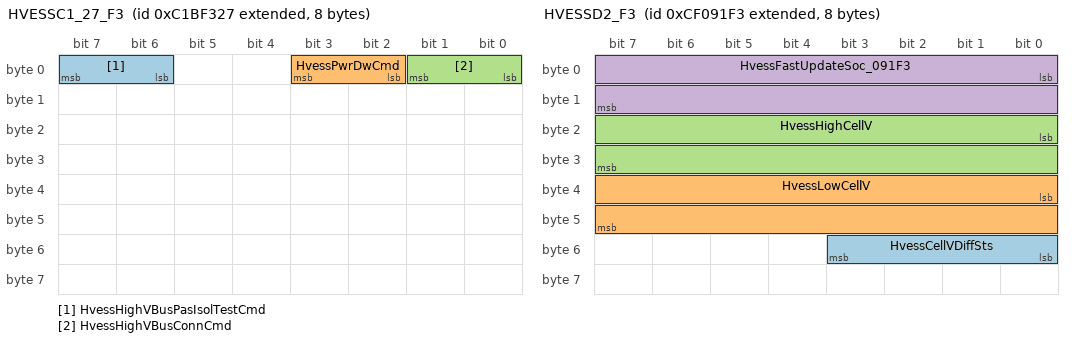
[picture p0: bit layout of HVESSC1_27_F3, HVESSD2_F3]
BO_ 2350641959 HVESSC1_27_F3: 8 VCM
 SG_ HvessHighVBusPasIsolTestCmd : 6|2@1+ (1,0) [0|3] ""  PCM,NODE_F3
 SG_ HvessPwrDwCmd : 2|2@1+ (1,0) [0|3] ""  PCM,NODE_F3
 SG_ HvessHighVBusConnCmd : 0|2@1+ (1,0) [0|3] ""  PCM,NODE_F3

BO_ 2350589939 HVESSC1_F3_27: 8 NODE_F3
 SG_ HvessCellBalCmd : 8|2@1+ (1,0) [0|3] ""  PCM,VCM

BO_ 2364576039 HVESSD2_27: 8 VCM
 SG_ HvessFastUpdateSoc : 0|16@1+ (0.0015625,0) [0|100.3984375] "%"  PCM

BO_ 2364576243 HVESSD2_F3: 8 NODE_F3
 SG_ HvessCellVDiffSts : 48|4@1+ (1,0) [0|15] ""  PCM
 SG_ HvessLowCellV : 32|16@1+ (0.001,0) [0|64.255] "V"  PCM
 SG_ HvessHighCellV : 16|16@1+ (0.001,0) [0|64.255] "V"  PCM
 SG_ HvessFastUpdateSoc_091F3 : 0|16@1+ (0.0015625,0) [0|100.3984375] "%"  PCM

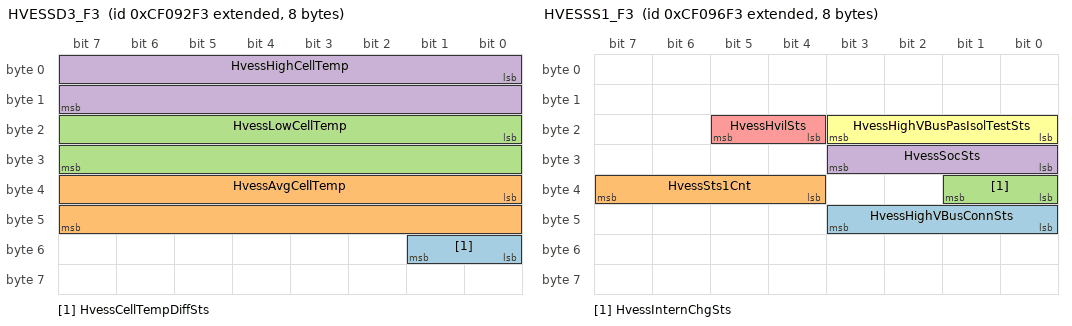
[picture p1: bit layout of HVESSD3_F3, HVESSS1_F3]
BO_ 2364576499 HVESSD3_F3: 8 NODE_F3
 SG_ HvessCellTempDiffSts : 48|2@1+ (1,0) [0|3] ""  PCM
 SG_ HvessAvgCellTemp : 32|16@1+ (0.03125,-273) [-273|1734.96875] "�C"  PCM
 SG_ HvessLowCellTemp : 16|16@1+ (0.03125,-273) [-273|1734.96875] "�C"  PCM
 SG_ HvessHighCellTemp : 0|16@1+ (0.03125,-273) [-273|1734.96875] "�C"  PCM

BO_ 2364577063 HVESSD6_27: 8 VCM
 SG_ HvessTemp : 56|8@1+ (1,-40) [-40|210] "�C"  PCM

BO_ 2364577523 HVESSS1_F3: 8 NODE_F3
 SG_ HvessHighVBusConnSts : 40|4@1+ (1,0) [0|15] ""  PCM
 SG_ HvessSts1Cnt : 36|4@1+ (1,0) [0|15] ""  PCM
 SG_ HvessInternChgSts : 32|2@1+ (1,0) [0|3] ""  PCM
 SG_ HvessSocSts : 24|4@1+ (1,0) [0|15] ""  PCM
 SG_ HvessHvilSts : 20|2@1+ (1,0) [0|3] ""  PCM
 SG_ HvessHighVBusPasIsolTestSts : 16|4@1+ (1,0) [0|15] ""  PCM

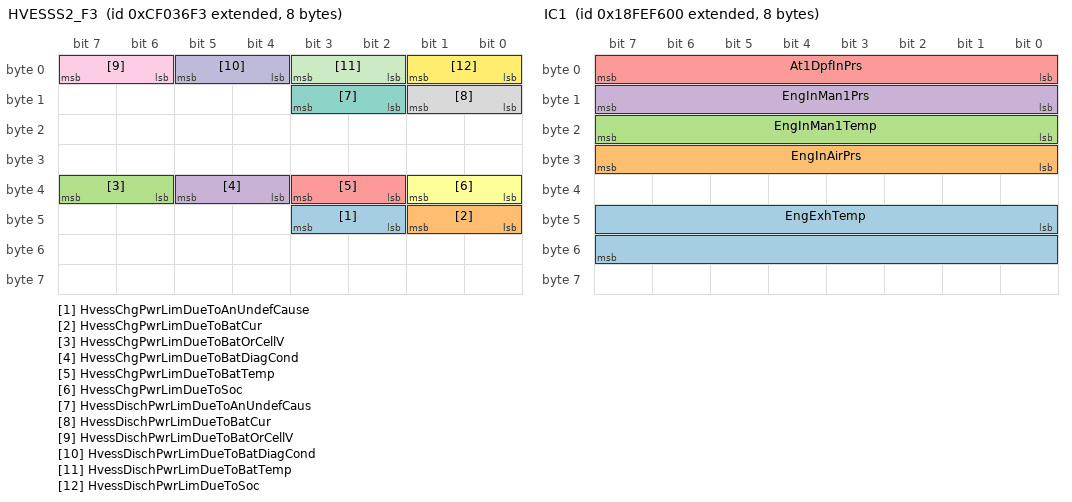
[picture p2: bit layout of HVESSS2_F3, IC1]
BO_ 2364552947 HVESSS2_F3: 8 NODE_F3
 SG_ HvessChgPwrLimDueToAnUndefCause : 42|2@1+ (1,0) [0|3] ""  PCM
 SG_ HvessChgPwrLimDueToBatCur : 40|2@1+ (1,0) [0|3] ""  PCM
 SG_ HvessChgPwrLimDueToBatOrCellV : 38|2@1+ (1,0) [0|3] ""  PCM
 SG_ HvessChgPwrLimDueToBatDiagCond : 36|2@1+ (1,0) [0|3] ""  PCM
 SG_ HvessChgPwrLimDueToBatTemp : 34|2@1+ (1,0) [0|3] ""  PCM
 SG_ HvessChgPwrLimDueToSoc : 32|2@1+ (1,0) [0|3] ""  PCM
 SG_ HvessDischPwrLimDueToAnUndefCaus : 10|2@1+ (1,0) [0|3] ""  PCM
 SG_ HvessDischPwrLimDueToBatCur : 8|2@1+ (1,0) [0|3] ""  PCM
 SG_ HvessDischPwrLimDueToBatOrCellV : 6|2@1+ (1,0) [0|3] ""  PCM
 SG_ HvessDischPwrLimDueToBatDiagCond : 4|2@1+ (1,0) [0|3] ""  PCM
 SG_ HvessDischPwrLimDueToBatTemp : 2|2@1+ (1,0) [0|3] ""  PCM
 SG_ HvessDischPwrLimDueToSoc : 0|2@1+ (1,0) [0|3] ""  PCM

BO_ 2566845952 IC1: 8 ECM
 SG_ EngExhTemp : 40|16@1+ (0.03125,-273) [-273|1734.96875] "�C"  PCM
 SG_ EngInAirPrs : 24|8@1+ (2,0) [0|500] "kPa"  PCM
 SG_ EngInMan1Temp : 16|8@1+ (1,-40) [-40|210] "�C"  PCM
 SG_ EngInMan1Prs : 8|8@1+ (2,0) [0|500] "kPa"  PCM
 SG_ At1DpfInPrs : 0|8@1+ (0.5,0) [0|125] "kPa"  PCM

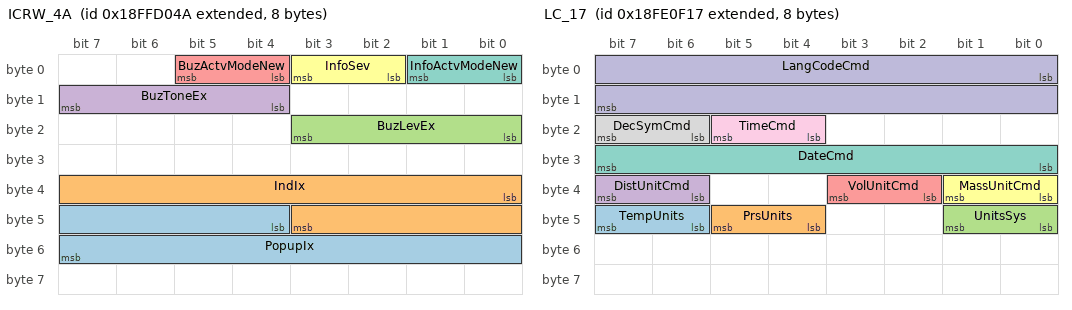
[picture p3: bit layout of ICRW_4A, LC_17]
BO_ 2566901834 ICRW_4A: 8 PCM
 SG_ PopupIx : 44|12@1+ (1,0) [0|4095] "" Vector__XXX
 SG_ IndIx : 32|12@1+ (1,0) [0|4095] "" Vector__XXX
 SG_ BuzLevEx : 16|4@1+ (1,0) [0|15] "Volume Units" Vector__XXX
 SG_ BuzToneEx : 12|4@1+ (1,0) [0|15] "" Vector__XXX
 SG_ BuzActvModeNew : 4|2@1+ (1,0) [0|3] "" Vector__XXX
 SG_ InfoSev : 2|2@1+ (1,0) [0|3] "" Vector__XXX
 SG_ InfoActvModeNew : 0|2@1+ (1,0) [0|3] "" Vector__XXX

BO_ 2566769185 ISC_21: 8 BCM
 SG_ EngOpPriInterSpeedSel : 0|4@1+ (1,0) [0|15] ""  PCM

BO_ 2566786839 LC_17: 8 ICC
 SG_ TempUnits : 46|2@1+ (1,0) [0|3] ""  PCM
 SG_ PrsUnits : 44|2@1+ (1,0) [0|3] ""  PCM
 SG_ UnitsSys : 40|2@1+ (1,0) [0|3] ""  PCM
 SG_ DistUnitCmd : 38|2@1+ (1,0) [0|3] ""  PCM
 SG_ VolUnitCmd : 34|2@1+ (1,0) [0|3] ""  PCM
 SG_ MassUnitCmd : 32|2@1+ (1,0) [0|3] ""  PCM
 SG_ DateCmd : 24|8@1+ (1,0) [0|255] "binary"  PCM
 SG_ DecSymCmd : 22|2@1+ (1,0) [0|3] ""  PCM
 SG_ TimeCmd : 20|2@1+ (1,0) [0|3] ""  PCM
 SG_ LangCodeCmd : 0|16@1+ (1,0) [0|255] "ASCII"  PCM

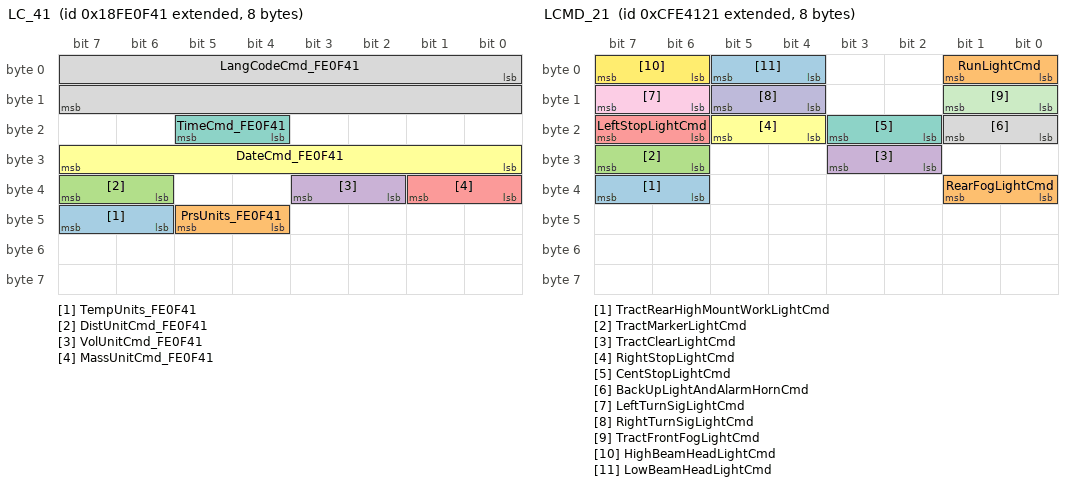
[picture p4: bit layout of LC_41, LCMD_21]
BO_ 2566786881 LC_41: 8 NIS_RDR
 SG_ TempUnits_FE0F41 : 46|2@1+ (1,0) [0|3] ""  PCM
 SG_ PrsUnits_FE0F41 : 44|2@1+ (1,0) [0|3] ""  PCM
 SG_ DistUnitCmd_FE0F41 : 38|2@1+ (1,0) [0|3] ""  PCM
 SG_ VolUnitCmd_FE0F41 : 34|2@1+ (1,0) [0|3] ""  PCM
 SG_ MassUnitCmd_FE0F41 : 32|2@1+ (1,0) [0|3] ""  PCM
 SG_ DateCmd_FE0F41 : 24|8@1+ (1,0) [0|255] "binary"  PCM
 SG_ TimeCmd_FE0F41 : 20|2@1+ (1,0) [0|3] ""  PCM
 SG_ LangCodeCmd_FE0F41 : 0|16@1+ (1,0) [0|255] "ASCII"  PCM

BO_ 2365473057 LCMD_21: 8 BCM
 SG_ TractRearHighMountWorkLightCmd : 38|2@1+ (1,0) [0|3] ""  PCM
 SG_ RearFogLightCmd : 32|2@1+ (1,0) [0|3] ""  PCM
 SG_ TractMarkerLightCmd : 30|2@1+ (1,0) [0|3] ""  PCM
 SG_ TractClearLightCmd : 26|2@1+ (1,0) [0|3] ""  PCM
 SG_ LeftStopLightCmd : 22|2@1+ (1,0) [0|3] ""  PCM
 SG_ RightStopLightCmd : 20|2@1+ (1,0) [0|3] ""  PCM
 SG_ CentStopLightCmd : 18|2@1+ (1,0) [0|3] ""  PCM
 SG_ BackUpLightAndAlarmHornCmd : 16|2@1+ (1,0) [0|3] ""  PCM
 SG_ LeftTurnSigLightCmd : 14|2@1+ (1,0) [0|3] ""  PCM
 SG_ RightTurnSigLightCmd : 12|2@1+ (1,0) [0|3] ""  PCM
 SG_ TractFrontFogLightCmd : 8|2@1+ (1,0) [0|3] ""  PCM
 SG_ HighBeamHeadLightCmd : 6|2@1+ (1,0) [0|3] ""  PCM
 SG_ LowBeamHeadLightCmd : 4|2@1+ (1,0) [0|3] ""  PCM
 SG_ RunLightCmd : 0|2@1+ (1,0) [0|3] ""  PCM

BO_ 2365473066 LCMD_2A: 8 LDW
 SG_ HighBeamHeadLightCmd_E412A : 6|2@1+ (1,0) [0|3] ""  PCM

BO_ 2566842624 LFC1: 8 ECM
 SG_ EngTotFuelUsed : 32|32@1+ (0.5,0) [0|2105540607.5] "L"  PCM

BO_ 2566844928 LFE1: 8 ECM
 SG_ EngInstFuelEcon_FEF200 : 16|16@1+ (0.001953125,0) [0|125.498046875] "km/L"  PCM
 SG_ EngFuelRate_FEF200 : 0|16@1+ (0.05,0) [0|3212.75] "L/h"  PCM

BO_ 2566615335 MG1IMT_27: 8 VCM
 SG_ Mot_Gen1Temp1 : 0|8@1+ (1,-40) [-40|210] "�C"  PCM

BO_ 2365289967 MG1IR1_EF: 8 NODE_EF
 SG_ Mot_Gen1InvRefSpeed : 32|16@1+ (4,0) [0|257020] "rpm"  PCM
 SG_ Mot_Gen1InvRefTrq : 16|16@1+ (0.5,0) [0|32127.5] "Nm"  PCM

BO_ 2365289970 MG1IR1_F2: 8 NODE_F2
 SG_ Mot_Gen1InvRefSpeed_B75F2 : 32|16@1+ (4,0) [0|257020] "rpm"  PCM
 SG_ Mot_Gen1InvRefTrq_B75F2 : 16|16@1+ (0.5,0) [0|32127.5] "Nm"  PCM

BO_ 2365289455 MG1IR2_EF: 8 NODE_EF
 SG_ Mot_Gen1InvRefV : 48|16@1+ (0.125,0) [0|8031.875] "V"  PCM
 SG_ Mot_Gen1InvRefCur : 32|16@1+ (0.125,0) [0|8031.875] "A"  PCM

BO_ 2365289458 MG1IR2_F2: 8 NODE_F2
 SG_ Mot_Gen1InvRefV_B73F2 : 48|16@1+ (0.125,0) [0|8031.875] "V"  PCM
 SG_ Mot_Gen1InvRefCur_B73F2 : 32|16@1+ (0.125,0) [0|8031.875] "A"  PCM

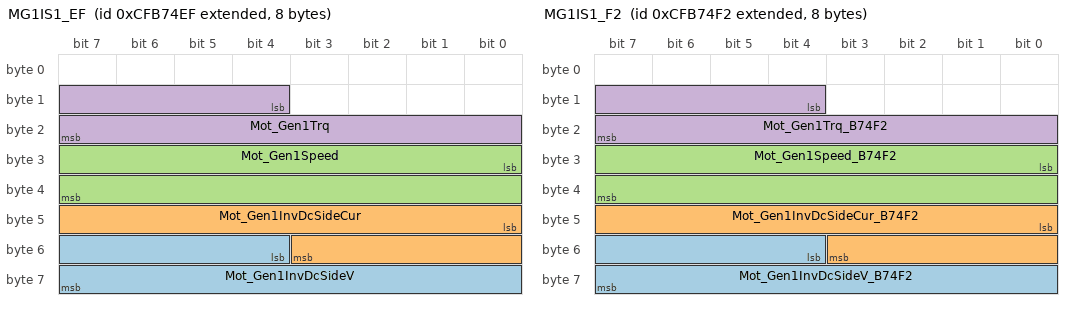
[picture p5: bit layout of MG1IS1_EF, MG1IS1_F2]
BO_ 2365289711 MG1IS1_EF: 8 NODE_EF
 SG_ Mot_Gen1InvDcSideV : 52|12@1+ (0.0625,-125) [-125|125.9375] "%"  PCM
 SG_ Mot_Gen1InvDcSideCur : 40|12@1+ (0.0625,-125) [-125|125.9375] "%"  PCM
 SG_ Mot_Gen1Speed : 24|16@1+ (0.00390625,-125) [-125|125.99609375] "%"  PCM
 SG_ Mot_Gen1Trq : 12|12@1+ (0.0625,-125) [-125|125.9375] "%"  PCM

BO_ 2365289714 MG1IS1_F2: 8 NODE_F2
 SG_ Mot_Gen1InvDcSideV_B74F2 : 52|12@1+ (0.0625,-125) [-125|125.9375] "%"  PCM
 SG_ Mot_Gen1InvDcSideCur_B74F2 : 40|12@1+ (0.0625,-125) [-125|125.9375] "%"  PCM
 SG_ Mot_Gen1Speed_B74F2 : 24|16@1+ (0.00390625,-125) [-125|125.99609375] "%"  PCM
 SG_ Mot_Gen1Trq_B74F2 : 12|12@1+ (0.0625,-125) [-125|125.9375] "%"  PCM

BO_ 2565966831 MG1IS2_EF: 8 NODE_EF
 SG_ Mot_Gen1AvMinTrq : 24|12@1+ (0.0625,-125) [-125|125.9375] "%"  PCM
 SG_ Mot_Gen1AvMaxTrq : 12|12@1+ (0.0625,-125) [-125|125.9375] "%"  PCM

BO_ 2565966834 MG1IS2_F2: 8 NODE_F2
 SG_ Mot_Gen1AvMinTrq_F18BF2 : 24|12@1+ (0.0625,-125) [-125|125.9375] "%"  PCM
 SG_ Mot_Gen1AvMaxTrq_F18BF2 : 12|12@1+ (0.0625,-125) [-125|125.9375] "%"  PCM

BO_ 2566615591 MG1IT_27: 8 VCM
 SG_ Mot_Gen1InvTemp1 : 0|8@1+ (1,-40) [-40|210] "�C"  PCM

BO_ 2566802465 ML_21: 8 BCM
 SG_ OpsBlackOutIntensSel : 56|8@1+ (0.4,0) [0|100] "%"  PCM

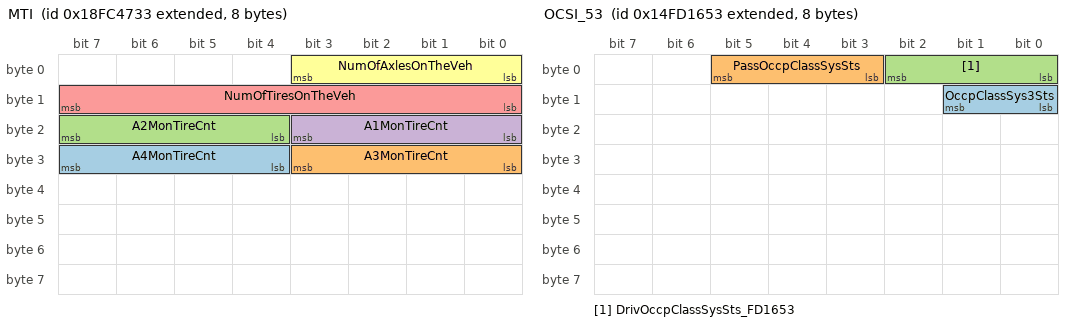
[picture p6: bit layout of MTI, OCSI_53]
BO_ 2566670131 MTI: 8 OptiTire
 SG_ A4MonTireCnt : 28|4@1+ (1,0) [0|13] "count"  PCM
 SG_ A3MonTireCnt : 24|4@1+ (1,0) [0|13] "count"  PCM
 SG_ A2MonTireCnt : 20|4@1+ (1,0) [0|13] "count"  PCM
 SG_ A1MonTireCnt : 16|4@1+ (1,0) [0|13] "count"  PCM
 SG_ NumOfTiresOnTheVeh : 8|8@1+ (1,0) [0|250] "count"  PCM
 SG_ NumOfAxlesOnTheVeh : 0|4@1+ (1,0) [0|13] "count"  PCM

BO_ 2566898977 MuxInfo2: 8 BCM
 SG_ MsgCks_FFC521 : 60|4@1+ (1,0) [0|15] "count"  PCM
 SG_ MsgCnt_FFC521 : 56|4@1+ (1,0) [0|15] "count"  PCM
 SG_ EmerShutdnSwSts : 54|2@1+ (1,0) [0|3] ""  PCM
 SG_ WiperCtrlSts : 51|3@1+ (1,0) [0|7] ""  PCM
 SG_ EassVisCode : 48|3@1+ (1,0) [0|7] ""  PCM
 SG_ EassActvSts : 46|2@1+ (1,0) [0|3] ""  PCM
 SG_ EmerHandKeyLckdSts : 44|2@1+ (1,0) [0|3] ""  PCM
 SG_ BatLampSts : 42|2@1+ (1,0) [0|3] ""  PCM
 SG_ PwrModeSts : 40|2@1+ (1,0) [0|3] ""  PCM
 SG_ FpsSts : 39|1@1+ (1,0) [0|1] ""  PCM
 SG_ ImmoCodeWarnLightSts : 32|4@1+ (1,0) [0|15] ""  PCM
 SG_ BrkPadWearSts : 30|2@1+ (1,0) [0|3] ""  PCM
 SG_ BrkFluidLevLow : 28|2@1+ (1,0) [0|3] ""  PCM
 SG_ CeilLightSts : 26|2@1+ (1,0) [0|3] ""  PCM
 SG_ SysEolSts : 25|1@1+ (1,0) [0|1] ""  PCM
 SG_ BrkPedSts : 24|1@1+ (1,0) [0|1] ""  PCM
 SG_ CrashOutSts : 16|8@1+ (1,0) [0|255] ""  PCM
 SG_ WiperCtrl : 14|2@1+ (1,0) [0|3] ""  PCM
 SG_ VehAtStStill : 12|2@1+ (1,0) [0|3] ""  PCM
 SG_ PlugDoorBtn : 10|2@1+ (1,0) [0|3] ""  PCM
 SG_ EngWaterLev : 8|2@1+ (1,0) [0|3] ""  PCM
 SG_ SpotStsRear : 6|2@1+ (1,0) [0|3] ""  PCM
 SG_ PtoDrivResp : 4|2@1+ (1,0) [0|3] ""  PCM
 SG_ SeatBeltRemindSts : 2|2@1+ (1,0) [0|3] ""  PCM
 SG_ InternLightSts : 1|1@1+ (1,0) [0|1] ""  PCM
 SG_ RechargeSts : 0|1@1+ (1,0) [0|1] ""  PCM

BO_ 2566776106 MVS_2A: 8 LDW
 SG_ MaxVsl3 : 16|8@1+ (1,0) [0|250] "km/h"  PCM
 SG_ MaxVsl2 : 8|8@1+ (1,0) [0|250] "km/h"  PCM

BO_ 2499614241 OCSI_21: 8 BCM
 SG_ DrivOccpClassSysSts : 0|3@1+ (1,0) [0|7] ""  PCM

BO_ 2499614291 OCSI_53: 8 Airbag
 SG_ OccpClassSys3Sts : 8|2@1+ (1,0) [0|3] ""  PCM
 SG_ PassOccpClassSysSts : 3|3@1+ (1,0) [0|7] ""  PCM
 SG_ DrivOccpClassSysSts_FD1653 : 0|3@1+ (1,0) [0|7] ""  PCM

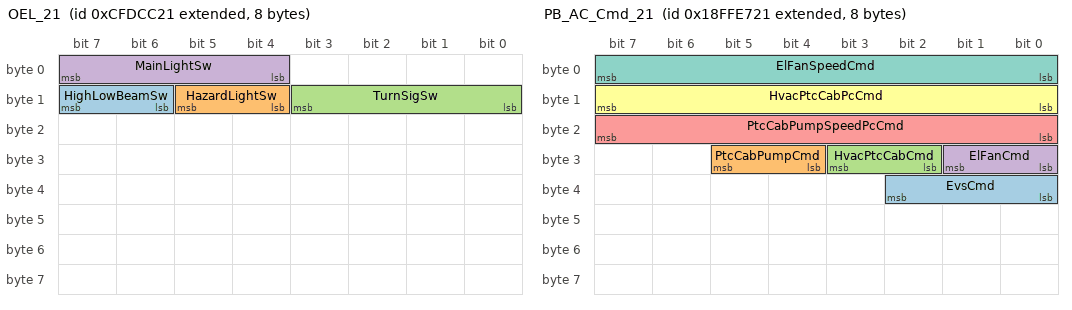
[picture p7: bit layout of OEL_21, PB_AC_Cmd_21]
BO_ 2365443105 OEL_21: 8 BCM
 SG_ HighLowBeamSw : 14|2@1+ (1,0) [0|3] ""  PCM
 SG_ HazardLightSw : 12|2@1+ (1,0) [0|3] ""  PCM
 SG_ TurnSigSw : 8|4@1+ (1,0) [0|15] ""  PCM
 SG_ MainLightSw : 4|4@1+ (1,0) [0|15] ""  PCM

BO_ 2566769953 OWW_21: 8 BCM
 SG_ FrontOpWiperSw : 4|4@1+ (1,0) [0|15] ""  PCM

BO_ 2565865249 PA_E_21: 8 BCM
 SG_ ImmoEmerProc m0 : 48|8@1+ (5,0) [0|1250] "s"  PCM
 SG_ CtrlByte M : 0|8@1+ (1,0) [0|255] "binary"  PCM

BO_ 2566907681 PB_AC_Cmd_21: 8 BCM
 SG_ EvsCmd : 32|3@1+ (1,0) [0|7] ""  PCM
 SG_ PtcCabPumpCmd : 28|2@1+ (1,0) [0|3] ""  PCM
 SG_ HvacPtcCabCmd : 26|2@1+ (1,0) [0|3] ""  PCM
 SG_ ElFanCmd : 24|2@1+ (1,0) [0|3] ""  PCM
 SG_ PtcCabPumpSpeedPcCmd : 16|8@1+ (0.4,0) [0|100] "%"  PCM
 SG_ HvacPtcCabPcCmd : 8|8@1+ (0.4,0) [0|100] "%"  PCM
 SG_ ElFanSpeedCmd : 0|8@1+ (0.4,0) [0|100] "%"  PCM

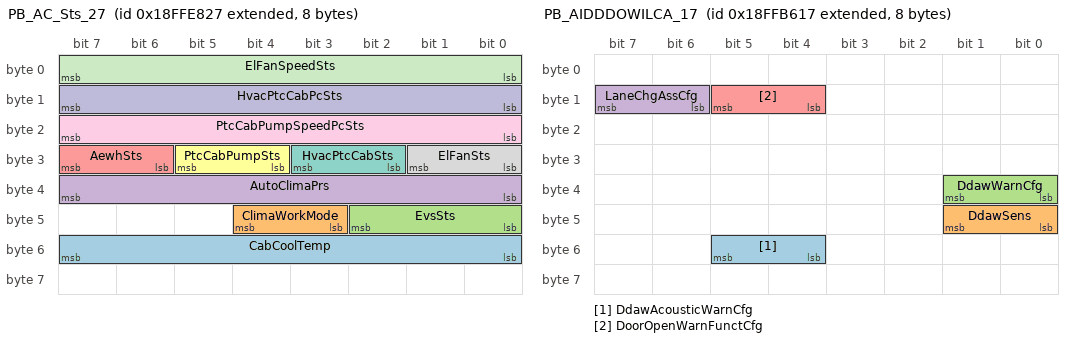
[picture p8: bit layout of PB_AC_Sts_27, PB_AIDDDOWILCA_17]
BO_ 2566907943 PB_AC_Sts_27: 8 VCM
 SG_ CabCoolTemp : 48|8@1+ (1,-40) [-40|210] "�C"  PCM
 SG_ ClimaWorkMode : 43|2@1+ (1,0) [0|3] ""  PCM
 SG_ EvsSts : 40|3@1+ (1,0) [0|7] ""  PCM
 SG_ AutoClimaPrs : 32|8@1+ (12,0) [0|3000] "kPa"  PCM
 SG_ AewhSts : 30|2@1+ (1,0) [0|3] ""  PCM
 SG_ PtcCabPumpSts : 28|2@1+ (1,0) [0|3] ""  PCM
 SG_ HvacPtcCabSts : 26|2@1+ (1,0) [0|3] ""  PCM
 SG_ ElFanSts : 24|2@1+ (1,0) [0|3] ""  PCM
 SG_ PtcCabPumpSpeedPcSts : 16|8@1+ (0.4,0) [0|100] "%"  PCM
 SG_ HvacPtcCabPcSts : 8|8@1+ (0.4,0) [0|100] "%"  PCM
 SG_ ElFanSpeedSts : 0|8@1+ (0.4,0) [0|100] "%"  PCM

BO_ 2566895127 PB_AIDDDOWILCA_17: 8 ICC
 SG_ DdawAcousticWarnCfg : 52|2@1+ (1,0) [0|3] ""  PCM
 SG_ DdawSens : 40|2@1+ (1,0) [0|3] ""  PCM
 SG_ DdawWarnCfg : 32|2@1+ (1,0) [0|3] ""  PCM
 SG_ LaneChgAssCfg : 14|2@1+ (1,0) [0|3] ""  PCM
 SG_ DoorOpenWarnFunctCfg : 12|2@1+ (1,0) [0|3] ""  PCM

BO_ 2566895137 PB_AIDDDOWILCA_21: 8 BCM
 SG_ AlcoholIntLckCrkEnaSts : 42|3@1+ (1,0) [0|7] ""  PCM

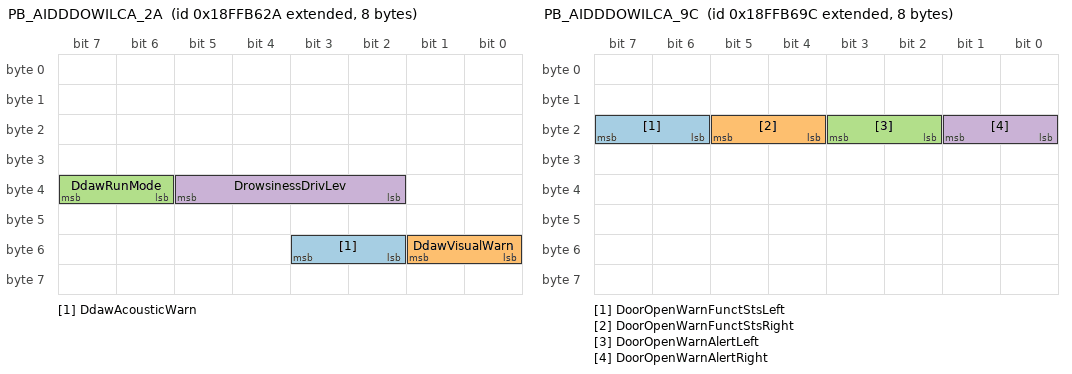
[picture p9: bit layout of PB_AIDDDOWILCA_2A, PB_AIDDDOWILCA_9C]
BO_ 2566895146 PB_AIDDDOWILCA_2A: 8 LDW
 SG_ DdawAcousticWarn : 50|2@1+ (1,0) [0|3] ""  PCM
 SG_ DdawVisualWarn : 48|2@1+ (1,0) [0|3] ""  PCM
 SG_ DdawRunMode : 38|2@1+ (1,0) [0|3] ""  PCM
 SG_ DrowsinessDrivLev : 34|4@1+ (1,0) [0|15] ""  PCM

BO_ 2566895178 PB_AIDDDOWILCA_4A: 8 PCM
 SG_ DoorOpenWarnFunctCfg_FFB64A : 12|2@1+ (1,0) [0|3] "" Vector__XXX

BO_ 2566895260 PB_AIDDDOWILCA_9C: 8 RSRRM
 SG_ DoorOpenWarnFunctStsLeft : 22|2@1+ (1,0) [0|3] ""  PCM
 SG_ DoorOpenWarnFunctStsRight : 20|2@1+ (1,0) [0|3] ""  PCM
 SG_ DoorOpenWarnAlertLeft : 18|2@1+ (1,0) [0|3] ""  PCM
 SG_ DoorOpenWarnAlertRight : 16|2@1+ (1,0) [0|3] ""  PCM

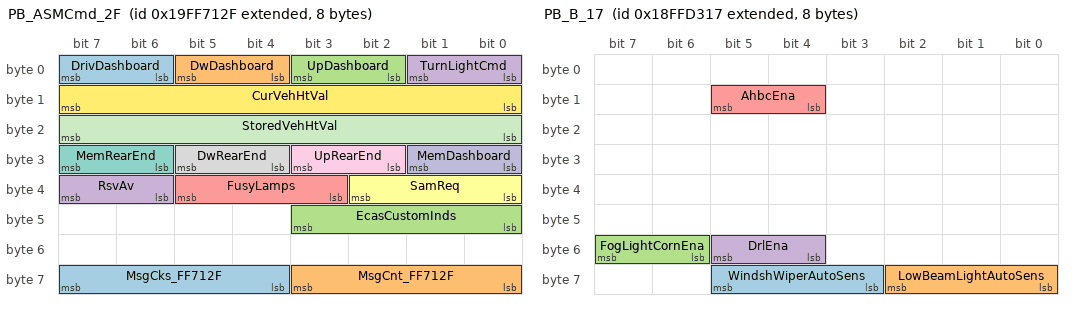
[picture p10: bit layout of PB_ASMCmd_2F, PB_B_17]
BO_ 2583654703 PB_ASMCmd_2F: 8 ECAS
 SG_ MsgCks_FF712F : 60|4@1+ (1,0) [0|15] "count"  PCM
 SG_ MsgCnt_FF712F : 56|4@1+ (1,0) [0|15] "count"  PCM
 SG_ EcasCustomInds : 40|4@1+ (1,0) [0|15] ""  PCM
 SG_ RsvAv : 38|2@1+ (1,0) [0|3] ""  PCM
 SG_ FusyLamps : 35|3@1+ (1,0) [0|7] ""  PCM
 SG_ SamReq : 32|3@1+ (1,0) [0|7] ""  PCM
 SG_ MemRearEnd : 30|2@1+ (1,0) [0|3] ""  PCM
 SG_ DwRearEnd : 28|2@1+ (1,0) [0|3] ""  PCM
 SG_ UpRearEnd : 26|2@1+ (1,0) [0|3] ""  PCM
 SG_ MemDashboard : 24|2@1+ (1,0) [0|3] ""  PCM
 SG_ StoredVehHtVal : 16|8@1+ (1,0) [0|250] "%"  PCM
 SG_ CurVehHtVal : 8|8@1+ (1,0) [0|250] "%"  PCM
 SG_ DrivDashboard : 6|2@1+ (1,0) [0|3] ""  PCM
 SG_ DwDashboard : 4|2@1+ (1,0) [0|3] ""  PCM
 SG_ UpDashboard : 2|2@1+ (1,0) [0|3] ""  PCM
 SG_ TurnLightCmd : 0|2@1+ (1,0) [0|3] ""  PCM

BO_ 2566902551 PB_B_17: 8 ICC
 SG_ WindshWiperAutoSens : 59|3@1+ (1,0) [0|7] ""  PCM
 SG_ LowBeamLightAutoSens : 56|3@1+ (1,0) [0|7] ""  PCM
 SG_ FogLightCornEna : 54|2@1+ (1,0) [0|3] ""  PCM
 SG_ DrlEna : 52|2@1+ (1,0) [0|3] ""  PCM
 SG_ AhbcEna : 12|2@1+ (1,0) [0|3] ""  PCM

BO_ 2566902602 PB_B_4A: 8 PCM
 SG_ AhbcEna_FFD34A : 12|2@1+ (1,0) [0|3] "" Vector__XXX

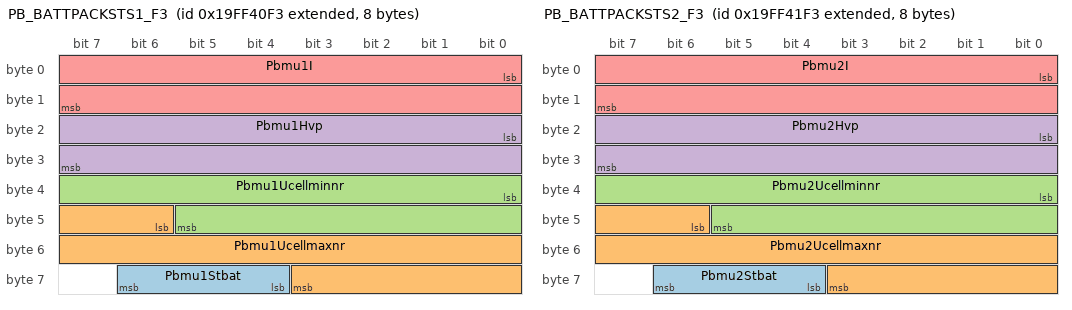
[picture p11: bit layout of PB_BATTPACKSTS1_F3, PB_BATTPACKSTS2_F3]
BO_ 2583642355 PB_BATTPACKSTS1_F3: 8 NODE_F3
 SG_ Pbmu1Stbat : 60|3@1+ (1,0) [0|7] ""  PCM
 SG_ Pbmu1Ucellmaxnr : 46|14@1+ (1,0) [0|600] ""  PCM
 SG_ Pbmu1Ucellminnr : 32|14@1+ (1,0) [0|600] ""  PCM
 SG_ Pbmu1Hvp : 16|16@1+ (1,0) [0|1000] "V"  PCM
 SG_ Pbmu1I : 0|16@1+ (1,-1000) [-1000|1000] "A"  PCM

BO_ 2583642611 PB_BATTPACKSTS2_F3: 8 NODE_F3
 SG_ Pbmu2Stbat : 60|3@1+ (1,0) [0|7] ""  PCM
 SG_ Pbmu2Ucellmaxnr : 46|14@1+ (1,0) [0|600] ""  PCM
 SG_ Pbmu2Ucellminnr : 32|14@1+ (1,0) [0|600] ""  PCM
 SG_ Pbmu2Hvp : 16|16@1+ (1,0) [0|1000] "V"  PCM
 SG_ Pbmu2I : 0|16@1+ (1,-1000) [-1000|1000] "A"  PCM

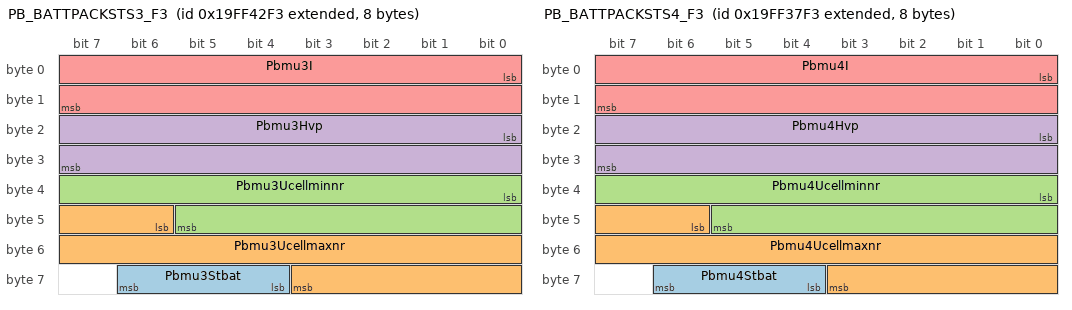
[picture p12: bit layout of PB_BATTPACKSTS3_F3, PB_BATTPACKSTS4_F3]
BO_ 2583642867 PB_BATTPACKSTS3_F3: 8 NODE_F3
 SG_ Pbmu3Stbat : 60|3@1+ (1,0) [0|7] ""  PCM
 SG_ Pbmu3Ucellmaxnr : 46|14@1+ (1,0) [0|600] ""  PCM
 SG_ Pbmu3Ucellminnr : 32|14@1+ (1,0) [0|600] ""  PCM
 SG_ Pbmu3Hvp : 16|16@1+ (1,0) [0|1000] "V"  PCM
 SG_ Pbmu3I : 0|16@1+ (1,-1000) [-1000|1000] "A"  PCM

BO_ 2583640051 PB_BATTPACKSTS4_F3: 8 NODE_F3
 SG_ Pbmu4Stbat : 60|3@1+ (1,0) [0|7] ""  PCM
 SG_ Pbmu4Ucellmaxnr : 46|14@1+ (1,0) [0|600] ""  PCM
 SG_ Pbmu4Ucellminnr : 32|14@1+ (1,0) [0|600] ""  PCM
 SG_ Pbmu4Hvp : 16|16@1+ (1,0) [0|1000] "V"  PCM
 SG_ Pbmu4I : 0|16@1+ (1,-1000) [-1000|1000] "A"  PCM

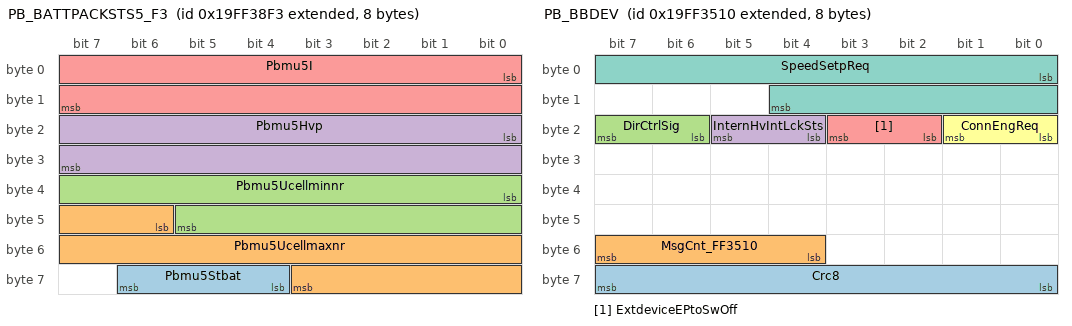
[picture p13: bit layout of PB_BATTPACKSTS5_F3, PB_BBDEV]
BO_ 2583640307 PB_BATTPACKSTS5_F3: 8 NODE_F3
 SG_ Pbmu5Stbat : 60|3@1+ (1,0) [0|7] ""  PCM
 SG_ Pbmu5Ucellmaxnr : 46|14@1+ (1,0) [0|600] ""  PCM
 SG_ Pbmu5Ucellminnr : 32|14@1+ (1,0) [0|600] ""  PCM
 SG_ Pbmu5Hvp : 16|16@1+ (1,0) [0|1000] "V"  PCM
 SG_ Pbmu5I : 0|16@1+ (1,-1000) [-1000|1000] "A"  PCM

BO_ 2583639312 PB_BBDEV: 8 EST54_IRCS
 SG_ Crc8 : 56|8@1+ (1,0) [0|255] ""  PCM
 SG_ MsgCnt_FF3510 : 52|4@1+ (1,0) [0|15] "count"  PCM
 SG_ DirCtrlSig : 22|2@1+ (1,0) [0|3] ""  PCM
 SG_ InternHvIntLckSts : 20|2@1+ (1,0) [0|3] ""  PCM
 SG_ ExtdeviceEPtoSwOff : 18|2@1+ (1,0) [0|3] ""  PCM
 SG_ ConnEngReq : 16|2@1+ (1,0) [0|3] ""  PCM
 SG_ SpeedSetpReq : 0|13@1+ (1,0) [0|8191] "rpm"  PCM

BO_ 2583639370 PB_BBDEV_4A: 8 PCM
 SG_ ExtdeviceEPtoSwOff_FF354A : 18|2@1+ (1,0) [0|3] "" Vector__XXX

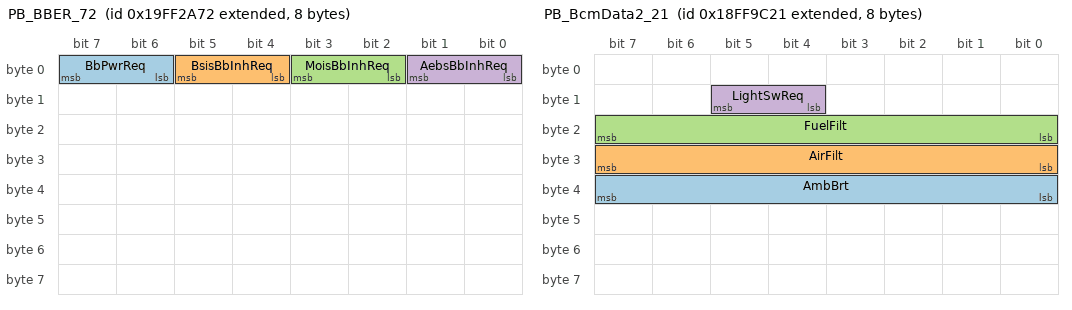
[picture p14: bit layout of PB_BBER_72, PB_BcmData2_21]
BO_ 2583636594 PB_BBER_72: 8 EM_PTO
 SG_ BbPwrReq : 6|2@1+ (1,0) [0|3] ""  PCM
 SG_ BsisBbInhReq : 4|2@1+ (1,0) [0|3] ""  PCM
 SG_ MoisBbInhReq : 2|2@1+ (1,0) [0|3] ""  PCM
 SG_ AebsBbInhReq : 0|2@1+ (1,0) [0|3] ""  PCM

BO_ 2566894625 PB_BCMData_21: 8 BCM
 SG_ RearCeilLight : 62|2@1+ (1,0) [0|3] ""  PCM
 SG_ CentCeilLight : 60|2@1+ (1,0) [0|3] ""  PCM
 SG_ LatRightCeilLight : 58|2@1+ (1,0) [0|3] ""  PCM
 SG_ LatLeftCeilLight : 56|2@1+ (1,0) [0|3] ""  PCM
 SG_ BcmDowFail : 54|2@1+ (1,0) [0|3] ""  PCM
 SG_ BcmRctFail : 52|2@1+ (1,0) [0|3] ""  PCM
 SG_ BcmBsisFail : 50|2@1+ (1,0) [0|3] ""  PCM
 SG_ BcmBsFail : 48|2@1+ (1,0) [0|3] ""  PCM
 SG_ FrontCeilLight : 46|2@1+ (1,0) [0|3] ""  PCM
 SG_ RearDiffLckCtrlFail : 44|2@1+ (1,0) [0|3] ""  PCM
 SG_ VehBatVLowLampSts : 42|2@1+ (1,0) [0|3] ""  PCM
 SG_ BrkSw_FFB421 : 40|2@1+ (1,0) [0|3] ""  PCM
 SG_ RearDiffLckSts : 38|2@1+ (1,0) [0|3] ""  PCM
 SG_ EngWaterLev_FFB421 : 36|2@1+ (1,0) [0|3] ""  PCM
 SG_ HeadbeamAdjPos : 33|3@1+ (1,0) [0|7] ""  PCM
 SG_ DieselFiltBlk : 32|1@1+ (1,0) [0|1] ""  PCM
 SG_ AirFiltBlk : 31|1@1+ (1,0) [0|1] ""  PCM
 SG_ PtcFail : 30|1@1+ (1,0) [0|1] ""  PCM
 SG_ PtcSts : 28|2@1+ (1,0) [0|3] ""  PCM
 SG_ CondNeededForEnaAutoStop : 27|1@1+ (1,0) [0|1] ""  PCM
 SG_ CrkPossInAutoStop : 26|1@1+ (1,0) [0|1] ""  PCM
 SG_ CrkModeAllwInAutoStop : 25|1@1+ (1,0) [0|1] ""  PCM
 SG_ EassMngReq : 24|1@1+ (1,0) [0|1] ""  PCM
 SG_ EassSafeModeIndSts : 22|2@1+ (1,0) [0|3] ""  PCM
 SG_ RearHeatWndSts : 21|1@1+ (1,0) [0|1] ""  PCM
 SG_ DrivStyleSts : 18|3@1+ (1,0) [0|3] ""  PCM
 SG_ ComprAcReqSts : 16|2@1+ (1,0) [0|3] ""  PCM
 SG_ GearModesReq : 14|2@1+ (1,0) [0|3] ""  PCM
 SG_ EcoLckEng : 12|2@1+ (1,0) [0|3] ""  PCM

BO_ 2566888481 PB_BcmData2_21: 8 BCM
 SG_ AmbBrt : 32|8@1+ (100,0) [0|25000] "lx"  PCM
 SG_ AirFilt : 24|8@1+ (0.02,0) [0|5] "V"  PCM
 SG_ FuelFilt : 16|8@1+ (0.02,0) [0|5] "V"  PCM
 SG_ LightSwReq : 12|2@1+ (1,0) [0|3] ""  PCM

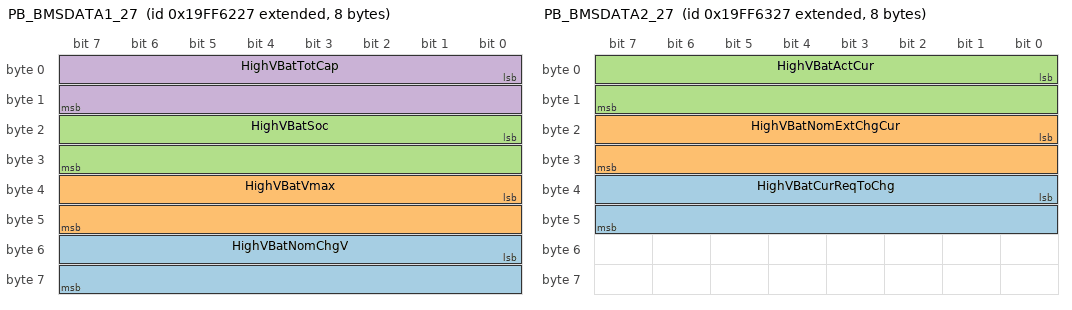
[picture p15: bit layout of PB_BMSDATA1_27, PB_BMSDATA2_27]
BO_ 2583650855 PB_BMSDATA1_27: 8 VCM
 SG_ HighVBatNomChgV : 48|16@1- (0.03125,0) [-32768|32767] "V"  PCM
 SG_ HighVBatVmax : 32|16@1- (0.03125,0) [-32768|32767] "V"  PCM
 SG_ HighVBatSoc : 16|16@1- (0.012207,0) [-32768|32767] "%"  PCM
 SG_ HighVBatTotCap : 0|16@1- (0.0125,0) [-32768|32767] "Ah"  PCM

BO_ 2583651111 PB_BMSDATA2_27: 8 VCM
 SG_ HighVBatCurReqToChg : 32|16@1- (0.03125,0) [-32768|32767] "A"  PCM
 SG_ HighVBatNomExtChgCur : 16|16@1- (0.03125,0) [-32768|32767] "A"  PCM
 SG_ HighVBatActCur : 0|16@1- (0.03125,0) [-32768|32767] "A"  PCM

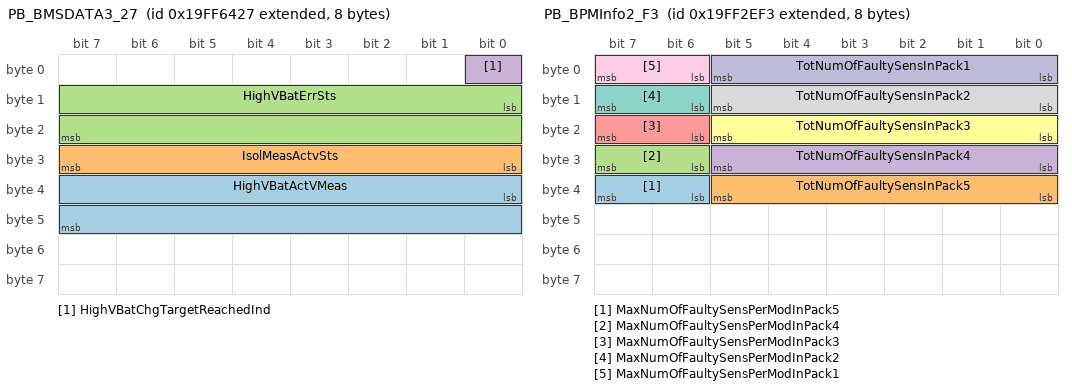
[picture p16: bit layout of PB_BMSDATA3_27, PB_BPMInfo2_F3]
BO_ 2583651367 PB_BMSDATA3_27: 8 VCM
 SG_ HighVBatActVMeas : 32|16@1- (0.03125,0) [-32768|32767] "V"  PCM
 SG_ IsolMeasActvSts : 24|8@1+ (1,0) [0|255] ""  PCM
 SG_ HighVBatErrSts : 8|16@1+ (1,0) [0|65535] ""  PCM
 SG_ HighVBatChgTargetReachedInd : 0|1@1+ (1,0) [0|1] ""  PCM

BO_ 2583637747 PB_BPMInfo2_F3: 8 NODE_F3
 SG_ MaxNumOfFaultySensPerModInPack5 : 38|2@1+ (1,0) [0|3] ""  PCM
 SG_ TotNumOfFaultySensInPack5 : 32|6@1+ (1,0) [0|63] ""  PCM
 SG_ MaxNumOfFaultySensPerModInPack4 : 30|2@1+ (1,0) [0|3] ""  PCM
 SG_ TotNumOfFaultySensInPack4 : 24|6@1+ (1,0) [0|63] ""  PCM
 SG_ MaxNumOfFaultySensPerModInPack3 : 22|2@1+ (1,0) [0|3] ""  PCM
 SG_ TotNumOfFaultySensInPack3 : 16|6@1+ (1,0) [0|63] ""  PCM
 SG_ MaxNumOfFaultySensPerModInPack2 : 14|2@1+ (1,0) [0|3] ""  PCM
 SG_ TotNumOfFaultySensInPack2 : 8|6@1+ (1,0) [0|63] ""  PCM
 SG_ MaxNumOfFaultySensPerModInPack1 : 6|2@1+ (1,0) [0|3] ""  PCM
 SG_ TotNumOfFaultySensInPack1 : 0|6@1+ (1,0) [0|63] ""  PCM

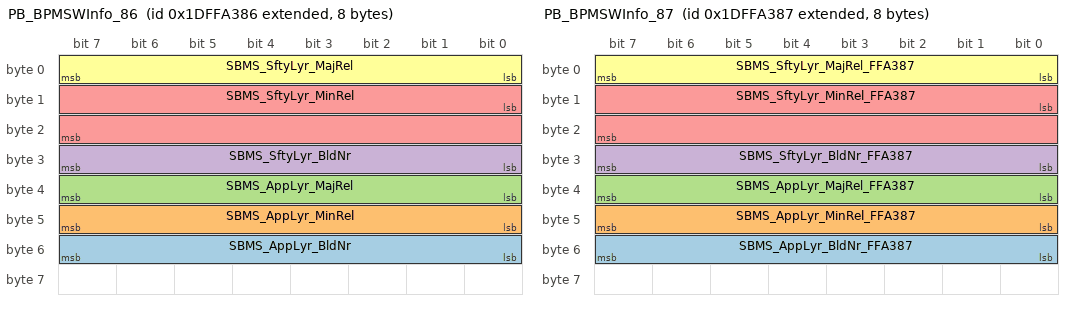
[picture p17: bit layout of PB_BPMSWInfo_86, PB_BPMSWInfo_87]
BO_ 2650776454 PB_BPMSWInfo_86: 8 NODE_86
 SG_ SBMS_AppLyr_BldNr : 48|8@1+ (1,0) [0|255] ""  PCM
 SG_ SBMS_AppLyr_MinRel : 40|8@1+ (1,0) [0|255] ""  PCM
 SG_ SBMS_AppLyr_MajRel : 32|8@1+ (1,0) [0|255] ""  PCM
 SG_ SBMS_SftyLyr_BldNr : 24|8@1+ (1,0) [0|255] ""  PCM
 SG_ SBMS_SftyLyr_MinRel : 8|16@1+ (1,0) [0|65535] ""  PCM
 SG_ SBMS_SftyLyr_MajRel : 0|8@1+ (1,0) [0|255] ""  PCM

BO_ 2650776455 PB_BPMSWInfo_87: 8 NODE_87
 SG_ SBMS_AppLyr_BldNr_FFA387 : 48|8@1+ (1,0) [0|255] ""  PCM
 SG_ SBMS_AppLyr_MinRel_FFA387 : 40|8@1+ (1,0) [0|255] ""  PCM
 SG_ SBMS_AppLyr_MajRel_FFA387 : 32|8@1+ (1,0) [0|255] ""  PCM
 SG_ SBMS_SftyLyr_BldNr_FFA387 : 24|8@1+ (1,0) [0|255] ""  PCM
 SG_ SBMS_SftyLyr_MinRel_FFA387 : 8|16@1+ (1,0) [0|65535] ""  PCM
 SG_ SBMS_SftyLyr_MajRel_FFA387 : 0|8@1+ (1,0) [0|255] ""  PCM

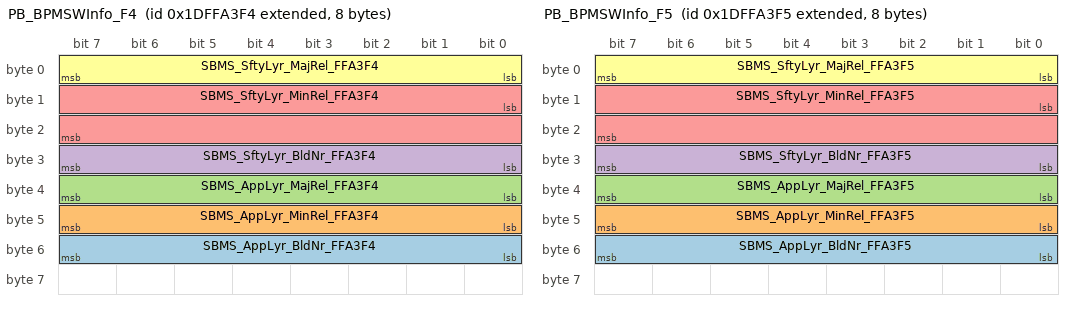
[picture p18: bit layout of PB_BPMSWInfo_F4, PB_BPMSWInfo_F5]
BO_ 2650776564 PB_BPMSWInfo_F4: 8 NODE_F4
 SG_ SBMS_AppLyr_BldNr_FFA3F4 : 48|8@1+ (1,0) [0|255] ""  PCM
 SG_ SBMS_AppLyr_MinRel_FFA3F4 : 40|8@1+ (1,0) [0|255] ""  PCM
 SG_ SBMS_AppLyr_MajRel_FFA3F4 : 32|8@1+ (1,0) [0|255] ""  PCM
 SG_ SBMS_SftyLyr_BldNr_FFA3F4 : 24|8@1+ (1,0) [0|255] ""  PCM
 SG_ SBMS_SftyLyr_MinRel_FFA3F4 : 8|16@1+ (1,0) [0|65535] ""  PCM
 SG_ SBMS_SftyLyr_MajRel_FFA3F4 : 0|8@1+ (1,0) [0|255] ""  PCM

BO_ 2650776565 PB_BPMSWInfo_F5: 8 NODE_F5
 SG_ SBMS_AppLyr_BldNr_FFA3F5 : 48|8@1+ (1,0) [0|255] ""  PCM
 SG_ SBMS_AppLyr_MinRel_FFA3F5 : 40|8@1+ (1,0) [0|255] ""  PCM
 SG_ SBMS_AppLyr_MajRel_FFA3F5 : 32|8@1+ (1,0) [0|255] ""  PCM
 SG_ SBMS_SftyLyr_BldNr_FFA3F5 : 24|8@1+ (1,0) [0|255] ""  PCM
 SG_ SBMS_SftyLyr_MinRel_FFA3F5 : 8|16@1+ (1,0) [0|65535] ""  PCM
 SG_ SBMS_SftyLyr_MajRel_FFA3F5 : 0|8@1+ (1,0) [0|255] ""  PCM

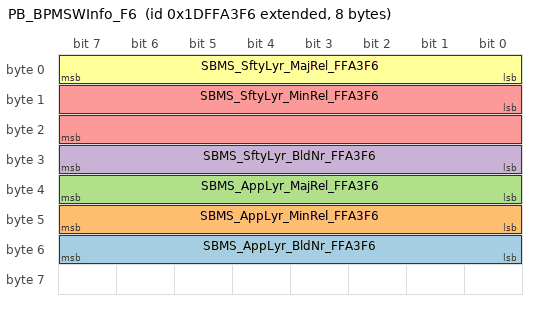
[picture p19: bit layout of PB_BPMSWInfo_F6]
BO_ 2650776566 PB_BPMSWInfo_F6: 8 NODE_F6
 SG_ SBMS_AppLyr_BldNr_FFA3F6 : 48|8@1+ (1,0) [0|255] ""  PCM
 SG_ SBMS_AppLyr_MinRel_FFA3F6 : 40|8@1+ (1,0) [0|255] ""  PCM
 SG_ SBMS_AppLyr_MajRel_FFA3F6 : 32|8@1+ (1,0) [0|255] ""  PCM
 SG_ SBMS_SftyLyr_BldNr_FFA3F6 : 24|8@1+ (1,0) [0|255] ""  PCM
 SG_ SBMS_SftyLyr_MinRel_FFA3F6 : 8|16@1+ (1,0) [0|65535] ""  PCM
 SG_ SBMS_SftyLyr_MajRel_FFA3F6 : 0|8@1+ (1,0) [0|255] ""  PCM

CM_ SG_ 2566845952 EngInMan1Prs "- SAE J1939/73 Freeze Frame parameter";
CM_ BO_ 2566901834 "- Cluster indications off if the message is not received for 3 cycle times";
CM_ SG_ 2566901834 BuzActvModeNew "- 11b should be better not used (00b to set off the information)";
CM_ SG_ 2566901834 InfoSev "- Previously called Warning Stop Lamp Activation";
CM_ SG_ 2566901834 InfoActvModeNew "- Init Raw Value = 0 to avoid inital message triggering
-  11b should be better not used (00b to set off the information)";
CM_ SG_ 2566769185 EngOpPriInterSpeedSel "- 0 Off/Mode 0, 1 Mode 1, 2 Mode 2, 3 Mode 3";
CM_ BO_ 2566786839 "- SAE Trans.Rate=OnRequest";
CM_ SG_ 2566786839 TempUnits "- Only assigned in ISO11783/7, not in SAEJ1939DA";
CM_ SG_ 2566786839 PrsUnits "- Only assigned in ISO11783/7, not in SAEJ1939DA
-  Proprietary value table: 00b bar, 01b psi, 10b kpascal, 11b No Action";
CM_ SG_ 2566786839 UnitsSys "- Only assigned in ISO11783/7, not in SAEJ1939DA";
CM_ BO_ 2566786881 "- SAE Trans.Rate=OnRequest";
CM_ SG_ 2566786881 TempUnits_FE0F41 "- Only assigned in ISO11783/7, not in SAEJ1939DA
-  Signal routed from LC_17";
CM_ SG_ 2566786881 DistUnitCmd_FE0F41 "- Signal routed from LC_17";
CM_ SG_ 2566786881 VolUnitCmd_FE0F41 "- Signal routed from LC_17";
CM_ SG_ 2566786881 MassUnitCmd_FE0F41 "- Signal routed from LC_17";
CM_ BO_ 2365473057 "- On Daily MY24 values are (00 De-Activate; 01 Activate; 10 Error & Deactivate; 11 Error and Activate)
-  SAEJ1939: Flashing is accomplished by sending the lighting message with the state alternately ON or OFF
-  To be sent also at Ignition Off in case of Hazard or Parkink lights activation";
CM_ SG_ 2365473057 TractRearHighMountWorkLightCmd "- On Daily MY24 values are (00 De-Activate; 01 Activate; 10 Error & Deactivate; 11 Error and Activate)
-  Working Lights/Spot Lights";
CM_ SG_ 2365473057 RearFogLightCmd "- On Daily MY24 values are (00 De-Activate; 01 Activate; 10 Error & Deactivate; 11 Error and Activate)";
CM_ SG_ 2365473057 TractMarkerLightCmd "- On Daily MY24 values are (00 De-Activate; 01 Activate; 10 Error & Deactivate; 11 Error and Activate)
-  Side Position Lights, License Plate Lights";
CM_ SG_ 2365473057 TractClearLightCmd "- On Daily MY24 values are (00 De-Activate; 01 Activate; 10 Error & Deactivate; 11 Error and Activate)
-  Position/Parking Lights";
CM_ SG_ 2365473057 LeftStopLightCmd "- On Daily MY24 values are (00 De-Activate; 01 Activate; 10 Error & Deactivate; 11 Error and Activate)";
CM_ SG_ 2365473057 RightStopLightCmd "- On Daily MY24 values are (00 De-Activate; 01 Activate; 10 Error & Deactivate; 11 Error and Activate)";
CM_ SG_ 2365473057 CentStopLightCmd "- On Daily MY24 values are (00 De-Activate; 01 Activate; 10 Error & Deactivate; 11 Error and Activate)";
CM_ SG_ 2365473057 BackUpLightAndAlarmHornCmd "- On Daily MY24 values are (00 De-Activate; 01 Activate; 10 Error & Deactivate; 11 Error and Activate)
-  Reverse Lights and buzzer";
CM_ SG_ 2365473057 LeftTurnSigLightCmd "- Modulated by blinking
-  On Daily MY24 values are (00 De-Activate; 01 Activate; 10 Error & Deactivate; 11 Error and Activate)";
CM_ SG_ 2365473057 RightTurnSigLightCmd "- Modulated by blinking
-  On Daily MY24 values are (00 De-Activate; 01 Activate; 10 Error & Deactivate; 11 Error and Activate)";
CM_ SG_ 2365473057 TractFrontFogLightCmd "- Front Fog Lights
-  On Daily MY24 values are (00 De-Activate; 01 Activate; 10 Error & Deactivate; 11 Error and Activate)";
CM_ SG_ 2365473057 HighBeamHeadLightCmd "- High Beam Lights
-  On Daily MY24 values are (00 De-Activate; 01 Activate; 10 Error & Deactivate; 11 Error and Activate)";
CM_ SG_ 2365473057 LowBeamHeadLightCmd "- Low Beam Lights
-  On Daily MY24 values are (00 De-Activate; 01 Activate; 10 Error & Deactivate; 11 Error and Activate)";
CM_ SG_ 2365473057 RunLightCmd "- DRL
-  On Daily MY24 values are (00 De-Activate; 01 Activate; 10 Error & Deactivate; 11 Error and Activate)";
CM_ SG_ 2365473066 HighBeamHeadLightCmd_E412A "- 00b to deactivate High Beam, 11b otherwise
-  10b is used to manage internal error state";
CM_ BO_ 2566842624 "-  2 Message Variant(s): Transm.Rates 1000, OnRequest
-  Cyclic Transmission Rate as result of PGN requests
-  SAE Trans.Rate=OnRequest";
CM_ BO_ 2566615335 "- Primary EPCU Motor Temperature";
CM_ BO_ 2566615591 "- Primary EPCU Inverter Temperature";
CM_ SG_ 2566802465 OpsBlackOutIntensSel "- 0% in Black Out mode, 100% not in Black Out mode";
CM_ BO_ 2566670131 "- Not implemented in TPMS Sensata Step1 Stralis MY2019";
CM_ SG_ 2566898977 SeatBeltRemindSts "- Only driver belt warning till 2018, all front seat belts from 2019";
CM_ SG_ 2566776106 MaxVsl3 "- i-ACC - used for ACC Speed limit proposal";
CM_ SG_ 2566776106 MaxVsl2 "- ISA Adjustable VSL";
CM_ SG_ 2499614241 DrivOccpClassSysSts "- Used values 000b (Empty), 011 (Adult), 111b (Not available";
CM_ SG_ 2499614291 OccpClassSys3Sts "- Used values 000b (Empty), 011 (Adult), 111b (Not available)";
CM_ SG_ 2499614291 PassOccpClassSysSts "- Used values 000b (Empty), 011 (Adult), 111b (Not available)";
CM_ SG_ 2499614291 DrivOccpClassSysSts_FD1653 "- Used values 000b (Empty), 011 (Adult), 111b (Not available)";
CM_ SG_ 2566769953 FrontOpWiperSw "- MY24 : Value 0111b (Panic Wiper)";
CM_ SG_ 2565865249 CtrlByte "- 00h (Engine)";
CM_ BO_ 2566895260 "- Faster transmission rate when active and once afterwards";
CM_ SG_ 2583654703 SamReq "- Future Development";
CM_ SG_ 2583639312 Crc8 "- CRC Only - No Data ID Applied";
BA_DEF_ BO_  "CI_MsgDefinition" STRING ;
BA_DEF_ BO_  "CI_MsgId" INT 0 2147483647;
BA_DEF_ BO_  "CI_MsgName" STRING ;
BA_DEF_ BO_  "GenMsgCycleTime" INT 0 3600000;
BA_DEF_ BO_  "GenMsgCycleTimeFast" INT 0 3600000;
BA_DEF_ BO_  "GenMsgDelayTime" INT 0 3600000;
BA_DEF_ BO_  "GenMsgILSupport" ENUM  "No","Yes";
BA_DEF_ BO_  "GenMsgNrOfRepetition" INT 0 1000000;
BA_DEF_ BO_  "GenMsgRequestable" INT 0 1;
BA_DEF_ BO_  "GenMsgSendType" ENUM  "cyclic","NotUsed","NotUsed","NotUsed","NotUsed","NotUsed","NotUsed","IfActive","noMsgSendType";
BA_DEF_ BO_  "GenMsgStartDelayTime" INT 0 100000;
BA_DEF_ BO_  "TpJ1939VarDlc" ENUM  "No","Yes";
BA_DEF_ BO_  "VFrameFormat" ENUM  "StandardCAN","ExtendedCAN","reserved","J1939PG";
BA_DEF_ SG_  "CI_ParId" STRING ;
BA_DEF_ SG_  "CI_SigId" INT 0 2147483647;
BA_DEF_ SG_  "CI_SigName" STRING ;
BA_DEF_ SG_  "GenSigEVName" STRING ;
BA_DEF_ SG_  "GenSigILSupport" ENUM  "No","Yes";
BA_DEF_ SG_  "GenSigInactiveValue" INT 0 2147483647;
BA_DEF_ SG_  "GenSigSendType" ENUM  "Cyclic","OnWrite","OnWriteWithRepetition","OnChange","OnChangeWithRepetition","IfActive","IfActiveWithRepetition","NoSigSendType";
BA_DEF_ SG_  "GenSigStartValue" INT 0 2147483647;
BA_DEF_ SG_  "GenSigTimeoutTime_PCM" INT 0 3600000;
BA_DEF_ SG_  "GenSigTimeoutTime_SGW" INT 0 3600000;
BA_DEF_ SG_  "SPN" INT 0 524287;
BA_DEF_ SG_  "SigType" ENUM  "Default","Range","RangeSigned","ASCII","Discrete","Control","ReferencePGN","DTC","StringDelimiter","StringLength","StringLengthControl";
BA_DEF_DEF_  "CI_MsgDefinition" "";
BA_DEF_DEF_  "CI_MsgId" 0;
BA_DEF_DEF_  "CI_MsgName" "";
BA_DEF_DEF_  "GenMsgCycleTime" 0;
BA_DEF_DEF_  "GenMsgCycleTimeFast" 0;
BA_DEF_DEF_  "GenMsgDelayTime" 1;
BA_DEF_DEF_  "GenMsgILSupport" "Yes";
BA_DEF_DEF_  "GenMsgNrOfRepetition" 0;
BA_DEF_DEF_  "GenMsgRequestable" 0;
BA_DEF_DEF_  "GenMsgSendType" "noMsgSendType";
BA_DEF_DEF_  "GenMsgStartDelayTime" 0;
BA_DEF_DEF_  "TpJ1939VarDlc" "No";
BA_DEF_DEF_  "VFrameFormat" "J1939PG";
BA_DEF_DEF_  "CI_ParId" "";
BA_DEF_DEF_  "CI_SigId" 0;
BA_DEF_DEF_  "CI_SigName" "";
BA_DEF_DEF_  "GenSigEVName" "Env@Nodename_@Signame";
BA_DEF_DEF_  "GenSigILSupport" "Yes";
BA_DEF_DEF_  "GenSigInactiveValue" 0;
BA_DEF_DEF_  "GenSigSendType" "NoSigSendType";
BA_DEF_DEF_  "GenSigStartValue" 0;
BA_DEF_DEF_  "GenSigTimeoutTime_PCM" 0;
BA_DEF_DEF_  "GenSigTimeoutTime_SGW" 0;
BA_DEF_DEF_  "SPN" 0;
BA_DEF_DEF_  "SigType" "Default";
BA_ "CI_MsgDefinition" BO_ 2350641959 "J1939DA";
BA_ "CI_MsgId" BO_ 2350641959 3712;
BA_ "CI_MsgName" BO_ 2350641959 "HVESSC1_27_F3 - High Voltage Energy Storage System Control 1";
BA_ "GenMsgCycleTime" BO_ 2350641959 20;
BA_ "GenMsgCycleTimeFast" BO_ 2350641959 20;
BA_ "GenMsgDelayTime" BO_ 2350641959 10;
BA_ "GenMsgSendType" BO_ 2350641959 0;
BA_ "GenMsgStartDelayTime" BO_ 2350641959 13;
BA_ "CI_MsgDefinition" BO_ 2350589939 "J1939DA";
BA_ "CI_MsgId" BO_ 2350589939 33122;
BA_ "CI_MsgName" BO_ 2350589939 "HVESSC1_F3_27 - High Voltage Energy Storage System Control 1";
BA_ "GenMsgCycleTime" BO_ 2350589939 250;
BA_ "GenMsgCycleTimeFast" BO_ 2350589939 250;
BA_ "GenMsgDelayTime" BO_ 2350589939 125;
BA_ "GenMsgSendType" BO_ 2350589939 0;
BA_ "GenMsgStartDelayTime" BO_ 2350589939 103;
BA_ "CI_MsgDefinition" BO_ 2364576039 "J1939DA";
BA_ "CI_MsgId" BO_ 2364576039 35779;
BA_ "CI_MsgName" BO_ 2364576039 "HVESSD2_27 - High Voltage Energy Storage System Data 2";
BA_ "GenMsgCycleTime" BO_ 2364576039 200;
BA_ "GenMsgCycleTimeFast" BO_ 2364576039 200;
BA_ "GenMsgDelayTime" BO_ 2364576039 100;
BA_ "GenMsgSendType" BO_ 2364576039 0;
BA_ "GenMsgStartDelayTime" BO_ 2364576039 98;
BA_ "CI_MsgDefinition" BO_ 2364576243 "J1939DA";
BA_ "CI_MsgId" BO_ 2364576243 3767;
BA_ "CI_MsgName" BO_ 2364576243 "HVESSD2_F3 - High Voltage Energy Storage System Data 2";
BA_ "GenMsgCycleTime" BO_ 2364576243 250;
BA_ "GenMsgCycleTimeFast" BO_ 2364576243 250;
BA_ "GenMsgDelayTime" BO_ 2364576243 125;
BA_ "GenMsgSendType" BO_ 2364576243 0;
BA_ "GenMsgStartDelayTime" BO_ 2364576243 104;
BA_ "CI_MsgDefinition" BO_ 2364576499 "J1939DA";
BA_ "CI_MsgId" BO_ 2364576499 3777;
BA_ "CI_MsgName" BO_ 2364576499 "HVESSD3_F3 - High Voltage Energy Storage System Data 3";
BA_ "GenMsgCycleTime" BO_ 2364576499 1000;
BA_ "GenMsgCycleTimeFast" BO_ 2364576499 1000;
BA_ "GenMsgDelayTime" BO_ 2364576499 500;
BA_ "GenMsgSendType" BO_ 2364576499 0;
BA_ "GenMsgStartDelayTime" BO_ 2364576499 134;
BA_ "CI_MsgDefinition" BO_ 2364577063 "J1939DA";
BA_ "CI_MsgId" BO_ 2364577063 41791;
BA_ "CI_MsgName" BO_ 2364577063 "HVESSD6_27 - High Voltage Energy Storage System Data 6";
BA_ "GenMsgCycleTime" BO_ 2364577063 1500;
BA_ "GenMsgCycleTimeFast" BO_ 2364577063 1500;
BA_ "GenMsgDelayTime" BO_ 2364577063 750;
BA_ "GenMsgSendType" BO_ 2364577063 0;
BA_ "GenMsgStartDelayTime" BO_ 2364577063 326;
BA_ "CI_MsgDefinition" BO_ 2364577523 "J1939DA";
BA_ "CI_MsgId" BO_ 2364577523 3872;
BA_ "CI_MsgName" BO_ 2364577523 "HVESSS1_F3 - High Voltage Energy Storage System Status 1";
BA_ "GenMsgCycleTime" BO_ 2364577523 100;
BA_ "GenMsgCycleTimeFast" BO_ 2364577523 100;
BA_ "GenMsgDelayTime" BO_ 2364577523 20;
BA_ "GenMsgSendType" BO_ 2364577523 0;
BA_ "GenMsgStartDelayTime" BO_ 2364577523 53;
BA_ "CI_MsgDefinition" BO_ 2364552947 "J1939DA";
BA_ "CI_MsgId" BO_ 2364552947 3999;
BA_ "CI_MsgName" BO_ 2364552947 "HVESSS2_F3 - High Voltage Energy Storage System Status 2";
BA_ "GenMsgCycleTime" BO_ 2364552947 1000;
BA_ "GenMsgCycleTimeFast" BO_ 2364552947 1000;
BA_ "GenMsgDelayTime" BO_ 2364552947 500;
BA_ "GenMsgSendType" BO_ 2364552947 0;
BA_ "GenMsgStartDelayTime" BO_ 2364552947 133;
BA_ "CI_MsgDefinition" BO_ 2566845952 "J1939DA";
BA_ "CI_MsgId" BO_ 2566845952 2077;
BA_ "CI_MsgName" BO_ 2566845952 "IC1 - Intake/Exhaust Conditions 1";
BA_ "GenMsgCycleTime" BO_ 2566845952 500;
BA_ "GenMsgCycleTimeFast" BO_ 2566845952 500;
BA_ "GenMsgDelayTime" BO_ 2566845952 250;
BA_ "GenMsgSendType" BO_ 2566845952 0;
BA_ "GenMsgStartDelayTime" BO_ 2566845952 129;
BA_ "CI_MsgDefinition" BO_ 2566901834 "Iveco SPR1 Proprietary";
BA_ "CI_MsgId" BO_ 2566901834 4798;
BA_ "CI_MsgName" BO_ 2566901834 "ICRW_4A - Instrument Cluster Remote Warning";
BA_ "GenMsgCycleTimeFast" BO_ 2566901834 100;
BA_ "GenMsgDelayTime" BO_ 2566901834 50;
BA_ "GenMsgNrOfRepetition" BO_ 2566901834 4;
BA_ "GenMsgStartDelayTime" BO_ 2566901834 6;
BA_ "CI_MsgDefinition" BO_ 2566769185 "J1939DA";
BA_ "CI_MsgId" BO_ 2566769185 3383;
BA_ "CI_MsgName" BO_ 2566769185 "ISC_21 - Intermediate Speed Control";
BA_ "GenMsgCycleTime" BO_ 2566769185 1000;
BA_ "GenMsgCycleTimeFast" BO_ 2566769185 1000;
BA_ "GenMsgDelayTime" BO_ 2566769185 100;
BA_ "GenMsgSendType" BO_ 2566769185 0;
BA_ "GenMsgStartDelayTime" BO_ 2566769185 172;
BA_ "CI_MsgDefinition" BO_ 2566786839 "ISO11783-7";
BA_ "CI_MsgId" BO_ 2566786839 4269;
BA_ "CI_MsgName" BO_ 2566786839 "LC_17 - Language Command";
BA_ "GenMsgCycleTime" BO_ 2566786839 1000;
BA_ "GenMsgCycleTimeFast" BO_ 2566786839 1000;
BA_ "GenMsgDelayTime" BO_ 2566786839 100;
BA_ "GenMsgSendType" BO_ 2566786839 0;
BA_ "GenMsgStartDelayTime" BO_ 2566786839 176;
BA_ "CI_MsgDefinition" BO_ 2566786881 "ISO11783-7";
BA_ "CI_MsgId" BO_ 2566786881 4282;
BA_ "CI_MsgName" BO_ 2566786881 "LC_41 - Language Command";
BA_ "GenMsgCycleTime" BO_ 2566786881 1000;
BA_ "GenMsgCycleTimeFast" BO_ 2566786881 1000;
BA_ "GenMsgDelayTime" BO_ 2566786881 100;
BA_ "GenMsgSendType" BO_ 2566786881 0;
BA_ "GenMsgStartDelayTime" BO_ 2566786881 177;
BA_ "CI_MsgDefinition" BO_ 2365473057 "J1939DA";
BA_ "CI_MsgId" BO_ 2365473057 4298;
BA_ "CI_MsgName" BO_ 2365473057 "LCMD_21 - Lighting Command";
BA_ "GenMsgCycleTime" BO_ 2365473057 1000;
BA_ "GenMsgCycleTimeFast" BO_ 2365473057 1000;
BA_ "GenMsgDelayTime" BO_ 2365473057 100;
BA_ "GenMsgSendType" BO_ 2365473057 0;
BA_ "GenMsgStartDelayTime" BO_ 2365473057 147;
BA_ "CI_MsgDefinition" BO_ 2365473066 "J1939DA";
BA_ "CI_MsgId" BO_ 2365473066 43071;
BA_ "CI_MsgName" BO_ 2365473066 "LCMD_2A - Lighting Command";
BA_ "GenMsgCycleTime" BO_ 2365473066 1000;
BA_ "GenMsgCycleTimeFast" BO_ 2365473066 1000;
BA_ "GenMsgDelayTime" BO_ 2365473066 50;
BA_ "GenMsgSendType" BO_ 2365473066 0;
BA_ "GenMsgStartDelayTime" BO_ 2365473066 148;
BA_ "CI_MsgDefinition" BO_ 2566842624 "J1939DA";
BA_ "CI_MsgId" BO_ 2566842624 2087;
BA_ "CI_MsgName" BO_ 2566842624 "LFC1 - Fuel Consumption (Liquid) 1";
BA_ "GenMsgCycleTime" BO_ 2566842624 1000;
BA_ "GenMsgCycleTimeFast" BO_ 2566842624 1000;
BA_ "GenMsgDelayTime" BO_ 2566842624 500;
BA_ "GenMsgSendType" BO_ 2566842624 0;
BA_ "GenMsgStartDelayTime" BO_ 2566842624 235;
BA_ "CI_MsgDefinition" BO_ 2566844928 "J1939DA";
BA_ "CI_MsgId" BO_ 2566844928 2098;
BA_ "CI_MsgName" BO_ 2566844928 "LFE1 - Fuel Economy (Liquid)";
BA_ "GenMsgCycleTime" BO_ 2566844928 100;
BA_ "GenMsgCycleTimeFast" BO_ 2566844928 100;
BA_ "GenMsgDelayTime" BO_ 2566844928 50;
BA_ "GenMsgSendType" BO_ 2566844928 0;
BA_ "GenMsgStartDelayTime" BO_ 2566844928 81;
BA_ "CI_MsgDefinition" BO_ 2566615335 "J1939DA";
BA_ "CI_MsgId" BO_ 2566615335 41787;
BA_ "CI_MsgName" BO_ 2566615335 "MG1IMT_27 - Motor/Generator 1 Inverter Motor Temperature";
BA_ "GenMsgCycleTime" BO_ 2566615335 1000;
BA_ "GenMsgCycleTimeFast" BO_ 2566615335 1000;
BA_ "GenMsgDelayTime" BO_ 2566615335 500;
BA_ "GenMsgSendType" BO_ 2566615335 0;
BA_ "GenMsgStartDelayTime" BO_ 2566615335 161;
BA_ "CI_MsgDefinition" BO_ 2365289967 "J1939DA";
BA_ "CI_MsgId" BO_ 2365289967 33352;
BA_ "CI_MsgName" BO_ 2365289967 "MG1IR1_EF - Motor/Generator 1 Inverter Reference 1";
BA_ "GenMsgCycleTime" BO_ 2365289967 1000;
BA_ "GenMsgCycleTimeFast" BO_ 2365289967 1000;
BA_ "GenMsgDelayTime" BO_ 2365289967 500;
BA_ "GenMsgSendType" BO_ 2365289967 0;
BA_ "GenMsgStartDelayTime" BO_ 2365289967 137;
BA_ "CI_MsgDefinition" BO_ 2365289970 "J1939DA";
BA_ "CI_MsgId" BO_ 2365289970 38714;
BA_ "CI_MsgName" BO_ 2365289970 "MG1IR1_F2 - Motor/Generator 1 Inverter Reference 1";
BA_ "GenMsgCycleTime" BO_ 2365289970 1000;
BA_ "GenMsgCycleTimeFast" BO_ 2365289970 1000;
BA_ "GenMsgDelayTime" BO_ 2365289970 500;
BA_ "GenMsgSendType" BO_ 2365289970 0;
BA_ "GenMsgStartDelayTime" BO_ 2365289970 138;
BA_ "CI_MsgDefinition" BO_ 2365289455 "J1939DA";
BA_ "CI_MsgId" BO_ 2365289455 33347;
BA_ "CI_MsgName" BO_ 2365289455 "MG1IR2_EF - Motor/Generator 1 Inverter Reference 2";
BA_ "GenMsgCycleTime" BO_ 2365289455 1000;
BA_ "GenMsgCycleTimeFast" BO_ 2365289455 1000;
BA_ "GenMsgDelayTime" BO_ 2365289455 500;
BA_ "GenMsgSendType" BO_ 2365289455 0;
BA_ "GenMsgStartDelayTime" BO_ 2365289455 135;
BA_ "CI_MsgDefinition" BO_ 2365289458 "J1939DA";
BA_ "CI_MsgId" BO_ 2365289458 38720;
BA_ "CI_MsgName" BO_ 2365289458 "MG1IR2_F2 - Motor/Generator 1 Inverter Reference 2";
BA_ "GenMsgCycleTime" BO_ 2365289458 1000;
BA_ "GenMsgCycleTimeFast" BO_ 2365289458 1000;
BA_ "GenMsgDelayTime" BO_ 2365289458 500;
BA_ "GenMsgSendType" BO_ 2365289458 0;
BA_ "GenMsgStartDelayTime" BO_ 2365289458 136;
BA_ "CI_MsgDefinition" BO_ 2365289711 "J1939DA";
BA_ "CI_MsgId" BO_ 2365289711 33358;
BA_ "CI_MsgName" BO_ 2365289711 "MG1IS1_EF - Motor/Generator 1 Inverter Status 1";
BA_ "GenMsgCycleTime" BO_ 2365289711 20;
BA_ "GenMsgCycleTimeFast" BO_ 2365289711 20;
BA_ "GenMsgDelayTime" BO_ 2365289711 10;
BA_ "GenMsgSendType" BO_ 2365289711 0;
BA_ "GenMsgStartDelayTime" BO_ 2365289711 15;
BA_ "CI_MsgDefinition" BO_ 2365289714 "J1939DA";
BA_ "CI_MsgId" BO_ 2365289714 38725;
BA_ "CI_MsgName" BO_ 2365289714 "MG1IS1_F2 - Motor/Generator 1 Inverter Status 1";
BA_ "GenMsgCycleTime" BO_ 2365289714 20;
BA_ "GenMsgCycleTimeFast" BO_ 2365289714 20;
BA_ "GenMsgDelayTime" BO_ 2365289714 10;
BA_ "GenMsgSendType" BO_ 2365289714 0;
BA_ "GenMsgStartDelayTime" BO_ 2365289714 16;
BA_ "CI_MsgDefinition" BO_ 2565966831 "J1939DA";
BA_ "CI_MsgId" BO_ 2565966831 33401;
BA_ "CI_MsgName" BO_ 2565966831 "MG1IS2_EF - Motor/Generator 1 Inverter Status 2";
BA_ "GenMsgCycleTime" BO_ 2565966831 100;
BA_ "GenMsgCycleTimeFast" BO_ 2565966831 100;
BA_ "GenMsgDelayTime" BO_ 2565966831 50;
BA_ "GenMsgSendType" BO_ 2565966831 0;
BA_ "GenMsgStartDelayTime" BO_ 2565966831 65;
BA_ "CI_MsgDefinition" BO_ 2565966834 "J1939DA";
BA_ "CI_MsgId" BO_ 2565966834 38732;
BA_ "CI_MsgName" BO_ 2565966834 "MG1IS2_F2 - Motor/Generator 1 Inverter Status 2";
BA_ "GenMsgCycleTime" BO_ 2565966834 100;
BA_ "GenMsgCycleTimeFast" BO_ 2565966834 100;
BA_ "GenMsgDelayTime" BO_ 2565966834 50;
BA_ "GenMsgSendType" BO_ 2565966834 0;
BA_ "GenMsgStartDelayTime" BO_ 2565966834 66;
BA_ "CI_MsgDefinition" BO_ 2566615591 "J1939DA";
BA_ "CI_MsgId" BO_ 2566615591 41789;
BA_ "CI_MsgName" BO_ 2566615591 "MG1IT_27 - Motor/Generator 1 Inverter Temperature";
BA_ "GenMsgCycleTime" BO_ 2566615591 1000;
BA_ "GenMsgCycleTimeFast" BO_ 2566615591 1000;
BA_ "GenMsgDelayTime" BO_ 2566615591 500;
BA_ "GenMsgSendType" BO_ 2566615591 0;
BA_ "GenMsgStartDelayTime" BO_ 2566615591 162;
BA_ "CI_MsgDefinition" BO_ 2566802465 "J1939DA";
BA_ "CI_MsgId" BO_ 2566802465 4247;
BA_ "CI_MsgName" BO_ 2566802465 "ML_21 - Military Lighting Command";
BA_ "GenMsgCycleTime" BO_ 2566802465 500;
BA_ "GenMsgCycleTimeFast" BO_ 2566802465 500;
BA_ "GenMsgDelayTime" BO_ 2566802465 100;
BA_ "GenMsgSendType" BO_ 2566802465 0;
BA_ "GenMsgStartDelayTime" BO_ 2566802465 126;
BA_ "CI_MsgDefinition" BO_ 2566670131 "J1939DA";
BA_ "CI_MsgId" BO_ 2566670131 6103;
BA_ "CI_MsgName" BO_ 2566670131 "MTI - Monitored Tire Information";
BA_ "CI_MsgDefinition" BO_ 2566898977 "Iveco Daily Proprietary";
BA_ "CI_MsgId" BO_ 2566898977 43067;
BA_ "CI_MsgName" BO_ 2566898977 "MuxInfo2 - Mux Info 2";
BA_ "GenMsgCycleTime" BO_ 2566898977 100;
BA_ "GenMsgCycleTimeFast" BO_ 2566898977 100;
BA_ "GenMsgDelayTime" BO_ 2566898977 20;
BA_ "GenMsgSendType" BO_ 2566898977 0;
BA_ "GenMsgStartDelayTime" BO_ 2566898977 87;
BA_ "CI_MsgDefinition" BO_ 2566776106 "J1939DA";
BA_ "CI_MsgId" BO_ 2566776106 42802;
BA_ "CI_MsgName" BO_ 2566776106 "MVS_2A - Maximum Vehicle Speed Limit Status";
BA_ "GenMsgCycleTime" BO_ 2566776106 1000;
BA_ "GenMsgCycleTimeFast" BO_ 2566776106 1000;
BA_ "GenMsgDelayTime" BO_ 2566776106 100;
BA_ "GenMsgSendType" BO_ 2566776106 0;
BA_ "GenMsgStartDelayTime" BO_ 2566776106 175;
BA_ "CI_MsgDefinition" BO_ 2499614241 "J1939DA";
BA_ "CI_MsgId" BO_ 2499614241 4431;
BA_ "CI_MsgName" BO_ 2499614241 "OCSI_21 - Occupant Classification System Information";
BA_ "GenMsgCycleTime" BO_ 2499614241 5000;
BA_ "GenMsgCycleTimeFast" BO_ 2499614241 5000;
BA_ "GenMsgDelayTime" BO_ 2499614241 250;
BA_ "GenMsgSendType" BO_ 2499614241 0;
BA_ "GenMsgStartDelayTime" BO_ 2499614241 332;
BA_ "CI_MsgDefinition" BO_ 2499614291 "J1939DA";
BA_ "CI_MsgId" BO_ 2499614291 44437;
BA_ "CI_MsgName" BO_ 2499614291 "OCSI_53 - Occupant Classification System Information";
BA_ "GenMsgCycleTime" BO_ 2499614291 5000;
BA_ "GenMsgCycleTimeFast" BO_ 2499614291 5000;
BA_ "GenMsgDelayTime" BO_ 2499614291 250;
BA_ "GenMsgSendType" BO_ 2499614291 0;
BA_ "GenMsgStartDelayTime" BO_ 2499614291 333;
BA_ "CI_MsgDefinition" BO_ 2365443105 "J1939DA";
BA_ "CI_MsgId" BO_ 2365443105 4214;
BA_ "CI_MsgName" BO_ 2365443105 "OEL_21 - Operators External Light Controls Message";
BA_ "GenMsgCycleTime" BO_ 2365443105 1000;
BA_ "GenMsgCycleTimeFast" BO_ 2365443105 1000;
BA_ "GenMsgDelayTime" BO_ 2365443105 100;
BA_ "GenMsgSendType" BO_ 2365443105 0;
BA_ "GenMsgStartDelayTime" BO_ 2365443105 146;
BA_ "CI_MsgDefinition" BO_ 2566769953 "J1939DA";
BA_ "CI_MsgId" BO_ 2566769953 4249;
BA_ "CI_MsgName" BO_ 2566769953 "OWW_21 - Operator Wiper and Washer Controls Message";
BA_ "GenMsgCycleTime" BO_ 2566769953 1000;
BA_ "GenMsgCycleTimeFast" BO_ 2566769953 1000;
BA_ "GenMsgDelayTime" BO_ 2566769953 100;
BA_ "GenMsgSendType" BO_ 2566769953 0;
BA_ "GenMsgStartDelayTime" BO_ 2566769953 173;
BA_ "CI_MsgDefinition" BO_ 2565865249 "Iveco NH Proprietary";
BA_ "CI_MsgId" BO_ 2565865249 11253;
BA_ "CI_MsgName" BO_ 2565865249 "PA_E_21 - Proprietary A - Iveco Engine";
BA_ "GenMsgCycleTime" BO_ 2565865249 1000;
BA_ "GenMsgCycleTimeFast" BO_ 2565865249 1000;
BA_ "GenMsgDelayTime" BO_ 2565865249 100;
BA_ "GenMsgSendType" BO_ 2565865249 0;
BA_ "GenMsgStartDelayTime" BO_ 2565865249 159;
BA_ "CI_MsgDefinition" BO_ 2566907681 "Iveco Daily Electric";
BA_ "CI_MsgId" BO_ 2566907681 8879;
BA_ "CI_MsgName" BO_ 2566907681 "PB_AC_Cmd_21 - Proprietary B - Automatic Climate Command";
BA_ "GenMsgCycleTime" BO_ 2566907681 1000;
BA_ "GenMsgCycleTimeFast" BO_ 2566907681 1000;
BA_ "GenMsgDelayTime" BO_ 2566907681 500;
BA_ "GenMsgSendType" BO_ 2566907681 0;
BA_ "GenMsgStartDelayTime" BO_ 2566907681 277;
BA_ "CI_MsgDefinition" BO_ 2566907943 "Iveco Daily Electric";
BA_ "CI_MsgId" BO_ 2566907943 8913;
BA_ "CI_MsgName" BO_ 2566907943 "PB_AC_Sts_27 - Proprietary B - Automatic Climate Status";
BA_ "GenMsgCycleTime" BO_ 2566907943 1000;
BA_ "GenMsgCycleTimeFast" BO_ 2566907943 1000;
BA_ "GenMsgDelayTime" BO_ 2566907943 500;
BA_ "GenMsgSendType" BO_ 2566907943 0;
BA_ "GenMsgStartDelayTime" BO_ 2566907943 278;
BA_ "CI_MsgDefinition" BO_ 2566895127 "Iveco Proprietary";
BA_ "CI_MsgId" BO_ 2566895127 42336;
BA_ "CI_MsgName" BO_ 2566895127 "PB_AIDDDOWILCA_17 - Proprietary B - Alcohol Interlock,  Driver Drawness,  Door Open Warning Information and Lane Change Assist";
BA_ "GenMsgCycleTime" BO_ 2566895127 1000;
BA_ "GenMsgCycleTimeFast" BO_ 2566895127 1000;
BA_ "GenMsgDelayTime" BO_ 2566895127 100;
BA_ "GenMsgSendType" BO_ 2566895127 0;
BA_ "GenMsgStartDelayTime" BO_ 2566895127 266;
BA_ "CI_MsgDefinition" BO_ 2566895137 "Iveco Proprietary";
BA_ "CI_MsgId" BO_ 2566895137 42340;
BA_ "CI_MsgName" BO_ 2566895137 "PB_AIDDDOWILCA_21 - Proprietary B - Alcohol Interlock,  Driver Drawness,  Door Open Warning Information and Lane Change Assist";
BA_ "GenMsgCycleTime" BO_ 2566895137 200;
BA_ "GenMsgCycleTimeFast" BO_ 2566895137 200;
BA_ "GenMsgDelayTime" BO_ 2566895137 100;
BA_ "GenMsgSendType" BO_ 2566895137 0;
BA_ "GenMsgStartDelayTime" BO_ 2566895137 99;
BA_ "CI_MsgDefinition" BO_ 2566895146 "Iveco Proprietary";
BA_ "CI_MsgId" BO_ 2566895146 42344;
BA_ "CI_MsgName" BO_ 2566895146 "PB_AIDDDOWILCA_2A - Proprietary B - Alcohol Interlock,  Driver Drawness,  Door Open Warning Information and Lane Change Assist";
BA_ "GenMsgCycleTime" BO_ 2566895146 200;
BA_ "GenMsgCycleTimeFast" BO_ 2566895146 200;
BA_ "GenMsgDelayTime" BO_ 2566895146 100;
BA_ "GenMsgSendType" BO_ 2566895146 0;
BA_ "GenMsgStartDelayTime" BO_ 2566895146 101;
BA_ "CI_MsgDefinition" BO_ 2566895178 "Iveco Proprietary";
BA_ "CI_MsgId" BO_ 2566895178 44486;
BA_ "CI_MsgName" BO_ 2566895178 "PB_AIDDDOWILCA_4A - Proprietary B - Alcohol Interlock,  Driver Drawness,  Door Open Warning Information and Lane Change Assist";
BA_ "CI_MsgDefinition" BO_ 2566895260 "Iveco Proprietary";
BA_ "CI_MsgId" BO_ 2566895260 42349;
BA_ "CI_MsgName" BO_ 2566895260 "PB_AIDDDOWILCA_9C - Proprietary B - Alcohol Interlock,  Driver Drawness,  Door Open Warning Information and Lane Change Assist";
BA_ "GenMsgCycleTime" BO_ 2566895260 200;
BA_ "GenMsgCycleTimeFast" BO_ 2566895260 20;
BA_ "GenMsgDelayTime" BO_ 2566895260 10;
BA_ "GenMsgSendType" BO_ 2566895260 0;
BA_ "GenMsgStartDelayTime" BO_ 2566895260 26;
BA_ "CI_MsgDefinition" BO_ 2583654703 "Iveco Daily";
BA_ "CI_MsgId" BO_ 2583654703 35139;
BA_ "CI_MsgName" BO_ 2583654703 "PB_ASMCmd_2F - Proprietary B - ASM Command";
BA_ "GenMsgCycleTime" BO_ 2583654703 10000;
BA_ "GenMsgCycleTimeFast" BO_ 2583654703 10000;
BA_ "GenMsgDelayTime" BO_ 2583654703 100;
BA_ "GenMsgSendType" BO_ 2583654703 0;
BA_ "GenMsgStartDelayTime" BO_ 2583654703 362;
BA_ "CI_MsgDefinition" BO_ 2566902551 "Iveco Proprietary";
BA_ "CI_MsgId" BO_ 2566902551 6270;
BA_ "CI_MsgName" BO_ 2566902551 "PB_B_17 - Proprietary B - Iveco Body";
BA_ "GenMsgCycleTime" BO_ 2566902551 1000;
BA_ "GenMsgCycleTimeFast" BO_ 2566902551 1000;
BA_ "GenMsgDelayTime" BO_ 2566902551 100;
BA_ "GenMsgSendType" BO_ 2566902551 0;
BA_ "GenMsgStartDelayTime" BO_ 2566902551 272;
BA_ "CI_MsgDefinition" BO_ 2566902602 "Iveco Proprietary";
BA_ "CI_MsgId" BO_ 2566902602 44493;
BA_ "CI_MsgName" BO_ 2566902602 "PB_B_4A - Proprietary B - Iveco Body";
BA_ "CI_MsgDefinition" BO_ 2583642355 "Iveco Daily Electric";
BA_ "CI_MsgId" BO_ 2583642355 39733;
BA_ "CI_MsgName" BO_ 2583642355 "PB_BATTPACKSTS1_F3 - Proprietary B - Battery Pack #1 Status";
BA_ "GenMsgCycleTime" BO_ 2583642355 1000;
BA_ "GenMsgCycleTimeFast" BO_ 2583642355 1000;
BA_ "GenMsgDelayTime" BO_ 2583642355 500;
BA_ "GenMsgSendType" BO_ 2583642355 0;
BA_ "GenMsgStartDelayTime" BO_ 2583642355 287;
BA_ "CI_MsgDefinition" BO_ 2583642611 "Iveco Daily Electric";
BA_ "CI_MsgId" BO_ 2583642611 39739;
BA_ "CI_MsgName" BO_ 2583642611 "PB_BATTPACKSTS2_F3 - Proprietary B - Battery Pack #2 Status";
BA_ "GenMsgCycleTime" BO_ 2583642611 1000;
BA_ "GenMsgCycleTimeFast" BO_ 2583642611 1000;
BA_ "GenMsgDelayTime" BO_ 2583642611 500;
BA_ "GenMsgSendType" BO_ 2583642611 0;
BA_ "GenMsgStartDelayTime" BO_ 2583642611 288;
BA_ "CI_MsgDefinition" BO_ 2583642867 "Iveco Daily Electric";
BA_ "CI_MsgId" BO_ 2583642867 39745;
BA_ "CI_MsgName" BO_ 2583642867 "PB_BATTPACKSTS3_F3 - Proprietary B - Battery Pack #3 Status";
BA_ "GenMsgCycleTime" BO_ 2583642867 1000;
BA_ "GenMsgCycleTimeFast" BO_ 2583642867 1000;
BA_ "GenMsgDelayTime" BO_ 2583642867 500;
BA_ "GenMsgSendType" BO_ 2583642867 0;
BA_ "GenMsgStartDelayTime" BO_ 2583642867 289;
BA_ "CI_MsgDefinition" BO_ 2583640051 "Iveco Daily Electric";
BA_ "CI_MsgId" BO_ 2583640051 40677;
BA_ "CI_MsgName" BO_ 2583640051 "PB_BATTPACKSTS4_F3 - Proprietary B - Battery Pack #4 Status";
BA_ "GenMsgCycleTime" BO_ 2583640051 1000;
BA_ "GenMsgCycleTimeFast" BO_ 2583640051 1000;
BA_ "GenMsgDelayTime" BO_ 2583640051 500;
BA_ "GenMsgSendType" BO_ 2583640051 0;
BA_ "GenMsgStartDelayTime" BO_ 2583640051 284;
BA_ "CI_MsgDefinition" BO_ 2583640307 "Iveco Daily Electric";
BA_ "CI_MsgId" BO_ 2583640307 40683;
BA_ "CI_MsgName" BO_ 2583640307 "PB_BATTPACKSTS5_F3 - Proprietary B - Battery Pack #5 Status";
BA_ "GenMsgCycleTime" BO_ 2583640307 1000;
BA_ "GenMsgCycleTimeFast" BO_ 2583640307 1000;
BA_ "GenMsgDelayTime" BO_ 2583640307 500;
BA_ "GenMsgSendType" BO_ 2583640307 0;
BA_ "GenMsgStartDelayTime" BO_ 2583640307 285;
BA_ "CI_MsgDefinition" BO_ 2583639312 "Iveco Daily Electric";
BA_ "CI_MsgId" BO_ 2583639312 41091;
BA_ "CI_MsgName" BO_ 2583639312 "PB_BBDEV - Proprietary B - BodyBuilder Device";
BA_ "GenMsgCycleTime" BO_ 2583639312 100;
BA_ "GenMsgCycleTimeFast" BO_ 2583639312 100;
BA_ "GenMsgDelayTime" BO_ 2583639312 50;
BA_ "GenMsgSendType" BO_ 2583639312 0;
BA_ "GenMsgStartDelayTime" BO_ 2583639312 89;
BA_ "CI_MsgDefinition" BO_ 2583639370 "Iveco Daily Electric";
BA_ "CI_MsgId" BO_ 2583639370 41106;
BA_ "CI_MsgName" BO_ 2583639370 "PB_BBDEV_4A - Proprietary B - BodyBuilder Device";
BA_ "GenMsgCycleTime" BO_ 2583639370 100;
BA_ "GenMsgCycleTimeFast" BO_ 2583639370 100;
BA_ "GenMsgDelayTime" BO_ 2583639370 50;
BA_ "GenMsgSendType" BO_ 2583639370 0;
BA_ "GenMsgStartDelayTime" BO_ 2583639370 8;
BA_ "CI_MsgDefinition" BO_ 2583636594 "Iveco Daily";
BA_ "CI_MsgId" BO_ 2583636594 44745;
BA_ "CI_MsgName" BO_ 2583636594 "PB_BBER_72 - Proprietary B - Body Builders External Request";
BA_ "GenMsgCycleTime" BO_ 2583636594 1000;
BA_ "GenMsgCycleTimeFast" BO_ 2583636594 1000;
BA_ "GenMsgDelayTime" BO_ 2583636594 500;
BA_ "GenMsgSendType" BO_ 2583636594 0;
BA_ "GenMsgStartDelayTime" BO_ 2583636594 282;
BA_ "CI_MsgDefinition" BO_ 2566894625 "Iveco Proprietary";
BA_ "CI_MsgId" BO_ 2566894625 42396;
BA_ "CI_MsgName" BO_ 2566894625 "PB_BCMData_21 - Proprietary B - Body Computer Module Data";
BA_ "GenMsgCycleTime" BO_ 2566894625 100;
BA_ "GenMsgCycleTimeFast" BO_ 2566894625 100;
BA_ "GenMsgDelayTime" BO_ 2566894625 50;
BA_ "GenMsgSendType" BO_ 2566894625 0;
BA_ "GenMsgStartDelayTime" BO_ 2566894625 85;
BA_ "CI_MsgDefinition" BO_ 2566888481 "Iveco Proprietary";
BA_ "CI_MsgId" BO_ 2566888481 44888;
BA_ "CI_MsgName" BO_ 2566888481 "PB_BcmData2_21 - Proprietary B - Body Computer Module Data 2";
BA_ "GenMsgCycleTime" BO_ 2566888481 1000;
BA_ "GenMsgCycleTimeFast" BO_ 2566888481 1000;
BA_ "GenMsgDelayTime" BO_ 2566888481 500;
BA_ "GenMsgSendType" BO_ 2566888481 0;
BA_ "GenMsgStartDelayTime" BO_ 2566888481 258;
BA_ "CI_MsgDefinition" BO_ 2583650855 "Iveco Daily Electric";
BA_ "CI_MsgId" BO_ 2583650855 39640;
BA_ "CI_MsgName" BO_ 2583650855 "PB_BMSDATA1_27 - PB_BMSDATA1";
BA_ "GenMsgCycleTime" BO_ 2583650855 100;
BA_ "GenMsgCycleTimeFast" BO_ 2583650855 100;
BA_ "GenMsgDelayTime" BO_ 2583650855 50;
BA_ "GenMsgSendType" BO_ 2583650855 0;
BA_ "GenMsgStartDelayTime" BO_ 2583650855 91;
BA_ "CI_MsgDefinition" BO_ 2583651111 "Iveco Daily Electric";
BA_ "CI_MsgId" BO_ 2583651111 39645;
BA_ "CI_MsgName" BO_ 2583651111 "PB_BMSDATA2_27 - PB_BMSDATA2";
BA_ "GenMsgCycleTime" BO_ 2583651111 100;
BA_ "GenMsgCycleTimeFast" BO_ 2583651111 100;
BA_ "GenMsgDelayTime" BO_ 2583651111 50;
BA_ "GenMsgSendType" BO_ 2583651111 0;
BA_ "GenMsgStartDelayTime" BO_ 2583651111 92;
BA_ "CI_MsgDefinition" BO_ 2583651367 "Iveco Daily Electric";
BA_ "CI_MsgId" BO_ 2583651367 39650;
BA_ "CI_MsgName" BO_ 2583651367 "PB_BMSDATA3_27 - PB_BMSDATA3";
BA_ "GenMsgCycleTime" BO_ 2583651367 100;
BA_ "GenMsgCycleTimeFast" BO_ 2583651367 100;
BA_ "GenMsgDelayTime" BO_ 2583651367 50;
BA_ "GenMsgSendType" BO_ 2583651367 0;
BA_ "GenMsgStartDelayTime" BO_ 2583651367 93;
BA_ "CI_MsgDefinition" BO_ 2583637747 "Iveco Daily Electric";
BA_ "CI_MsgId" BO_ 2583637747 43005;
BA_ "CI_MsgName" BO_ 2583637747 "PB_BPMInfo2_F3 - Proprietary B - Battery Pack Master Information 2";
BA_ "GenMsgCycleTime" BO_ 2583637747 1000;
BA_ "GenMsgCycleTimeFast" BO_ 2583637747 1000;
BA_ "GenMsgDelayTime" BO_ 2583637747 500;
BA_ "GenMsgSendType" BO_ 2583637747 0;
BA_ "GenMsgStartDelayTime" BO_ 2583637747 283;
BA_ "CI_MsgDefinition" BO_ 2650776454 "Iveco Daily Electric";
BA_ "CI_MsgId" BO_ 2650776454 43994;
BA_ "CI_MsgName" BO_ 2650776454 "PB_BPMSWInfo_86 - Proprietary B - Battery Pack Monitor SW Information";
BA_ "GenMsgCycleTime" BO_ 2650776454 600000;
BA_ "GenMsgCycleTimeFast" BO_ 2650776454 600000;
BA_ "GenMsgDelayTime" BO_ 2650776454 300000;
BA_ "GenMsgSendType" BO_ 2650776454 0;
BA_ "GenMsgStartDelayTime" BO_ 2650776454 369;
BA_ "CI_MsgDefinition" BO_ 2650776455 "Iveco Daily Electric";
BA_ "CI_MsgId" BO_ 2650776455 44001;
BA_ "CI_MsgName" BO_ 2650776455 "PB_BPMSWInfo_87 - Proprietary B - Battery Pack Monitor SW Information";
BA_ "GenMsgCycleTime" BO_ 2650776455 600000;
BA_ "GenMsgCycleTimeFast" BO_ 2650776455 600000;
BA_ "GenMsgDelayTime" BO_ 2650776455 300000;
BA_ "GenMsgSendType" BO_ 2650776455 0;
BA_ "GenMsgStartDelayTime" BO_ 2650776455 371;
BA_ "CI_MsgDefinition" BO_ 2650776564 "Iveco Daily Electric";
BA_ "CI_MsgId" BO_ 2650776564 43973;
BA_ "CI_MsgName" BO_ 2650776564 "PB_BPMSWInfo_F4 - Proprietary B - Battery Pack Monitor SW Information";
BA_ "GenMsgCycleTime" BO_ 2650776564 600000;
BA_ "GenMsgCycleTimeFast" BO_ 2650776564 600000;
BA_ "GenMsgDelayTime" BO_ 2650776564 300000;
BA_ "GenMsgSendType" BO_ 2650776564 0;
BA_ "GenMsgStartDelayTime" BO_ 2650776564 372;
BA_ "CI_MsgDefinition" BO_ 2650776565 "Iveco Daily Electric";
BA_ "CI_MsgId" BO_ 2650776565 43980;
BA_ "CI_MsgName" BO_ 2650776565 "PB_BPMSWInfo_F5 - Proprietary B - Battery Pack Monitor SW Information";
BA_ "GenMsgCycleTime" BO_ 2650776565 600000;
BA_ "GenMsgCycleTimeFast" BO_ 2650776565 600000;
BA_ "GenMsgDelayTime" BO_ 2650776565 300000;
BA_ "GenMsgSendType" BO_ 2650776565 0;
BA_ "GenMsgStartDelayTime" BO_ 2650776565 373;
BA_ "CI_MsgDefinition" BO_ 2650776566 "Iveco Daily Electric";
BA_ "CI_MsgId" BO_ 2650776566 43987;
BA_ "CI_MsgName" BO_ 2650776566 "PB_BPMSWInfo_F6 - Proprietary B - Battery Pack Monitor SW Information";
BA_ "GenMsgCycleTime" BO_ 2650776566 600000;
BA_ "GenMsgCycleTimeFast" BO_ 2650776566 600000;
BA_ "GenMsgDelayTime" BO_ 2650776566 300000;
BA_ "GenMsgSendType" BO_ 2650776566 0;
BA_ "GenMsgStartDelayTime" BO_ 2650776566 374;
BA_ "CI_ParId" SG_ 2350641959 HvessHighVBusPasIsolTestCmd "8126";
BA_ "CI_SigId" SG_ 2350641959 HvessHighVBusPasIsolTestCmd 3716;
BA_ "CI_SigName" SG_ 2350641959 HvessHighVBusPasIsolTestCmd "HVESS High-Voltage Bus Passive Isolation Test Command";
BA_ "GenSigTimeoutTime_PCM" SG_ 2350641959 HvessHighVBusPasIsolTestCmd 500;
BA_ "SPN" SG_ 2350641959 HvessHighVBusPasIsolTestCmd 8126;
BA_ "SigType" SG_ 2350641959 HvessHighVBusPasIsolTestCmd 4;
BA_ "CI_ParId" SG_ 2350641959 HvessPwrDwCmd "8124";
BA_ "CI_SigId" SG_ 2350641959 HvessPwrDwCmd 3714;
BA_ "CI_SigName" SG_ 2350641959 HvessPwrDwCmd "HVESS Power-Down Command";
BA_ "GenSigTimeoutTime_PCM" SG_ 2350641959 HvessPwrDwCmd 500;
BA_ "SPN" SG_ 2350641959 HvessPwrDwCmd 8124;
BA_ "SigType" SG_ 2350641959 HvessPwrDwCmd 4;
BA_ "CI_ParId" SG_ 2350641959 HvessHighVBusConnCmd "8123";
BA_ "CI_SigId" SG_ 2350641959 HvessHighVBusConnCmd 3713;
BA_ "CI_SigName" SG_ 2350641959 HvessHighVBusConnCmd "HVESS High-Voltage Bus Connect Command";
BA_ "GenSigTimeoutTime_PCM" SG_ 2350641959 HvessHighVBusConnCmd 500;
BA_ "SPN" SG_ 2350641959 HvessHighVBusConnCmd 8123;
BA_ "SigType" SG_ 2350641959 HvessHighVBusConnCmd 4;
BA_ "CI_ParId" SG_ 2350589939 HvessCellBalCmd "8127";
BA_ "CI_SigId" SG_ 2350589939 HvessCellBalCmd 33127;
BA_ "CI_SigName" SG_ 2350589939 HvessCellBalCmd "HVESS Cell Balancing Command";
BA_ "GenSigTimeoutTime_PCM" SG_ 2350589939 HvessCellBalCmd 1250;
BA_ "SPN" SG_ 2350589939 HvessCellBalCmd 8127;
BA_ "SigType" SG_ 2350589939 HvessCellBalCmd 4;
BA_ "CI_ParId" SG_ 2364576039 HvessFastUpdateSoc "5921";
BA_ "CI_SigId" SG_ 2364576039 HvessFastUpdateSoc 35780;
BA_ "CI_SigName" SG_ 2364576039 HvessFastUpdateSoc "HVESS Fast Update State of Charge";
BA_ "GenSigTimeoutTime_PCM" SG_ 2364576039 HvessFastUpdateSoc 1000;
BA_ "SPN" SG_ 2364576039 HvessFastUpdateSoc 5921;
BA_ "SigType" SG_ 2364576039 HvessFastUpdateSoc 1;
BA_ "CI_ParId" SG_ 2364576243 HvessCellVDiffSts "5924";
BA_ "CI_SigId" SG_ 2364576243 HvessCellVDiffSts 3771;
BA_ "CI_SigName" SG_ 2364576243 HvessCellVDiffSts "HVESS Cell Voltage Differential Status";
BA_ "GenSigTimeoutTime_PCM" SG_ 2364576243 HvessCellVDiffSts 1250;
BA_ "SPN" SG_ 2364576243 HvessCellVDiffSts 5924;
BA_ "CI_ParId" SG_ 2364576243 HvessLowCellV "5923";
BA_ "CI_SigId" SG_ 2364576243 HvessLowCellV 3770;
BA_ "CI_SigName" SG_ 2364576243 HvessLowCellV "HVESS Lowest Cell Voltage";
BA_ "GenSigTimeoutTime_PCM" SG_ 2364576243 HvessLowCellV 1250;
BA_ "SPN" SG_ 2364576243 HvessLowCellV 5923;
BA_ "SigType" SG_ 2364576243 HvessLowCellV 1;
BA_ "CI_ParId" SG_ 2364576243 HvessHighCellV "5922";
BA_ "CI_SigId" SG_ 2364576243 HvessHighCellV 3769;
BA_ "CI_SigName" SG_ 2364576243 HvessHighCellV "HVESS Highest Cell Voltage";
BA_ "GenSigTimeoutTime_PCM" SG_ 2364576243 HvessHighCellV 1250;
BA_ "SPN" SG_ 2364576243 HvessHighCellV 5922;
BA_ "SigType" SG_ 2364576243 HvessHighCellV 1;
BA_ "CI_ParId" SG_ 2364576243 HvessFastUpdateSoc_091F3 "5921";
BA_ "CI_SigId" SG_ 2364576243 HvessFastUpdateSoc_091F3 3768;
BA_ "CI_SigName" SG_ 2364576243 HvessFastUpdateSoc_091F3 "HVESS Fast Update State of Charge";
BA_ "GenSigTimeoutTime_PCM" SG_ 2364576243 HvessFastUpdateSoc_091F3 1250;
BA_ "SPN" SG_ 2364576243 HvessFastUpdateSoc_091F3 5921;
BA_ "SigType" SG_ 2364576243 HvessFastUpdateSoc_091F3 1;
BA_ "CI_ParId" SG_ 2364576499 HvessCellTempDiffSts "8078";
BA_ "CI_SigId" SG_ 2364576499 HvessCellTempDiffSts 3781;
BA_ "CI_SigName" SG_ 2364576499 HvessCellTempDiffSts "HVESS Cell Temperature Differential Status";
BA_ "GenSigTimeoutTime_PCM" SG_ 2364576499 HvessCellTempDiffSts 5000;
BA_ "SPN" SG_ 2364576499 HvessCellTempDiffSts 8078;
BA_ "SigType" SG_ 2364576499 HvessCellTempDiffSts 4;
BA_ "CI_ParId" SG_ 2364576499 HvessAvgCellTemp "8077";
BA_ "CI_SigId" SG_ 2364576499 HvessAvgCellTemp 3780;
BA_ "CI_SigName" SG_ 2364576499 HvessAvgCellTemp "HVESS Average Cell Temperature";
BA_ "GenSigTimeoutTime_PCM" SG_ 2364576499 HvessAvgCellTemp 5000;
BA_ "SPN" SG_ 2364576499 HvessAvgCellTemp 8077;
BA_ "SigType" SG_ 2364576499 HvessAvgCellTemp 1;
BA_ "CI_ParId" SG_ 2364576499 HvessLowCellTemp "8076";
BA_ "CI_SigId" SG_ 2364576499 HvessLowCellTemp 3779;
BA_ "CI_SigName" SG_ 2364576499 HvessLowCellTemp "HVESS Lowest Cell Temperature";
BA_ "GenSigTimeoutTime_PCM" SG_ 2364576499 HvessLowCellTemp 5000;
BA_ "SPN" SG_ 2364576499 HvessLowCellTemp 8076;
BA_ "SigType" SG_ 2364576499 HvessLowCellTemp 1;
BA_ "CI_ParId" SG_ 2364576499 HvessHighCellTemp "8075";
BA_ "CI_SigId" SG_ 2364576499 HvessHighCellTemp 3778;
BA_ "CI_SigName" SG_ 2364576499 HvessHighCellTemp "HVESS Highest Cell Temperature";
BA_ "GenSigTimeoutTime_PCM" SG_ 2364576499 HvessHighCellTemp 5000;
BA_ "SPN" SG_ 2364576499 HvessHighCellTemp 8075;
BA_ "SigType" SG_ 2364576499 HvessHighCellTemp 1;
BA_ "CI_ParId" SG_ 2364577063 HvessTemp "9119";
BA_ "CI_SigId" SG_ 2364577063 HvessTemp 41792;
BA_ "CI_SigName" SG_ 2364577063 HvessTemp "HVESS Temperature";
BA_ "GenSigTimeoutTime_PCM" SG_ 2364577063 HvessTemp 7500;
BA_ "SPN" SG_ 2364577063 HvessTemp 9119;
BA_ "SigType" SG_ 2364577063 HvessTemp 1;
BA_ "CI_ParId" SG_ 2364577523 HvessHighVBusConnSts "8413";
BA_ "CI_SigId" SG_ 2364577523 HvessHighVBusConnSts 3886;
BA_ "CI_SigName" SG_ 2364577523 HvessHighVBusConnSts "HVESS High-Voltage Bus Connection Status";
BA_ "GenSigSendType" SG_ 2364577523 HvessHighVBusConnSts 3;
BA_ "GenSigTimeoutTime_PCM" SG_ 2364577523 HvessHighVBusConnSts 500;
BA_ "SPN" SG_ 2364577523 HvessHighVBusConnSts 8413;
BA_ "CI_ParId" SG_ 2364577523 HvessSts1Cnt "13013";
BA_ "CI_SigId" SG_ 2364577523 HvessSts1Cnt 40246;
BA_ "CI_SigName" SG_ 2364577523 HvessSts1Cnt "HVESS Status 1 Counter";
BA_ "GenSigSendType" SG_ 2364577523 HvessSts1Cnt 3;
BA_ "SPN" SG_ 2364577523 HvessSts1Cnt 13013;
BA_ "CI_ParId" SG_ 2364577523 HvessInternChgSts "8207";
BA_ "CI_SigId" SG_ 2364577523 HvessInternChgSts 3885;
BA_ "CI_SigName" SG_ 2364577523 HvessInternChgSts "HVESS Internal Charger Status";
BA_ "GenSigSendType" SG_ 2364577523 HvessInternChgSts 3;
BA_ "GenSigTimeoutTime_PCM" SG_ 2364577523 HvessInternChgSts 500;
BA_ "SPN" SG_ 2364577523 HvessInternChgSts 8207;
BA_ "SigType" SG_ 2364577523 HvessInternChgSts 4;
BA_ "CI_ParId" SG_ 2364577523 HvessSocSts "8100";
BA_ "CI_SigId" SG_ 2364577523 HvessSocSts 3882;
BA_ "CI_SigName" SG_ 2364577523 HvessSocSts "HVESS State of Charge Status";
BA_ "GenSigSendType" SG_ 2364577523 HvessSocSts 3;
BA_ "GenSigTimeoutTime_PCM" SG_ 2364577523 HvessSocSts 500;
BA_ "SPN" SG_ 2364577523 HvessSocSts 8100;
BA_ "CI_ParId" SG_ 2364577523 HvessHvilSts "8098";
BA_ "CI_SigId" SG_ 2364577523 HvessHvilSts 3880;
BA_ "CI_SigName" SG_ 2364577523 HvessHvilSts "HVESS HVIL Status";
BA_ "GenSigSendType" SG_ 2364577523 HvessHvilSts 3;
BA_ "GenSigTimeoutTime_PCM" SG_ 2364577523 HvessHvilSts 500;
BA_ "SPN" SG_ 2364577523 HvessHvilSts 8098;
BA_ "SigType" SG_ 2364577523 HvessHvilSts 4;
BA_ "CI_ParId" SG_ 2364577523 HvessHighVBusPasIsolTestSts "8097";
BA_ "CI_SigId" SG_ 2364577523 HvessHighVBusPasIsolTestSts 3879;
BA_ "CI_SigName" SG_ 2364577523 HvessHighVBusPasIsolTestSts "HVESS High-Voltage Bus Passive Isolation Test Status";
BA_ "GenSigSendType" SG_ 2364577523 HvessHighVBusPasIsolTestSts 3;
BA_ "GenSigTimeoutTime_PCM" SG_ 2364577523 HvessHighVBusPasIsolTestSts 500;
BA_ "SPN" SG_ 2364577523 HvessHighVBusPasIsolTestSts 8097;
BA_ "CI_ParId" SG_ 2364552947 HvessChgPwrLimDueToAnUndefCause "8114";
BA_ "CI_SigId" SG_ 2364552947 HvessChgPwrLimDueToAnUndefCause 4011;
BA_ "CI_SigName" SG_ 2364552947 HvessChgPwrLimDueToAnUndefCause "HVESS Charge Power Limit Due to an Undefined Cause";
BA_ "GenSigTimeoutTime_PCM" SG_ 2364552947 HvessChgPwrLimDueToAnUndefCause 5000;
BA_ "SPN" SG_ 2364552947 HvessChgPwrLimDueToAnUndefCause 8114;
BA_ "SigType" SG_ 2364552947 HvessChgPwrLimDueToAnUndefCause 4;
BA_ "CI_ParId" SG_ 2364552947 HvessChgPwrLimDueToBatCur "8113";
BA_ "CI_SigId" SG_ 2364552947 HvessChgPwrLimDueToBatCur 4010;
BA_ "CI_SigName" SG_ 2364552947 HvessChgPwrLimDueToBatCur "HVESS Charge Power Limit Due to Battery Current";
BA_ "GenSigTimeoutTime_PCM" SG_ 2364552947 HvessChgPwrLimDueToBatCur 5000;
BA_ "SPN" SG_ 2364552947 HvessChgPwrLimDueToBatCur 8113;
BA_ "SigType" SG_ 2364552947 HvessChgPwrLimDueToBatCur 4;
BA_ "CI_ParId" SG_ 2364552947 HvessChgPwrLimDueToBatOrCellV "8112";
BA_ "CI_SigId" SG_ 2364552947 HvessChgPwrLimDueToBatOrCellV 4009;
BA_ "CI_SigName" SG_ 2364552947 HvessChgPwrLimDueToBatOrCellV "HVESS Charge Power Limit Due to Battery or Cell Voltage";
BA_ "GenSigTimeoutTime_PCM" SG_ 2364552947 HvessChgPwrLimDueToBatOrCellV 5000;
BA_ "SPN" SG_ 2364552947 HvessChgPwrLimDueToBatOrCellV 8112;
BA_ "SigType" SG_ 2364552947 HvessChgPwrLimDueToBatOrCellV 4;
BA_ "CI_ParId" SG_ 2364552947 HvessChgPwrLimDueToBatDiagCond "8111";
BA_ "CI_SigId" SG_ 2364552947 HvessChgPwrLimDueToBatDiagCond 4008;
BA_ "CI_SigName" SG_ 2364552947 HvessChgPwrLimDueToBatDiagCond "HVESS Charge Power Limit Due to Battery Diagnostic Condition";
BA_ "GenSigTimeoutTime_PCM" SG_ 2364552947 HvessChgPwrLimDueToBatDiagCond 5000;
BA_ "SPN" SG_ 2364552947 HvessChgPwrLimDueToBatDiagCond 8111;
BA_ "SigType" SG_ 2364552947 HvessChgPwrLimDueToBatDiagCond 4;
BA_ "CI_ParId" SG_ 2364552947 HvessChgPwrLimDueToBatTemp "8110";
BA_ "CI_SigId" SG_ 2364552947 HvessChgPwrLimDueToBatTemp 4007;
BA_ "CI_SigName" SG_ 2364552947 HvessChgPwrLimDueToBatTemp "HVESS Charge Power Limit Due to Battery Temperature";
BA_ "GenSigTimeoutTime_PCM" SG_ 2364552947 HvessChgPwrLimDueToBatTemp 5000;
BA_ "SPN" SG_ 2364552947 HvessChgPwrLimDueToBatTemp 8110;
BA_ "SigType" SG_ 2364552947 HvessChgPwrLimDueToBatTemp 4;
BA_ "CI_ParId" SG_ 2364552947 HvessChgPwrLimDueToSoc "8109";
BA_ "CI_SigId" SG_ 2364552947 HvessChgPwrLimDueToSoc 4006;
BA_ "CI_SigName" SG_ 2364552947 HvessChgPwrLimDueToSoc "HVESS Charge Power Limit Due to State of Charge";
BA_ "GenSigTimeoutTime_PCM" SG_ 2364552947 HvessChgPwrLimDueToSoc 5000;
BA_ "SPN" SG_ 2364552947 HvessChgPwrLimDueToSoc 8109;
BA_ "SigType" SG_ 2364552947 HvessChgPwrLimDueToSoc 4;
BA_ "CI_ParId" SG_ 2364552947 HvessDischPwrLimDueToAnUndefCaus "8108";
BA_ "CI_SigId" SG_ 2364552947 HvessDischPwrLimDueToAnUndefCaus 4005;
BA_ "CI_SigName" SG_ 2364552947 HvessDischPwrLimDueToAnUndefCaus "HVESS Discharge Power Limit Due to an Undefined Cause";
BA_ "GenSigTimeoutTime_PCM" SG_ 2364552947 HvessDischPwrLimDueToAnUndefCaus 5000;
BA_ "SPN" SG_ 2364552947 HvessDischPwrLimDueToAnUndefCaus 8108;
BA_ "SigType" SG_ 2364552947 HvessDischPwrLimDueToAnUndefCaus 4;
BA_ "CI_ParId" SG_ 2364552947 HvessDischPwrLimDueToBatCur "8107";
BA_ "CI_SigId" SG_ 2364552947 HvessDischPwrLimDueToBatCur 4004;
BA_ "CI_SigName" SG_ 2364552947 HvessDischPwrLimDueToBatCur "HVESS Discharge Power Limit Due to Battery Current";
BA_ "GenSigTimeoutTime_PCM" SG_ 2364552947 HvessDischPwrLimDueToBatCur 5000;
BA_ "SPN" SG_ 2364552947 HvessDischPwrLimDueToBatCur 8107;
BA_ "SigType" SG_ 2364552947 HvessDischPwrLimDueToBatCur 4;
BA_ "CI_ParId" SG_ 2364552947 HvessDischPwrLimDueToBatOrCellV "8106";
BA_ "CI_SigId" SG_ 2364552947 HvessDischPwrLimDueToBatOrCellV 4003;
BA_ "CI_SigName" SG_ 2364552947 HvessDischPwrLimDueToBatOrCellV "HVESS Discharge Power Limit Due to Battery or Cell Voltage";
BA_ "GenSigTimeoutTime_PCM" SG_ 2364552947 HvessDischPwrLimDueToBatOrCellV 5000;
BA_ "SPN" SG_ 2364552947 HvessDischPwrLimDueToBatOrCellV 8106;
BA_ "SigType" SG_ 2364552947 HvessDischPwrLimDueToBatOrCellV 4;
BA_ "CI_ParId" SG_ 2364552947 HvessDischPwrLimDueToBatDiagCond "8105";
BA_ "CI_SigId" SG_ 2364552947 HvessDischPwrLimDueToBatDiagCond 4002;
BA_ "CI_SigName" SG_ 2364552947 HvessDischPwrLimDueToBatDiagCond "HVESS Discharge Power Limit Due to Battery Diagnostic Condition";
BA_ "GenSigTimeoutTime_PCM" SG_ 2364552947 HvessDischPwrLimDueToBatDiagCond 5000;
BA_ "SPN" SG_ 2364552947 HvessDischPwrLimDueToBatDiagCond 8105;
BA_ "SigType" SG_ 2364552947 HvessDischPwrLimDueToBatDiagCond 4;
BA_ "CI_ParId" SG_ 2364552947 HvessDischPwrLimDueToBatTemp "8104";
BA_ "CI_SigId" SG_ 2364552947 HvessDischPwrLimDueToBatTemp 4001;
BA_ "CI_SigName" SG_ 2364552947 HvessDischPwrLimDueToBatTemp "HVESS Discharge Power Limit Due to Battery Temperature";
BA_ "GenSigTimeoutTime_PCM" SG_ 2364552947 HvessDischPwrLimDueToBatTemp 5000;
BA_ "SPN" SG_ 2364552947 HvessDischPwrLimDueToBatTemp 8104;
BA_ "SigType" SG_ 2364552947 HvessDischPwrLimDueToBatTemp 4;
BA_ "CI_ParId" SG_ 2364552947 HvessDischPwrLimDueToSoc "8103";
BA_ "CI_SigId" SG_ 2364552947 HvessDischPwrLimDueToSoc 4000;
BA_ "CI_SigName" SG_ 2364552947 HvessDischPwrLimDueToSoc "HVESS Discharge Power Limit Due to State of Charge";
BA_ "GenSigTimeoutTime_PCM" SG_ 2364552947 HvessDischPwrLimDueToSoc 5000;
BA_ "SPN" SG_ 2364552947 HvessDischPwrLimDueToSoc 8103;
BA_ "SigType" SG_ 2364552947 HvessDischPwrLimDueToSoc 4;
BA_ "CI_ParId" SG_ 2566845952 EngExhTemp "173";
BA_ "CI_SigId" SG_ 2566845952 EngExhTemp 2084;
BA_ "CI_SigName" SG_ 2566845952 EngExhTemp "Engine Exhaust Temperature";
BA_ "GenSigTimeoutTime_PCM" SG_ 2566845952 EngExhTemp 2500;
BA_ "SPN" SG_ 2566845952 EngExhTemp 173;
BA_ "SigType" SG_ 2566845952 EngExhTemp 1;
BA_ "CI_ParId" SG_ 2566845952 EngInAirPrs "106";
BA_ "CI_SigId" SG_ 2566845952 EngInAirPrs 2082;
BA_ "CI_SigName" SG_ 2566845952 EngInAirPrs "Engine Intake Air Pressure";
BA_ "GenSigTimeoutTime_PCM" SG_ 2566845952 EngInAirPrs 2500;
BA_ "SPN" SG_ 2566845952 EngInAirPrs 106;
BA_ "SigType" SG_ 2566845952 EngInAirPrs 1;
BA_ "CI_ParId" SG_ 2566845952 EngInMan1Temp "105";
BA_ "CI_SigId" SG_ 2566845952 EngInMan1Temp 2081;
BA_ "CI_SigName" SG_ 2566845952 EngInMan1Temp "Engine Intake Manifold 1 Temperature";
BA_ "GenSigTimeoutTime_PCM" SG_ 2566845952 EngInMan1Temp 2500;
BA_ "SPN" SG_ 2566845952 EngInMan1Temp 105;
BA_ "SigType" SG_ 2566845952 EngInMan1Temp 1;
BA_ "CI_ParId" SG_ 2566845952 EngInMan1Prs "102";
BA_ "CI_SigId" SG_ 2566845952 EngInMan1Prs 2080;
BA_ "CI_SigName" SG_ 2566845952 EngInMan1Prs "Engine Intake Manifold #1 Pressure";
BA_ "GenSigTimeoutTime_PCM" SG_ 2566845952 EngInMan1Prs 2500;
BA_ "SPN" SG_ 2566845952 EngInMan1Prs 102;
BA_ "SigType" SG_ 2566845952 EngInMan1Prs 1;
BA_ "CI_ParId" SG_ 2566845952 At1DpfInPrs "81";
BA_ "CI_SigId" SG_ 2566845952 At1DpfInPrs 2079;
BA_ "CI_SigName" SG_ 2566845952 At1DpfInPrs "Aftertreatment 1 Diesel Particulate Filter Intake Pressure (use SPN 3609)";
BA_ "GenSigTimeoutTime_PCM" SG_ 2566845952 At1DpfInPrs 2500;
BA_ "SPN" SG_ 2566845952 At1DpfInPrs 81;
BA_ "SigType" SG_ 2566845952 At1DpfInPrs 1;
BA_ "CI_ParId" SG_ 2566901834 PopupIx "I322";
BA_ "CI_SigId" SG_ 2566901834 PopupIx 4809;
BA_ "CI_SigName" SG_ 2566901834 PopupIx "Popup Index";
BA_ "CI_ParId" SG_ 2566901834 IndIx "I321";
BA_ "CI_SigId" SG_ 2566901834 IndIx 4808;
BA_ "CI_SigName" SG_ 2566901834 IndIx "Indicator Index";
BA_ "CI_ParId" SG_ 2566901834 BuzLevEx "I318";
BA_ "CI_SigId" SG_ 2566901834 BuzLevEx 4804;
BA_ "CI_SigName" SG_ 2566901834 BuzLevEx "Buzzer Level Extended";
BA_ "CI_ParId" SG_ 2566901834 BuzToneEx "I317";
BA_ "CI_SigId" SG_ 2566901834 BuzToneEx 4803;
BA_ "CI_SigName" SG_ 2566901834 BuzToneEx "Buzzer Tone Extended";
BA_ "CI_ParId" SG_ 2566901834 BuzActvModeNew "I315";
BA_ "CI_SigId" SG_ 2566901834 BuzActvModeNew 4801;
BA_ "CI_SigName" SG_ 2566901834 BuzActvModeNew "Buzzer Activation Mode New";
BA_ "SigType" SG_ 2566901834 BuzActvModeNew 4;
BA_ "CI_ParId" SG_ 2566901834 InfoSev "I314";
BA_ "CI_SigId" SG_ 2566901834 InfoSev 4800;
BA_ "CI_SigName" SG_ 2566901834 InfoSev "Info Severity";
BA_ "SigType" SG_ 2566901834 InfoSev 4;
BA_ "CI_ParId" SG_ 2566901834 InfoActvModeNew "I313";
BA_ "CI_SigId" SG_ 2566901834 InfoActvModeNew 4799;
BA_ "CI_SigName" SG_ 2566901834 InfoActvModeNew "Info Activation Mode New";
BA_ "GenSigSendType" SG_ 2566901834 InfoActvModeNew 6;
BA_ "SigType" SG_ 2566901834 InfoActvModeNew 4;
BA_ "CI_ParId" SG_ 2566769185 EngOpPriInterSpeedSel "2880";
BA_ "CI_SigId" SG_ 2566769185 EngOpPriInterSpeedSel 3384;
BA_ "CI_SigName" SG_ 2566769185 EngOpPriInterSpeedSel "Engine Operator Primary Intermediate Speed Select";
BA_ "GenSigSendType" SG_ 2566769185 EngOpPriInterSpeedSel 3;
BA_ "GenSigTimeoutTime_PCM" SG_ 2566769185 EngOpPriInterSpeedSel 5000;
BA_ "SPN" SG_ 2566769185 EngOpPriInterSpeedSel 2880;
BA_ "CI_ParId" SG_ 2566786839 TempUnits "5194";
BA_ "CI_SigId" SG_ 2566786839 TempUnits 4281;
BA_ "CI_SigName" SG_ 2566786839 TempUnits "Temperature units";
BA_ "GenSigSendType" SG_ 2566786839 TempUnits 3;
BA_ "GenSigTimeoutTime_PCM" SG_ 2566786839 TempUnits 5000;
BA_ "SPN" SG_ 2566786839 TempUnits 5194;
BA_ "SigType" SG_ 2566786839 TempUnits 4;
BA_ "CI_ParId" SG_ 2566786839 PrsUnits "5195";
BA_ "CI_SigId" SG_ 2566786839 PrsUnits 4280;
BA_ "CI_SigName" SG_ 2566786839 PrsUnits "Pressure units";
BA_ "GenSigSendType" SG_ 2566786839 PrsUnits 3;
BA_ "GenSigTimeoutTime_PCM" SG_ 2566786839 PrsUnits 5000;
BA_ "SPN" SG_ 2566786839 PrsUnits 5195;
BA_ "SigType" SG_ 2566786839 PrsUnits 4;
BA_ "CI_ParId" SG_ 2566786839 UnitsSys "5197";
BA_ "CI_SigId" SG_ 2566786839 UnitsSys 4278;
BA_ "CI_SigName" SG_ 2566786839 UnitsSys "Units system";
BA_ "GenSigSendType" SG_ 2566786839 UnitsSys 3;
BA_ "GenSigTimeoutTime_PCM" SG_ 2566786839 UnitsSys 5000;
BA_ "SPN" SG_ 2566786839 UnitsSys 5197;
BA_ "SigType" SG_ 2566786839 UnitsSys 4;
BA_ "CI_ParId" SG_ 2566786839 DistUnitCmd "2414";
BA_ "CI_SigId" SG_ 2566786839 DistUnitCmd 4277;
BA_ "CI_SigName" SG_ 2566786839 DistUnitCmd "Distance Unit Command";
BA_ "GenSigSendType" SG_ 2566786839 DistUnitCmd 3;
BA_ "GenSigTimeoutTime_PCM" SG_ 2566786839 DistUnitCmd 5000;
BA_ "SPN" SG_ 2566786839 DistUnitCmd 2414;
BA_ "SigType" SG_ 2566786839 DistUnitCmd 4;
BA_ "CI_ParId" SG_ 2566786839 VolUnitCmd "2416";
BA_ "CI_SigId" SG_ 2566786839 VolUnitCmd 4275;
BA_ "CI_SigName" SG_ 2566786839 VolUnitCmd "Volume Unit Command";
BA_ "GenSigSendType" SG_ 2566786839 VolUnitCmd 3;
BA_ "GenSigTimeoutTime_PCM" SG_ 2566786839 VolUnitCmd 5000;
BA_ "SPN" SG_ 2566786839 VolUnitCmd 2416;
BA_ "SigType" SG_ 2566786839 VolUnitCmd 4;
BA_ "CI_ParId" SG_ 2566786839 MassUnitCmd "2417";
BA_ "CI_SigId" SG_ 2566786839 MassUnitCmd 4274;
BA_ "CI_SigName" SG_ 2566786839 MassUnitCmd "Mass Unit Command";
BA_ "GenSigSendType" SG_ 2566786839 MassUnitCmd 3;
BA_ "GenSigTimeoutTime_PCM" SG_ 2566786839 MassUnitCmd 5000;
BA_ "SPN" SG_ 2566786839 MassUnitCmd 2417;
BA_ "SigType" SG_ 2566786839 MassUnitCmd 4;
BA_ "CI_ParId" SG_ 2566786839 DateCmd "2412";
BA_ "CI_SigId" SG_ 2566786839 DateCmd 4273;
BA_ "CI_SigName" SG_ 2566786839 DateCmd "Date Command";
BA_ "GenSigSendType" SG_ 2566786839 DateCmd 3;
BA_ "GenSigTimeoutTime_PCM" SG_ 2566786839 DateCmd 5000;
BA_ "SPN" SG_ 2566786839 DateCmd 2412;
BA_ "CI_ParId" SG_ 2566786839 DecSymCmd "2411";
BA_ "CI_SigId" SG_ 2566786839 DecSymCmd 4272;
BA_ "CI_SigName" SG_ 2566786839 DecSymCmd "Decimal Symbol Command";
BA_ "GenSigSendType" SG_ 2566786839 DecSymCmd 3;
BA_ "GenSigTimeoutTime_PCM" SG_ 2566786839 DecSymCmd 5000;
BA_ "SPN" SG_ 2566786839 DecSymCmd 2411;
BA_ "SigType" SG_ 2566786839 DecSymCmd 4;
BA_ "CI_ParId" SG_ 2566786839 TimeCmd "2413";
BA_ "CI_SigId" SG_ 2566786839 TimeCmd 4271;
BA_ "CI_SigName" SG_ 2566786839 TimeCmd "Time Command";
BA_ "GenSigSendType" SG_ 2566786839 TimeCmd 3;
BA_ "GenSigTimeoutTime_PCM" SG_ 2566786839 TimeCmd 5000;
BA_ "SPN" SG_ 2566786839 TimeCmd 2413;
BA_ "SigType" SG_ 2566786839 TimeCmd 4;
BA_ "CI_ParId" SG_ 2566786839 LangCodeCmd "2410";
BA_ "CI_SigId" SG_ 2566786839 LangCodeCmd 4270;
BA_ "CI_SigName" SG_ 2566786839 LangCodeCmd "Language Code Command";
BA_ "GenSigSendType" SG_ 2566786839 LangCodeCmd 3;
BA_ "GenSigTimeoutTime_PCM" SG_ 2566786839 LangCodeCmd 5000;
BA_ "SPN" SG_ 2566786839 LangCodeCmd 2410;
BA_ "SigType" SG_ 2566786839 LangCodeCmd 3;
BA_ "CI_ParId" SG_ 2566786881 TempUnits_FE0F41 "5194";
BA_ "CI_SigId" SG_ 2566786881 TempUnits_FE0F41 4291;
BA_ "CI_SigName" SG_ 2566786881 TempUnits_FE0F41 "Temperature units";
BA_ "GenSigSendType" SG_ 2566786881 TempUnits_FE0F41 3;
BA_ "GenSigTimeoutTime_PCM" SG_ 2566786881 TempUnits_FE0F41 5000;
BA_ "SPN" SG_ 2566786881 TempUnits_FE0F41 5194;
BA_ "SigType" SG_ 2566786881 TempUnits_FE0F41 4;
BA_ "CI_ParId" SG_ 2566786881 PrsUnits_FE0F41 "5195";
BA_ "CI_SigId" SG_ 2566786881 PrsUnits_FE0F41 44731;
BA_ "CI_SigName" SG_ 2566786881 PrsUnits_FE0F41 "Pressure units";
BA_ "GenSigSendType" SG_ 2566786881 PrsUnits_FE0F41 3;
BA_ "GenSigTimeoutTime_PCM" SG_ 2566786881 PrsUnits_FE0F41 5000;
BA_ "SPN" SG_ 2566786881 PrsUnits_FE0F41 5195;
BA_ "SigType" SG_ 2566786881 PrsUnits_FE0F41 4;
BA_ "CI_ParId" SG_ 2566786881 DistUnitCmd_FE0F41 "2414";
BA_ "CI_SigId" SG_ 2566786881 DistUnitCmd_FE0F41 4290;
BA_ "CI_SigName" SG_ 2566786881 DistUnitCmd_FE0F41 "Distance Unit Command";
BA_ "GenSigSendType" SG_ 2566786881 DistUnitCmd_FE0F41 3;
BA_ "GenSigTimeoutTime_PCM" SG_ 2566786881 DistUnitCmd_FE0F41 5000;
BA_ "SPN" SG_ 2566786881 DistUnitCmd_FE0F41 2414;
BA_ "SigType" SG_ 2566786881 DistUnitCmd_FE0F41 4;
BA_ "CI_ParId" SG_ 2566786881 VolUnitCmd_FE0F41 "2416";
BA_ "CI_SigId" SG_ 2566786881 VolUnitCmd_FE0F41 4288;
BA_ "CI_SigName" SG_ 2566786881 VolUnitCmd_FE0F41 "Volume Unit Command";
BA_ "GenSigSendType" SG_ 2566786881 VolUnitCmd_FE0F41 3;
BA_ "GenSigTimeoutTime_PCM" SG_ 2566786881 VolUnitCmd_FE0F41 5000;
BA_ "SPN" SG_ 2566786881 VolUnitCmd_FE0F41 2416;
BA_ "SigType" SG_ 2566786881 VolUnitCmd_FE0F41 4;
BA_ "CI_ParId" SG_ 2566786881 MassUnitCmd_FE0F41 "2417";
BA_ "CI_SigId" SG_ 2566786881 MassUnitCmd_FE0F41 4287;
BA_ "CI_SigName" SG_ 2566786881 MassUnitCmd_FE0F41 "Mass Unit Command";
BA_ "GenSigSendType" SG_ 2566786881 MassUnitCmd_FE0F41 3;
BA_ "GenSigTimeoutTime_PCM" SG_ 2566786881 MassUnitCmd_FE0F41 5000;
BA_ "SPN" SG_ 2566786881 MassUnitCmd_FE0F41 2417;
BA_ "SigType" SG_ 2566786881 MassUnitCmd_FE0F41 4;
BA_ "CI_ParId" SG_ 2566786881 DateCmd_FE0F41 "2412";
BA_ "CI_SigId" SG_ 2566786881 DateCmd_FE0F41 4286;
BA_ "CI_SigName" SG_ 2566786881 DateCmd_FE0F41 "Date Command";
BA_ "GenSigSendType" SG_ 2566786881 DateCmd_FE0F41 3;
BA_ "GenSigTimeoutTime_PCM" SG_ 2566786881 DateCmd_FE0F41 5000;
BA_ "SPN" SG_ 2566786881 DateCmd_FE0F41 2412;
BA_ "CI_ParId" SG_ 2566786881 TimeCmd_FE0F41 "2413";
BA_ "CI_SigId" SG_ 2566786881 TimeCmd_FE0F41 4284;
BA_ "CI_SigName" SG_ 2566786881 TimeCmd_FE0F41 "Time Command";
BA_ "GenSigSendType" SG_ 2566786881 TimeCmd_FE0F41 3;
BA_ "GenSigTimeoutTime_PCM" SG_ 2566786881 TimeCmd_FE0F41 5000;
BA_ "SPN" SG_ 2566786881 TimeCmd_FE0F41 2413;
BA_ "SigType" SG_ 2566786881 TimeCmd_FE0F41 4;
BA_ "CI_ParId" SG_ 2566786881 LangCodeCmd_FE0F41 "2410";
BA_ "CI_SigId" SG_ 2566786881 LangCodeCmd_FE0F41 4283;
BA_ "CI_SigName" SG_ 2566786881 LangCodeCmd_FE0F41 "Language Code Command";
BA_ "GenSigSendType" SG_ 2566786881 LangCodeCmd_FE0F41 3;
BA_ "GenSigTimeoutTime_PCM" SG_ 2566786881 LangCodeCmd_FE0F41 5000;
BA_ "SPN" SG_ 2566786881 LangCodeCmd_FE0F41 2410;
BA_ "SigType" SG_ 2566786881 LangCodeCmd_FE0F41 3;
BA_ "CI_ParId" SG_ 2365473057 TractRearHighMountWorkLightCmd "2361";
BA_ "CI_SigId" SG_ 2365473057 TractRearHighMountWorkLightCmd 4318;
BA_ "CI_SigName" SG_ 2365473057 TractRearHighMountWorkLightCmd "Tractor Rear High Mounted Work Lights Command";
BA_ "GenSigSendType" SG_ 2365473057 TractRearHighMountWorkLightCmd 3;
BA_ "GenSigTimeoutTime_PCM" SG_ 2365473057 TractRearHighMountWorkLightCmd 5000;
BA_ "SPN" SG_ 2365473057 TractRearHighMountWorkLightCmd 2361;
BA_ "SigType" SG_ 2365473057 TractRearHighMountWorkLightCmd 4;
BA_ "CI_ParId" SG_ 2365473057 RearFogLightCmd "2389";
BA_ "CI_SigId" SG_ 2365473057 RearFogLightCmd 4315;
BA_ "CI_SigName" SG_ 2365473057 RearFogLightCmd "Rear Fog Light Command";
BA_ "GenSigSendType" SG_ 2365473057 RearFogLightCmd 3;
BA_ "GenSigTimeoutTime_PCM" SG_ 2365473057 RearFogLightCmd 5000;
BA_ "SPN" SG_ 2365473057 RearFogLightCmd 2389;
BA_ "SigType" SG_ 2365473057 RearFogLightCmd 4;
BA_ "CI_ParId" SG_ 2365473057 TractMarkerLightCmd "2377";
BA_ "CI_SigId" SG_ 2365473057 TractMarkerLightCmd 4314;
BA_ "CI_SigName" SG_ 2365473057 TractMarkerLightCmd "Tractor Marker Light Command";
BA_ "GenSigSendType" SG_ 2365473057 TractMarkerLightCmd 3;
BA_ "GenSigTimeoutTime_PCM" SG_ 2365473057 TractMarkerLightCmd 5000;
BA_ "SPN" SG_ 2365473057 TractMarkerLightCmd 2377;
BA_ "SigType" SG_ 2365473057 TractMarkerLightCmd 4;
BA_ "CI_ParId" SG_ 2365473057 TractClearLightCmd "2381";
BA_ "CI_SigId" SG_ 2365473057 TractClearLightCmd 4312;
BA_ "CI_SigName" SG_ 2365473057 TractClearLightCmd "Tractor Clearance Light Command";
BA_ "GenSigSendType" SG_ 2365473057 TractClearLightCmd 3;
BA_ "GenSigTimeoutTime_PCM" SG_ 2365473057 TractClearLightCmd 5000;
BA_ "SPN" SG_ 2365473057 TractClearLightCmd 2381;
BA_ "SigType" SG_ 2365473057 TractClearLightCmd 4;
BA_ "CI_ParId" SG_ 2365473057 LeftStopLightCmd "2371";
BA_ "CI_SigId" SG_ 2365473057 LeftStopLightCmd 4310;
BA_ "CI_SigName" SG_ 2365473057 LeftStopLightCmd "Left Stop Light Command";
BA_ "GenSigSendType" SG_ 2365473057 LeftStopLightCmd 3;
BA_ "GenSigTimeoutTime_PCM" SG_ 2365473057 LeftStopLightCmd 5000;
BA_ "SPN" SG_ 2365473057 LeftStopLightCmd 2371;
BA_ "SigType" SG_ 2365473057 LeftStopLightCmd 4;
BA_ "CI_ParId" SG_ 2365473057 RightStopLightCmd "2373";
BA_ "CI_SigId" SG_ 2365473057 RightStopLightCmd 4309;
BA_ "CI_SigName" SG_ 2365473057 RightStopLightCmd "Right Stop Light Command";
BA_ "GenSigSendType" SG_ 2365473057 RightStopLightCmd 3;
BA_ "GenSigTimeoutTime_PCM" SG_ 2365473057 RightStopLightCmd 5000;
BA_ "SPN" SG_ 2365473057 RightStopLightCmd 2373;
BA_ "SigType" SG_ 2365473057 RightStopLightCmd 4;
BA_ "CI_ParId" SG_ 2365473057 CentStopLightCmd "2375";
BA_ "CI_SigId" SG_ 2365473057 CentStopLightCmd 4308;
BA_ "CI_SigName" SG_ 2365473057 CentStopLightCmd "Center Stop Light Command";
BA_ "GenSigSendType" SG_ 2365473057 CentStopLightCmd 3;
BA_ "GenSigTimeoutTime_PCM" SG_ 2365473057 CentStopLightCmd 5000;
BA_ "SPN" SG_ 2365473057 CentStopLightCmd 2375;
BA_ "SigType" SG_ 2365473057 CentStopLightCmd 4;
BA_ "CI_ParId" SG_ 2365473057 BackUpLightAndAlarmHornCmd "2391";
BA_ "CI_SigId" SG_ 2365473057 BackUpLightAndAlarmHornCmd 4307;
BA_ "CI_SigName" SG_ 2365473057 BackUpLightAndAlarmHornCmd "Back Up Light and Alarm Horn Command";
BA_ "GenSigSendType" SG_ 2365473057 BackUpLightAndAlarmHornCmd 3;
BA_ "GenSigTimeoutTime_PCM" SG_ 2365473057 BackUpLightAndAlarmHornCmd 5000;
BA_ "SPN" SG_ 2365473057 BackUpLightAndAlarmHornCmd 2391;
BA_ "SigType" SG_ 2365473057 BackUpLightAndAlarmHornCmd 4;
BA_ "CI_ParId" SG_ 2365473057 LeftTurnSigLightCmd "2367";
BA_ "CI_SigId" SG_ 2365473057 LeftTurnSigLightCmd 4306;
BA_ "CI_SigName" SG_ 2365473057 LeftTurnSigLightCmd "Left Turn Signal Lights Command";
BA_ "GenSigSendType" SG_ 2365473057 LeftTurnSigLightCmd 3;
BA_ "GenSigTimeoutTime_PCM" SG_ 2365473057 LeftTurnSigLightCmd 5000;
BA_ "SPN" SG_ 2365473057 LeftTurnSigLightCmd 2367;
BA_ "SigType" SG_ 2365473057 LeftTurnSigLightCmd 4;
BA_ "CI_ParId" SG_ 2365473057 RightTurnSigLightCmd "2369";
BA_ "CI_SigId" SG_ 2365473057 RightTurnSigLightCmd 4305;
BA_ "CI_SigName" SG_ 2365473057 RightTurnSigLightCmd "Right Turn Signal Lights Command";
BA_ "GenSigSendType" SG_ 2365473057 RightTurnSigLightCmd 3;
BA_ "GenSigTimeoutTime_PCM" SG_ 2365473057 RightTurnSigLightCmd 5000;
BA_ "SPN" SG_ 2365473057 RightTurnSigLightCmd 2369;
BA_ "SigType" SG_ 2365473057 RightTurnSigLightCmd 4;
BA_ "CI_ParId" SG_ 2365473057 TractFrontFogLightCmd "2387";
BA_ "CI_SigId" SG_ 2365473057 TractFrontFogLightCmd 4303;
BA_ "CI_SigName" SG_ 2365473057 TractFrontFogLightCmd "Tractor Front Fog Lights Command";
BA_ "GenSigSendType" SG_ 2365473057 TractFrontFogLightCmd 3;
BA_ "GenSigTimeoutTime_PCM" SG_ 2365473057 TractFrontFogLightCmd 5000;
BA_ "SPN" SG_ 2365473057 TractFrontFogLightCmd 2387;
BA_ "SigType" SG_ 2365473057 TractFrontFogLightCmd 4;
BA_ "CI_ParId" SG_ 2365473057 HighBeamHeadLightCmd "2347";
BA_ "CI_SigId" SG_ 2365473057 HighBeamHeadLightCmd 4302;
BA_ "CI_SigName" SG_ 2365473057 HighBeamHeadLightCmd "High Beam Head Light Command";
BA_ "GenSigSendType" SG_ 2365473057 HighBeamHeadLightCmd 3;
BA_ "GenSigTimeoutTime_PCM" SG_ 2365473057 HighBeamHeadLightCmd 5000;
BA_ "SPN" SG_ 2365473057 HighBeamHeadLightCmd 2347;
BA_ "SigType" SG_ 2365473057 HighBeamHeadLightCmd 4;
BA_ "CI_ParId" SG_ 2365473057 LowBeamHeadLightCmd "2349";
BA_ "CI_SigId" SG_ 2365473057 LowBeamHeadLightCmd 4301;
BA_ "CI_SigName" SG_ 2365473057 LowBeamHeadLightCmd "Low Beam Head Light Command";
BA_ "GenSigSendType" SG_ 2365473057 LowBeamHeadLightCmd 3;
BA_ "GenSigTimeoutTime_PCM" SG_ 2365473057 LowBeamHeadLightCmd 5000;
BA_ "SPN" SG_ 2365473057 LowBeamHeadLightCmd 2349;
BA_ "SigType" SG_ 2365473057 LowBeamHeadLightCmd 4;
BA_ "CI_ParId" SG_ 2365473057 RunLightCmd "2403";
BA_ "CI_SigId" SG_ 2365473057 RunLightCmd 4299;
BA_ "CI_SigName" SG_ 2365473057 RunLightCmd "Running Light Command";
BA_ "GenSigSendType" SG_ 2365473057 RunLightCmd 3;
BA_ "GenSigTimeoutTime_PCM" SG_ 2365473057 RunLightCmd 5000;
BA_ "SPN" SG_ 2365473057 RunLightCmd 2403;
BA_ "SigType" SG_ 2365473057 RunLightCmd 4;
BA_ "CI_ParId" SG_ 2365473066 HighBeamHeadLightCmd_E412A "2347";
BA_ "CI_SigId" SG_ 2365473066 HighBeamHeadLightCmd_E412A 4337;
BA_ "CI_SigName" SG_ 2365473066 HighBeamHeadLightCmd_E412A "High Beam Head Light Command";
BA_ "GenSigSendType" SG_ 2365473066 HighBeamHeadLightCmd_E412A 3;
BA_ "GenSigTimeoutTime_PCM" SG_ 2365473066 HighBeamHeadLightCmd_E412A 5000;
BA_ "SPN" SG_ 2365473066 HighBeamHeadLightCmd_E412A 2347;
BA_ "SigType" SG_ 2365473066 HighBeamHeadLightCmd_E412A 4;
BA_ "CI_ParId" SG_ 2566842624 EngTotFuelUsed "250";
BA_ "CI_SigId" SG_ 2566842624 EngTotFuelUsed 2090;
BA_ "CI_SigName" SG_ 2566842624 EngTotFuelUsed "Engine Total Fuel Used";
BA_ "GenSigTimeoutTime_PCM" SG_ 2566842624 EngTotFuelUsed 5000;
BA_ "SPN" SG_ 2566842624 EngTotFuelUsed 250;
BA_ "SigType" SG_ 2566842624 EngTotFuelUsed 1;
BA_ "CI_ParId" SG_ 2566844928 EngInstFuelEcon_FEF200 "184";
BA_ "CI_SigId" SG_ 2566844928 EngInstFuelEcon_FEF200 2100;
BA_ "CI_SigName" SG_ 2566844928 EngInstFuelEcon_FEF200 "Engine Instantaneous Fuel Economy";
BA_ "GenSigTimeoutTime_PCM" SG_ 2566844928 EngInstFuelEcon_FEF200 500;
BA_ "SPN" SG_ 2566844928 EngInstFuelEcon_FEF200 184;
BA_ "SigType" SG_ 2566844928 EngInstFuelEcon_FEF200 1;
BA_ "CI_ParId" SG_ 2566844928 EngFuelRate_FEF200 "183";
BA_ "CI_SigId" SG_ 2566844928 EngFuelRate_FEF200 2099;
BA_ "CI_SigName" SG_ 2566844928 EngFuelRate_FEF200 "Engine Fuel Rate";
BA_ "GenSigTimeoutTime_PCM" SG_ 2566844928 EngFuelRate_FEF200 500;
BA_ "SPN" SG_ 2566844928 EngFuelRate_FEF200 183;
BA_ "SigType" SG_ 2566844928 EngFuelRate_FEF200 1;
BA_ "CI_ParId" SG_ 2566615335 Mot_Gen1Temp1 "9059";
BA_ "CI_SigId" SG_ 2566615335 Mot_Gen1Temp1 41788;
BA_ "CI_SigName" SG_ 2566615335 Mot_Gen1Temp1 "Motor/Generator 1 Temperature 1";
BA_ "GenSigTimeoutTime_PCM" SG_ 2566615335 Mot_Gen1Temp1 5000;
BA_ "SPN" SG_ 2566615335 Mot_Gen1Temp1 9059;
BA_ "SigType" SG_ 2566615335 Mot_Gen1Temp1 1;
BA_ "CI_ParId" SG_ 2365289967 Mot_Gen1InvRefSpeed "10171";
BA_ "CI_SigId" SG_ 2365289967 Mot_Gen1InvRefSpeed 33356;
BA_ "CI_SigName" SG_ 2365289967 Mot_Gen1InvRefSpeed "Motor/Generator 1 Inverter Reference Speed";
BA_ "GenSigTimeoutTime_PCM" SG_ 2365289967 Mot_Gen1InvRefSpeed 5000;
BA_ "SPN" SG_ 2365289967 Mot_Gen1InvRefSpeed 10171;
BA_ "SigType" SG_ 2365289967 Mot_Gen1InvRefSpeed 1;
BA_ "CI_ParId" SG_ 2365289967 Mot_Gen1InvRefTrq "10170";
BA_ "CI_SigId" SG_ 2365289967 Mot_Gen1InvRefTrq 33355;
BA_ "CI_SigName" SG_ 2365289967 Mot_Gen1InvRefTrq "Motor/Generator 1 Inverter Reference Torque";
BA_ "GenSigTimeoutTime_PCM" SG_ 2365289967 Mot_Gen1InvRefTrq 5000;
BA_ "SPN" SG_ 2365289967 Mot_Gen1InvRefTrq 10170;
BA_ "SigType" SG_ 2365289967 Mot_Gen1InvRefTrq 1;
BA_ "CI_ParId" SG_ 2365289970 Mot_Gen1InvRefSpeed_B75F2 "10171";
BA_ "CI_SigId" SG_ 2365289970 Mot_Gen1InvRefSpeed_B75F2 38718;
BA_ "CI_SigName" SG_ 2365289970 Mot_Gen1InvRefSpeed_B75F2 "Motor/Generator 1 Inverter Reference Speed";
BA_ "GenSigTimeoutTime_PCM" SG_ 2365289970 Mot_Gen1InvRefSpeed_B75F2 5000;
BA_ "SPN" SG_ 2365289970 Mot_Gen1InvRefSpeed_B75F2 10171;
BA_ "SigType" SG_ 2365289970 Mot_Gen1InvRefSpeed_B75F2 1;
BA_ "CI_ParId" SG_ 2365289970 Mot_Gen1InvRefTrq_B75F2 "10170";
BA_ "CI_SigId" SG_ 2365289970 Mot_Gen1InvRefTrq_B75F2 38717;
BA_ "CI_SigName" SG_ 2365289970 Mot_Gen1InvRefTrq_B75F2 "Motor/Generator 1 Inverter Reference Torque";
BA_ "GenSigTimeoutTime_PCM" SG_ 2365289970 Mot_Gen1InvRefTrq_B75F2 5000;
BA_ "SPN" SG_ 2365289970 Mot_Gen1InvRefTrq_B75F2 10170;
BA_ "SigType" SG_ 2365289970 Mot_Gen1InvRefTrq_B75F2 1;
BA_ "CI_ParId" SG_ 2365289455 Mot_Gen1InvRefV "10203";
BA_ "CI_SigId" SG_ 2365289455 Mot_Gen1InvRefV 33351;
BA_ "CI_SigName" SG_ 2365289455 Mot_Gen1InvRefV "Motor/Generator 1 Inverter Reference Voltage";
BA_ "GenSigTimeoutTime_PCM" SG_ 2365289455 Mot_Gen1InvRefV 5000;
BA_ "SPN" SG_ 2365289455 Mot_Gen1InvRefV 10203;
BA_ "SigType" SG_ 2365289455 Mot_Gen1InvRefV 1;
BA_ "CI_ParId" SG_ 2365289455 Mot_Gen1InvRefCur "10202";
BA_ "CI_SigId" SG_ 2365289455 Mot_Gen1InvRefCur 33350;
BA_ "CI_SigName" SG_ 2365289455 Mot_Gen1InvRefCur "Motor/Generator 1 Inverter Reference Current";
BA_ "GenSigTimeoutTime_PCM" SG_ 2365289455 Mot_Gen1InvRefCur 5000;
BA_ "SPN" SG_ 2365289455 Mot_Gen1InvRefCur 10202;
BA_ "SigType" SG_ 2365289455 Mot_Gen1InvRefCur 1;
BA_ "CI_ParId" SG_ 2365289458 Mot_Gen1InvRefV_B73F2 "10203";
BA_ "CI_SigId" SG_ 2365289458 Mot_Gen1InvRefV_B73F2 38724;
BA_ "CI_SigName" SG_ 2365289458 Mot_Gen1InvRefV_B73F2 "Motor/Generator 1 Inverter Reference Voltage";
BA_ "GenSigTimeoutTime_PCM" SG_ 2365289458 Mot_Gen1InvRefV_B73F2 5000;
BA_ "SPN" SG_ 2365289458 Mot_Gen1InvRefV_B73F2 10203;
BA_ "SigType" SG_ 2365289458 Mot_Gen1InvRefV_B73F2 1;
BA_ "CI_ParId" SG_ 2365289458 Mot_Gen1InvRefCur_B73F2 "10202";
BA_ "CI_SigId" SG_ 2365289458 Mot_Gen1InvRefCur_B73F2 38723;
BA_ "CI_SigName" SG_ 2365289458 Mot_Gen1InvRefCur_B73F2 "Motor/Generator 1 Inverter Reference Current";
BA_ "GenSigTimeoutTime_PCM" SG_ 2365289458 Mot_Gen1InvRefCur_B73F2 5000;
BA_ "SPN" SG_ 2365289458 Mot_Gen1InvRefCur_B73F2 10202;
BA_ "SigType" SG_ 2365289458 Mot_Gen1InvRefCur_B73F2 1;
BA_ "CI_ParId" SG_ 2365289711 Mot_Gen1InvDcSideV "9101";
BA_ "CI_SigId" SG_ 2365289711 Mot_Gen1InvDcSideV 33364;
BA_ "CI_SigName" SG_ 2365289711 Mot_Gen1InvDcSideV "Motor/Generator 1 Inverter DC Side Voltage";
BA_ "GenSigTimeoutTime_PCM" SG_ 2365289711 Mot_Gen1InvDcSideV 500;
BA_ "SPN" SG_ 2365289711 Mot_Gen1InvDcSideV 9101;
BA_ "CI_ParId" SG_ 2365289711 Mot_Gen1InvDcSideCur "10175";
BA_ "CI_SigId" SG_ 2365289711 Mot_Gen1InvDcSideCur 33363;
BA_ "CI_SigName" SG_ 2365289711 Mot_Gen1InvDcSideCur "Motor/Generator 1 Inverter DC Side Current";
BA_ "GenSigTimeoutTime_PCM" SG_ 2365289711 Mot_Gen1InvDcSideCur 500;
BA_ "SPN" SG_ 2365289711 Mot_Gen1InvDcSideCur 10175;
BA_ "CI_ParId" SG_ 2365289711 Mot_Gen1Speed "9057";
BA_ "CI_SigId" SG_ 2365289711 Mot_Gen1Speed 33362;
BA_ "CI_SigName" SG_ 2365289711 Mot_Gen1Speed "Motor/Generator 1 Speed";
BA_ "GenSigTimeoutTime_PCM" SG_ 2365289711 Mot_Gen1Speed 500;
BA_ "SPN" SG_ 2365289711 Mot_Gen1Speed 9057;
BA_ "SigType" SG_ 2365289711 Mot_Gen1Speed 1;
BA_ "CI_ParId" SG_ 2365289711 Mot_Gen1Trq "9061";
BA_ "CI_SigId" SG_ 2365289711 Mot_Gen1Trq 33361;
BA_ "CI_SigName" SG_ 2365289711 Mot_Gen1Trq "Motor/Generator 1 Torque";
BA_ "GenSigTimeoutTime_PCM" SG_ 2365289711 Mot_Gen1Trq 500;
BA_ "SPN" SG_ 2365289711 Mot_Gen1Trq 9061;
BA_ "CI_ParId" SG_ 2365289714 Mot_Gen1InvDcSideV_B74F2 "9101";
BA_ "CI_SigId" SG_ 2365289714 Mot_Gen1InvDcSideV_B74F2 38731;
BA_ "CI_SigName" SG_ 2365289714 Mot_Gen1InvDcSideV_B74F2 "Motor/Generator 1 Inverter DC Side Voltage";
BA_ "GenSigTimeoutTime_PCM" SG_ 2365289714 Mot_Gen1InvDcSideV_B74F2 500;
BA_ "SPN" SG_ 2365289714 Mot_Gen1InvDcSideV_B74F2 9101;
BA_ "CI_ParId" SG_ 2365289714 Mot_Gen1InvDcSideCur_B74F2 "10175";
BA_ "CI_SigId" SG_ 2365289714 Mot_Gen1InvDcSideCur_B74F2 38730;
BA_ "CI_SigName" SG_ 2365289714 Mot_Gen1InvDcSideCur_B74F2 "Motor/Generator 1 Inverter DC Side Current";
BA_ "GenSigTimeoutTime_PCM" SG_ 2365289714 Mot_Gen1InvDcSideCur_B74F2 500;
BA_ "SPN" SG_ 2365289714 Mot_Gen1InvDcSideCur_B74F2 10175;
BA_ "CI_ParId" SG_ 2365289714 Mot_Gen1Speed_B74F2 "9057";
BA_ "CI_SigId" SG_ 2365289714 Mot_Gen1Speed_B74F2 38729;
BA_ "CI_SigName" SG_ 2365289714 Mot_Gen1Speed_B74F2 "Motor/Generator 1 Speed";
BA_ "GenSigTimeoutTime_PCM" SG_ 2365289714 Mot_Gen1Speed_B74F2 500;
BA_ "SPN" SG_ 2365289714 Mot_Gen1Speed_B74F2 9057;
BA_ "SigType" SG_ 2365289714 Mot_Gen1Speed_B74F2 1;
BA_ "CI_ParId" SG_ 2365289714 Mot_Gen1Trq_B74F2 "9061";
BA_ "CI_SigId" SG_ 2365289714 Mot_Gen1Trq_B74F2 38728;
BA_ "CI_SigName" SG_ 2365289714 Mot_Gen1Trq_B74F2 "Motor/Generator 1 Torque";
BA_ "GenSigTimeoutTime_PCM" SG_ 2365289714 Mot_Gen1Trq_B74F2 500;
BA_ "SPN" SG_ 2365289714 Mot_Gen1Trq_B74F2 9061;
BA_ "CI_ParId" SG_ 2565966831 Mot_Gen1AvMinTrq "10767";
BA_ "CI_SigId" SG_ 2565966831 Mot_Gen1AvMinTrq 33405;
BA_ "CI_SigName" SG_ 2565966831 Mot_Gen1AvMinTrq "Motor/Generator 1 Available Minimum Torque";
BA_ "GenSigTimeoutTime_PCM" SG_ 2565966831 Mot_Gen1AvMinTrq 500;
BA_ "SPN" SG_ 2565966831 Mot_Gen1AvMinTrq 10767;
BA_ "CI_ParId" SG_ 2565966831 Mot_Gen1AvMaxTrq "10766";
BA_ "CI_SigId" SG_ 2565966831 Mot_Gen1AvMaxTrq 33404;
BA_ "CI_SigName" SG_ 2565966831 Mot_Gen1AvMaxTrq "Motor/Generator 1 Available Maximum Torque";
BA_ "GenSigTimeoutTime_PCM" SG_ 2565966831 Mot_Gen1AvMaxTrq 500;
BA_ "SPN" SG_ 2565966831 Mot_Gen1AvMaxTrq 10766;
BA_ "CI_ParId" SG_ 2565966834 Mot_Gen1AvMinTrq_F18BF2 "10767";
BA_ "CI_SigId" SG_ 2565966834 Mot_Gen1AvMinTrq_F18BF2 38736;
BA_ "CI_SigName" SG_ 2565966834 Mot_Gen1AvMinTrq_F18BF2 "Motor/Generator 1 Available Minimum Torque";
BA_ "GenSigTimeoutTime_PCM" SG_ 2565966834 Mot_Gen1AvMinTrq_F18BF2 500;
BA_ "SPN" SG_ 2565966834 Mot_Gen1AvMinTrq_F18BF2 10767;
BA_ "CI_ParId" SG_ 2565966834 Mot_Gen1AvMaxTrq_F18BF2 "10766";
BA_ "CI_SigId" SG_ 2565966834 Mot_Gen1AvMaxTrq_F18BF2 38735;
BA_ "CI_SigName" SG_ 2565966834 Mot_Gen1AvMaxTrq_F18BF2 "Motor/Generator 1 Available Maximum Torque";
BA_ "GenSigTimeoutTime_PCM" SG_ 2565966834 Mot_Gen1AvMaxTrq_F18BF2 500;
BA_ "SPN" SG_ 2565966834 Mot_Gen1AvMaxTrq_F18BF2 10766;
BA_ "CI_ParId" SG_ 2566615591 Mot_Gen1InvTemp1 "10216";
BA_ "CI_SigId" SG_ 2566615591 Mot_Gen1InvTemp1 41790;
BA_ "CI_SigName" SG_ 2566615591 Mot_Gen1InvTemp1 "Motor/Generator 1 Inverter Temperature 1";
BA_ "GenSigTimeoutTime_PCM" SG_ 2566615591 Mot_Gen1InvTemp1 5000;
BA_ "SPN" SG_ 2566615591 Mot_Gen1InvTemp1 10216;
BA_ "SigType" SG_ 2566615591 Mot_Gen1InvTemp1 1;
BA_ "CI_ParId" SG_ 2566802465 OpsBlackOutIntensSel "1844";
BA_ "CI_SigId" SG_ 2566802465 OpsBlackOutIntensSel 4248;
BA_ "CI_SigName" SG_ 2566802465 OpsBlackOutIntensSel "Operators Black Out Intensity Selection";
BA_ "GenSigSendType" SG_ 2566802465 OpsBlackOutIntensSel 3;
BA_ "GenSigTimeoutTime_PCM" SG_ 2566802465 OpsBlackOutIntensSel 2500;
BA_ "SPN" SG_ 2566802465 OpsBlackOutIntensSel 1844;
BA_ "SigType" SG_ 2566802465 OpsBlackOutIntensSel 1;
BA_ "CI_ParId" SG_ 2566670131 A4MonTireCnt "6954";
BA_ "CI_SigId" SG_ 2566670131 A4MonTireCnt 6109;
BA_ "CI_SigName" SG_ 2566670131 A4MonTireCnt "Axle 4 Monitored Tire Count";
BA_ "SPN" SG_ 2566670131 A4MonTireCnt 6954;
BA_ "CI_ParId" SG_ 2566670131 A3MonTireCnt "6953";
BA_ "CI_SigId" SG_ 2566670131 A3MonTireCnt 6108;
BA_ "CI_SigName" SG_ 2566670131 A3MonTireCnt "Axle 3 Monitored Tire Count";
BA_ "SPN" SG_ 2566670131 A3MonTireCnt 6953;
BA_ "CI_ParId" SG_ 2566670131 A2MonTireCnt "6952";
BA_ "CI_SigId" SG_ 2566670131 A2MonTireCnt 6107;
BA_ "CI_SigName" SG_ 2566670131 A2MonTireCnt "Axle 2 Monitored Tire Count";
BA_ "SPN" SG_ 2566670131 A2MonTireCnt 6952;
BA_ "CI_ParId" SG_ 2566670131 A1MonTireCnt "6951";
BA_ "CI_SigId" SG_ 2566670131 A1MonTireCnt 6106;
BA_ "CI_SigName" SG_ 2566670131 A1MonTireCnt "Axle 1 Monitored Tire Count";
BA_ "SPN" SG_ 2566670131 A1MonTireCnt 6951;
BA_ "CI_ParId" SG_ 2566670131 NumOfTiresOnTheVeh "6950";
BA_ "CI_SigId" SG_ 2566670131 NumOfTiresOnTheVeh 6105;
BA_ "CI_SigName" SG_ 2566670131 NumOfTiresOnTheVeh "Number of Tires on the Vehicle";
BA_ "SPN" SG_ 2566670131 NumOfTiresOnTheVeh 6950;
BA_ "SigType" SG_ 2566670131 NumOfTiresOnTheVeh 1;
BA_ "CI_ParId" SG_ 2566670131 NumOfAxlesOnTheVeh "6949";
BA_ "CI_SigId" SG_ 2566670131 NumOfAxlesOnTheVeh 6104;
BA_ "CI_SigName" SG_ 2566670131 NumOfAxlesOnTheVeh "Number of Axles on the Vehicle";
BA_ "SPN" SG_ 2566670131 NumOfAxlesOnTheVeh 6949;
BA_ "CI_ParId" SG_ 2566898977 MsgCks_FFC521 "4207";
BA_ "CI_SigId" SG_ 2566898977 MsgCks_FFC521 40285;
BA_ "CI_SigName" SG_ 2566898977 MsgCks_FFC521 "Message Checksum";
BA_ "GenSigSendType" SG_ 2566898977 MsgCks_FFC521 3;
BA_ "GenSigTimeoutTime_PCM" SG_ 2566898977 MsgCks_FFC521 500;
BA_ "SPN" SG_ 2566898977 MsgCks_FFC521 4207;
BA_ "CI_ParId" SG_ 2566898977 MsgCnt_FFC521 "4206";
BA_ "CI_SigId" SG_ 2566898977 MsgCnt_FFC521 40284;
BA_ "CI_SigName" SG_ 2566898977 MsgCnt_FFC521 "Message Counter";
BA_ "GenSigSendType" SG_ 2566898977 MsgCnt_FFC521 3;
BA_ "GenSigTimeoutTime_PCM" SG_ 2566898977 MsgCnt_FFC521 500;
BA_ "SPN" SG_ 2566898977 MsgCnt_FFC521 4206;
BA_ "CI_ParId" SG_ 2566898977 EmerShutdnSwSts "ID2576";
BA_ "CI_SigId" SG_ 2566898977 EmerShutdnSwSts 45354;
BA_ "CI_SigName" SG_ 2566898977 EmerShutdnSwSts "Emergency Shutdown Switch Status";
BA_ "GenSigSendType" SG_ 2566898977 EmerShutdnSwSts 3;
BA_ "GenSigTimeoutTime_PCM" SG_ 2566898977 EmerShutdnSwSts 500;
BA_ "SigType" SG_ 2566898977 EmerShutdnSwSts 4;
BA_ "CI_ParId" SG_ 2566898977 WiperCtrlSts "ID2349";
BA_ "CI_SigId" SG_ 2566898977 WiperCtrlSts 43025;
BA_ "CI_SigName" SG_ 2566898977 WiperCtrlSts "Wiper Control Status";
BA_ "GenSigSendType" SG_ 2566898977 WiperCtrlSts 3;
BA_ "GenSigTimeoutTime_PCM" SG_ 2566898977 WiperCtrlSts 500;
BA_ "CI_ParId" SG_ 2566898977 EassVisCode "ID2269";
BA_ "CI_SigId" SG_ 2566898977 EassVisCode 42621;
BA_ "CI_SigName" SG_ 2566898977 EassVisCode "Stop and Start Visualisation Code";
BA_ "GenSigSendType" SG_ 2566898977 EassVisCode 3;
BA_ "GenSigTimeoutTime_PCM" SG_ 2566898977 EassVisCode 500;
BA_ "CI_ParId" SG_ 2566898977 EassActvSts "ID2268";
BA_ "CI_SigId" SG_ 2566898977 EassActvSts 42620;
BA_ "CI_SigName" SG_ 2566898977 EassActvSts "Stop and Start Activation Status";
BA_ "GenSigSendType" SG_ 2566898977 EassActvSts 3;
BA_ "GenSigTimeoutTime_PCM" SG_ 2566898977 EassActvSts 500;
BA_ "SigType" SG_ 2566898977 EassActvSts 4;
BA_ "CI_ParId" SG_ 2566898977 EmerHandKeyLckdSts "ID2270";
BA_ "CI_SigId" SG_ 2566898977 EmerHandKeyLckdSts 42619;
BA_ "CI_SigName" SG_ 2566898977 EmerHandKeyLckdSts "Emergency Handle Key Locked Status";
BA_ "GenSigSendType" SG_ 2566898977 EmerHandKeyLckdSts 3;
BA_ "GenSigTimeoutTime_PCM" SG_ 2566898977 EmerHandKeyLckdSts 500;
BA_ "SigType" SG_ 2566898977 EmerHandKeyLckdSts 4;
BA_ "CI_ParId" SG_ 2566898977 BatLampSts "ID2267";
BA_ "CI_SigId" SG_ 2566898977 BatLampSts 42618;
BA_ "CI_SigName" SG_ 2566898977 BatLampSts "Battery Lamp Status";
BA_ "GenSigSendType" SG_ 2566898977 BatLampSts 3;
BA_ "GenSigTimeoutTime_PCM" SG_ 2566898977 BatLampSts 500;
BA_ "SigType" SG_ 2566898977 BatLampSts 4;
BA_ "CI_ParId" SG_ 2566898977 PwrModeSts "ID2266";
BA_ "CI_SigId" SG_ 2566898977 PwrModeSts 42617;
BA_ "CI_SigName" SG_ 2566898977 PwrModeSts "Power Mode Status";
BA_ "GenSigSendType" SG_ 2566898977 PwrModeSts 3;
BA_ "GenSigTimeoutTime_PCM" SG_ 2566898977 PwrModeSts 500;
BA_ "SigType" SG_ 2566898977 PwrModeSts 4;
BA_ "CI_ParId" SG_ 2566898977 FpsSts "ID2264";
BA_ "CI_SigId" SG_ 2566898977 FpsSts 42616;
BA_ "CI_SigName" SG_ 2566898977 FpsSts "Fire Protection Switch Status";
BA_ "GenSigSendType" SG_ 2566898977 FpsSts 3;
BA_ "GenSigTimeoutTime_PCM" SG_ 2566898977 FpsSts 500;
BA_ "CI_ParId" SG_ 2566898977 ImmoCodeWarnLightSts "ID2265";
BA_ "CI_SigId" SG_ 2566898977 ImmoCodeWarnLightSts 42613;
BA_ "CI_SigName" SG_ 2566898977 ImmoCodeWarnLightSts "Immo Code Warning Light Status";
BA_ "GenSigSendType" SG_ 2566898977 ImmoCodeWarnLightSts 3;
BA_ "GenSigTimeoutTime_PCM" SG_ 2566898977 ImmoCodeWarnLightSts 500;
BA_ "CI_ParId" SG_ 2566898977 BrkPadWearSts "ID0257";
BA_ "CI_SigId" SG_ 2566898977 BrkPadWearSts 11153;
BA_ "CI_SigName" SG_ 2566898977 BrkPadWearSts "Brake Pad Wear Status";
BA_ "GenSigSendType" SG_ 2566898977 BrkPadWearSts 3;
BA_ "GenSigTimeoutTime_PCM" SG_ 2566898977 BrkPadWearSts 500;
BA_ "SigType" SG_ 2566898977 BrkPadWearSts 4;
BA_ "CI_ParId" SG_ 2566898977 BrkFluidLevLow "I043";
BA_ "CI_SigId" SG_ 2566898977 BrkFluidLevLow 11152;
BA_ "CI_SigName" SG_ 2566898977 BrkFluidLevLow "Brake Fluid Level Low";
BA_ "GenSigSendType" SG_ 2566898977 BrkFluidLevLow 3;
BA_ "GenSigTimeoutTime_PCM" SG_ 2566898977 BrkFluidLevLow 500;
BA_ "SigType" SG_ 2566898977 BrkFluidLevLow 4;
BA_ "CI_ParId" SG_ 2566898977 CeilLightSts "ID0255";
BA_ "CI_SigId" SG_ 2566898977 CeilLightSts 11151;
BA_ "CI_SigName" SG_ 2566898977 CeilLightSts "Ceiling Lights Status";
BA_ "GenSigSendType" SG_ 2566898977 CeilLightSts 3;
BA_ "GenSigTimeoutTime_PCM" SG_ 2566898977 CeilLightSts 500;
BA_ "SigType" SG_ 2566898977 CeilLightSts 4;
BA_ "CI_ParId" SG_ 2566898977 SysEolSts "ID2263";
BA_ "CI_SigId" SG_ 2566898977 SysEolSts 42612;
BA_ "CI_SigName" SG_ 2566898977 SysEolSts "Sys EOL Status";
BA_ "GenSigSendType" SG_ 2566898977 SysEolSts 3;
BA_ "GenSigTimeoutTime_PCM" SG_ 2566898977 SysEolSts 500;
BA_ "CI_ParId" SG_ 2566898977 BrkPedSts "ID2262";
BA_ "CI_SigId" SG_ 2566898977 BrkPedSts 42611;
BA_ "CI_SigName" SG_ 2566898977 BrkPedSts "Brake Pedal Status";
BA_ "GenSigSendType" SG_ 2566898977 BrkPedSts 3;
BA_ "GenSigTimeoutTime_PCM" SG_ 2566898977 BrkPedSts 500;
BA_ "CI_ParId" SG_ 2566898977 CrashOutSts "ID0254";
BA_ "CI_SigId" SG_ 2566898977 CrashOutSts 11150;
BA_ "CI_SigName" SG_ 2566898977 CrashOutSts "Crash Output Status";
BA_ "GenSigSendType" SG_ 2566898977 CrashOutSts 3;
BA_ "GenSigTimeoutTime_PCM" SG_ 2566898977 CrashOutSts 500;
BA_ "CI_ParId" SG_ 2566898977 WiperCtrl "ID0253";
BA_ "CI_SigId" SG_ 2566898977 WiperCtrl 11149;
BA_ "CI_SigName" SG_ 2566898977 WiperCtrl "Wiper Control";
BA_ "GenSigSendType" SG_ 2566898977 WiperCtrl 3;
BA_ "GenSigTimeoutTime_PCM" SG_ 2566898977 WiperCtrl 500;
BA_ "SigType" SG_ 2566898977 WiperCtrl 4;
BA_ "CI_ParId" SG_ 2566898977 VehAtStStill "ID0252";
BA_ "CI_SigId" SG_ 2566898977 VehAtStStill 11148;
BA_ "CI_SigName" SG_ 2566898977 VehAtStStill "Vehicle at Standstill";
BA_ "GenSigSendType" SG_ 2566898977 VehAtStStill 3;
BA_ "GenSigTimeoutTime_PCM" SG_ 2566898977 VehAtStStill 500;
BA_ "SigType" SG_ 2566898977 VehAtStStill 4;
BA_ "CI_ParId" SG_ 2566898977 PlugDoorBtn "ID0251";
BA_ "CI_SigId" SG_ 2566898977 PlugDoorBtn 11147;
BA_ "CI_SigName" SG_ 2566898977 PlugDoorBtn "Plug Door Button";
BA_ "GenSigSendType" SG_ 2566898977 PlugDoorBtn 3;
BA_ "GenSigTimeoutTime_PCM" SG_ 2566898977 PlugDoorBtn 500;
BA_ "SigType" SG_ 2566898977 PlugDoorBtn 4;
BA_ "CI_ParId" SG_ 2566898977 EngWaterLev "ID0250";
BA_ "CI_SigId" SG_ 2566898977 EngWaterLev 11146;
BA_ "CI_SigName" SG_ 2566898977 EngWaterLev "Engine Water Level";
BA_ "GenSigSendType" SG_ 2566898977 EngWaterLev 3;
BA_ "GenSigTimeoutTime_PCM" SG_ 2566898977 EngWaterLev 500;
BA_ "SigType" SG_ 2566898977 EngWaterLev 4;
BA_ "CI_ParId" SG_ 2566898977 SpotStsRear "ID0249";
BA_ "CI_SigId" SG_ 2566898977 SpotStsRear 11145;
BA_ "CI_SigName" SG_ 2566898977 SpotStsRear "Spot Status, Rear";
BA_ "GenSigSendType" SG_ 2566898977 SpotStsRear 3;
BA_ "GenSigTimeoutTime_PCM" SG_ 2566898977 SpotStsRear 500;
BA_ "SigType" SG_ 2566898977 SpotStsRear 4;
BA_ "CI_ParId" SG_ 2566898977 PtoDrivResp "ID0248";
BA_ "CI_SigId" SG_ 2566898977 PtoDrivResp 11144;
BA_ "CI_SigName" SG_ 2566898977 PtoDrivResp "PTO Driver Response";
BA_ "GenSigSendType" SG_ 2566898977 PtoDrivResp 3;
BA_ "GenSigTimeoutTime_PCM" SG_ 2566898977 PtoDrivResp 500;
BA_ "SigType" SG_ 2566898977 PtoDrivResp 4;
BA_ "CI_ParId" SG_ 2566898977 SeatBeltRemindSts "ID0247";
BA_ "CI_SigId" SG_ 2566898977 SeatBeltRemindSts 11143;
BA_ "CI_SigName" SG_ 2566898977 SeatBeltRemindSts "Seat Belt Reminder Status";
BA_ "GenSigSendType" SG_ 2566898977 SeatBeltRemindSts 3;
BA_ "GenSigTimeoutTime_PCM" SG_ 2566898977 SeatBeltRemindSts 500;
BA_ "SigType" SG_ 2566898977 SeatBeltRemindSts 4;
BA_ "CI_ParId" SG_ 2566898977 InternLightSts "ID0246";
BA_ "CI_SigId" SG_ 2566898977 InternLightSts 11142;
BA_ "CI_SigName" SG_ 2566898977 InternLightSts "Internal Lights Status";
BA_ "GenSigSendType" SG_ 2566898977 InternLightSts 3;
BA_ "GenSigTimeoutTime_PCM" SG_ 2566898977 InternLightSts 500;
BA_ "CI_ParId" SG_ 2566898977 RechargeSts "ID0245";
BA_ "CI_SigId" SG_ 2566898977 RechargeSts 11141;
BA_ "CI_SigName" SG_ 2566898977 RechargeSts "Recharge Status";
BA_ "GenSigSendType" SG_ 2566898977 RechargeSts 3;
BA_ "GenSigTimeoutTime_PCM" SG_ 2566898977 RechargeSts 500;
BA_ "CI_ParId" SG_ 2566776106 MaxVsl3 "2590";
BA_ "CI_SigId" SG_ 2566776106 MaxVsl3 43959;
BA_ "CI_SigName" SG_ 2566776106 MaxVsl3 "Maximum Vehicle Speed Limit 3";
BA_ "GenSigSendType" SG_ 2566776106 MaxVsl3 3;
BA_ "GenSigTimeoutTime_PCM" SG_ 2566776106 MaxVsl3 5000;
BA_ "SPN" SG_ 2566776106 MaxVsl3 2590;
BA_ "SigType" SG_ 2566776106 MaxVsl3 1;
BA_ "CI_ParId" SG_ 2566776106 MaxVsl2 "2589";
BA_ "CI_SigId" SG_ 2566776106 MaxVsl2 42804;
BA_ "CI_SigName" SG_ 2566776106 MaxVsl2 "Maximum Vehicle Speed Limit 2";
BA_ "GenSigSendType" SG_ 2566776106 MaxVsl2 3;
BA_ "GenSigTimeoutTime_PCM" SG_ 2566776106 MaxVsl2 5000;
BA_ "SPN" SG_ 2566776106 MaxVsl2 2589;
BA_ "SigType" SG_ 2566776106 MaxVsl2 1;
BA_ "CI_ParId" SG_ 2499614241 DrivOccpClassSysSts "4963";
BA_ "CI_SigId" SG_ 2499614241 DrivOccpClassSysSts 4432;
BA_ "CI_SigName" SG_ 2499614241 DrivOccpClassSysSts "Driver Occupant Classification System Status";
BA_ "GenSigSendType" SG_ 2499614241 DrivOccpClassSysSts 3;
BA_ "GenSigTimeoutTime_PCM" SG_ 2499614241 DrivOccpClassSysSts 25000;
BA_ "SPN" SG_ 2499614241 DrivOccpClassSysSts 4963;
BA_ "CI_ParId" SG_ 2499614291 OccpClassSys3Sts "4965";
BA_ "CI_SigId" SG_ 2499614291 OccpClassSys3Sts 44440;
BA_ "CI_SigName" SG_ 2499614291 OccpClassSys3Sts "Occupant Classification System 3 Status";
BA_ "GenSigSendType" SG_ 2499614291 OccpClassSys3Sts 3;
BA_ "GenSigTimeoutTime_PCM" SG_ 2499614291 OccpClassSys3Sts 25000;
BA_ "SPN" SG_ 2499614291 OccpClassSys3Sts 4965;
BA_ "SigType" SG_ 2499614291 OccpClassSys3Sts 4;
BA_ "CI_ParId" SG_ 2499614291 PassOccpClassSysSts "4964";
BA_ "CI_SigId" SG_ 2499614291 PassOccpClassSysSts 44439;
BA_ "CI_SigName" SG_ 2499614291 PassOccpClassSysSts "Passenger Occupant Classification System Status";
BA_ "GenSigSendType" SG_ 2499614291 PassOccpClassSysSts 3;
BA_ "GenSigTimeoutTime_PCM" SG_ 2499614291 PassOccpClassSysSts 25000;
BA_ "SPN" SG_ 2499614291 PassOccpClassSysSts 4964;
BA_ "CI_ParId" SG_ 2499614291 DrivOccpClassSysSts_FD1653 "4963";
BA_ "CI_SigId" SG_ 2499614291 DrivOccpClassSysSts_FD1653 44438;
BA_ "CI_SigName" SG_ 2499614291 DrivOccpClassSysSts_FD1653 "Driver Occupant Classification System Status";
BA_ "GenSigSendType" SG_ 2499614291 DrivOccpClassSysSts_FD1653 3;
BA_ "GenSigTimeoutTime_PCM" SG_ 2499614291 DrivOccpClassSysSts_FD1653 25000;
BA_ "SPN" SG_ 2499614291 DrivOccpClassSysSts_FD1653 4963;
BA_ "CI_ParId" SG_ 2365443105 HighLowBeamSw "2874";
BA_ "CI_SigId" SG_ 2365443105 HighLowBeamSw 4221;
BA_ "CI_SigName" SG_ 2365443105 HighLowBeamSw "High-Low Beam Switch";
BA_ "GenSigSendType" SG_ 2365443105 HighLowBeamSw 3;
BA_ "GenSigTimeoutTime_PCM" SG_ 2365443105 HighLowBeamSw 5000;
BA_ "SPN" SG_ 2365443105 HighLowBeamSw 2874;
BA_ "SigType" SG_ 2365443105 HighLowBeamSw 4;
BA_ "CI_ParId" SG_ 2365443105 HazardLightSw "2875";
BA_ "CI_SigId" SG_ 2365443105 HazardLightSw 4220;
BA_ "CI_SigName" SG_ 2365443105 HazardLightSw "Hazard Light Switch";
BA_ "GenSigSendType" SG_ 2365443105 HazardLightSw 3;
BA_ "GenSigTimeoutTime_PCM" SG_ 2365443105 HazardLightSw 5000;
BA_ "SPN" SG_ 2365443105 HazardLightSw 2875;
BA_ "SigType" SG_ 2365443105 HazardLightSw 4;
BA_ "CI_ParId" SG_ 2365443105 TurnSigSw "2876";
BA_ "CI_SigId" SG_ 2365443105 TurnSigSw 4219;
BA_ "CI_SigName" SG_ 2365443105 TurnSigSw "Turn Signal Switch";
BA_ "GenSigSendType" SG_ 2365443105 TurnSigSw 3;
BA_ "GenSigTimeoutTime_PCM" SG_ 2365443105 TurnSigSw 5000;
BA_ "SPN" SG_ 2365443105 TurnSigSw 2876;
BA_ "CI_ParId" SG_ 2365443105 MainLightSw "2872";
BA_ "CI_SigId" SG_ 2365443105 MainLightSw 4218;
BA_ "CI_SigName" SG_ 2365443105 MainLightSw "Main Light Switch";
BA_ "GenSigSendType" SG_ 2365443105 MainLightSw 3;
BA_ "GenSigTimeoutTime_PCM" SG_ 2365443105 MainLightSw 5000;
BA_ "SPN" SG_ 2365443105 MainLightSw 2872;
BA_ "CI_ParId" SG_ 2566769953 FrontOpWiperSw "2863";
BA_ "CI_SigId" SG_ 2566769953 FrontOpWiperSw 4251;
BA_ "CI_SigName" SG_ 2566769953 FrontOpWiperSw "Front Operator Wiper Switch";
BA_ "GenSigSendType" SG_ 2566769953 FrontOpWiperSw 3;
BA_ "GenSigTimeoutTime_PCM" SG_ 2566769953 FrontOpWiperSw 5000;
BA_ "SPN" SG_ 2566769953 FrontOpWiperSw 2863;
BA_ "CI_ParId" SG_ 2565865249 ImmoEmerProc "I457";
BA_ "CI_SigId" SG_ 2565865249 ImmoEmerProc 11262;
BA_ "CI_SigName" SG_ 2565865249 ImmoEmerProc "Immobilizer Emergency Procedure";
BA_ "GenSigSendType" SG_ 2565865249 ImmoEmerProc 3;
BA_ "GenSigTimeoutTime_PCM" SG_ 2565865249 ImmoEmerProc 5000;
BA_ "SigType" SG_ 2565865249 ImmoEmerProc 1;
BA_ "CI_ParId" SG_ 2565865249 CtrlByte "I900";
BA_ "CI_SigId" SG_ 2565865249 CtrlByte 11254;
BA_ "CI_SigName" SG_ 2565865249 CtrlByte "Control Byte (Iveco Function)";
BA_ "GenSigSendType" SG_ 2565865249 CtrlByte 3;
BA_ "GenSigTimeoutTime_PCM" SG_ 2565865249 CtrlByte 5000;
BA_ "CI_ParId" SG_ 2566907681 EvsCmd "ID1474";
BA_ "CI_SigId" SG_ 2566907681 EvsCmd 8886;
BA_ "CI_SigName" SG_ 2566907681 EvsCmd "Valves Command";
BA_ "GenSigTimeoutTime_PCM" SG_ 2566907681 EvsCmd 5000;
BA_ "CI_ParId" SG_ 2566907681 PtcCabPumpCmd "ID1475";
BA_ "CI_SigId" SG_ 2566907681 PtcCabPumpCmd 8885;
BA_ "CI_SigName" SG_ 2566907681 PtcCabPumpCmd "Ptc Cabin Pump Command";
BA_ "GenSigTimeoutTime_PCM" SG_ 2566907681 PtcCabPumpCmd 5000;
BA_ "SigType" SG_ 2566907681 PtcCabPumpCmd 4;
BA_ "CI_ParId" SG_ 2566907681 HvacPtcCabCmd "ID1472";
BA_ "CI_SigId" SG_ 2566907681 HvacPtcCabCmd 8884;
BA_ "CI_SigName" SG_ 2566907681 HvacPtcCabCmd "HVAC Ptc Cabin Command";
BA_ "GenSigTimeoutTime_PCM" SG_ 2566907681 HvacPtcCabCmd 5000;
BA_ "SigType" SG_ 2566907681 HvacPtcCabCmd 4;
BA_ "CI_ParId" SG_ 2566907681 ElFanCmd "ID1470";
BA_ "CI_SigId" SG_ 2566907681 ElFanCmd 8883;
BA_ "CI_SigName" SG_ 2566907681 ElFanCmd "Electric Fan Command";
BA_ "GenSigTimeoutTime_PCM" SG_ 2566907681 ElFanCmd 5000;
BA_ "SigType" SG_ 2566907681 ElFanCmd 4;
BA_ "CI_ParId" SG_ 2566907681 PtcCabPumpSpeedPcCmd "ID1476";
BA_ "CI_SigId" SG_ 2566907681 PtcCabPumpSpeedPcCmd 8882;
BA_ "CI_SigName" SG_ 2566907681 PtcCabPumpSpeedPcCmd "Ptc Cabin Pump Speed Percent Command";
BA_ "GenSigTimeoutTime_PCM" SG_ 2566907681 PtcCabPumpSpeedPcCmd 5000;
BA_ "SigType" SG_ 2566907681 PtcCabPumpSpeedPcCmd 1;
BA_ "CI_ParId" SG_ 2566907681 HvacPtcCabPcCmd "ID1473";
BA_ "CI_SigId" SG_ 2566907681 HvacPtcCabPcCmd 8881;
BA_ "CI_SigName" SG_ 2566907681 HvacPtcCabPcCmd "HVAC Ptc Cabin Percent Command";
BA_ "GenSigTimeoutTime_PCM" SG_ 2566907681 HvacPtcCabPcCmd 5000;
BA_ "SigType" SG_ 2566907681 HvacPtcCabPcCmd 1;
BA_ "CI_ParId" SG_ 2566907681 ElFanSpeedCmd "ID1471";
BA_ "CI_SigId" SG_ 2566907681 ElFanSpeedCmd 8880;
BA_ "CI_SigName" SG_ 2566907681 ElFanSpeedCmd "Electric Fan Speed Command";
BA_ "GenSigTimeoutTime_PCM" SG_ 2566907681 ElFanSpeedCmd 5000;
BA_ "SigType" SG_ 2566907681 ElFanSpeedCmd 1;
BA_ "CI_ParId" SG_ 2566907943 CabCoolTemp "ID2025";
BA_ "CI_SigId" SG_ 2566907943 CabCoolTemp 41260;
BA_ "CI_SigName" SG_ 2566907943 CabCoolTemp "Cabin Coolant Temperature";
BA_ "GenSigTimeoutTime_PCM" SG_ 2566907943 CabCoolTemp 5000;
BA_ "SigType" SG_ 2566907943 CabCoolTemp 1;
BA_ "CI_ParId" SG_ 2566907943 ClimaWorkMode "ID1549";
BA_ "CI_SigId" SG_ 2566907943 ClimaWorkMode 37748;
BA_ "CI_SigName" SG_ 2566907943 ClimaWorkMode "Clima Working Mode";
BA_ "GenSigTimeoutTime_PCM" SG_ 2566907943 ClimaWorkMode 5000;
BA_ "SigType" SG_ 2566907943 ClimaWorkMode 4;
BA_ "CI_ParId" SG_ 2566907943 EvsSts "ID1467";
BA_ "CI_SigId" SG_ 2566907943 EvsSts 8921;
BA_ "CI_SigName" SG_ 2566907943 EvsSts "Valves Status";
BA_ "GenSigTimeoutTime_PCM" SG_ 2566907943 EvsSts 5000;
BA_ "CI_ParId" SG_ 2566907943 AutoClimaPrs "ID1462";
BA_ "CI_SigId" SG_ 2566907943 AutoClimaPrs 8920;
BA_ "CI_SigName" SG_ 2566907943 AutoClimaPrs "Automatic Climate Pressure";
BA_ "GenSigTimeoutTime_PCM" SG_ 2566907943 AutoClimaPrs 5000;
BA_ "SigType" SG_ 2566907943 AutoClimaPrs 1;
BA_ "CI_ParId" SG_ 2566907943 AewhSts "ID2588";
BA_ "CI_SigId" SG_ 2566907943 AewhSts 45404;
BA_ "CI_SigName" SG_ 2566907943 AewhSts "AEWH Status";
BA_ "GenSigTimeoutTime_PCM" SG_ 2566907943 AewhSts 5000;
BA_ "SigType" SG_ 2566907943 AewhSts 4;
BA_ "CI_ParId" SG_ 2566907943 PtcCabPumpSts "ID1468";
BA_ "CI_SigId" SG_ 2566907943 PtcCabPumpSts 8919;
BA_ "CI_SigName" SG_ 2566907943 PtcCabPumpSts "Ptc Cabin Pump Status";
BA_ "GenSigTimeoutTime_PCM" SG_ 2566907943 PtcCabPumpSts 5000;
BA_ "SigType" SG_ 2566907943 PtcCabPumpSts 4;
BA_ "CI_ParId" SG_ 2566907943 HvacPtcCabSts "ID1465";
BA_ "CI_SigId" SG_ 2566907943 HvacPtcCabSts 8918;
BA_ "CI_SigName" SG_ 2566907943 HvacPtcCabSts "HVAC Ptc Cabin Status";
BA_ "GenSigTimeoutTime_PCM" SG_ 2566907943 HvacPtcCabSts 5000;
BA_ "SigType" SG_ 2566907943 HvacPtcCabSts 4;
BA_ "CI_ParId" SG_ 2566907943 ElFanSts "ID1463";
BA_ "CI_SigId" SG_ 2566907943 ElFanSts 8917;
BA_ "CI_SigName" SG_ 2566907943 ElFanSts "Electric Fan Status";
BA_ "GenSigTimeoutTime_PCM" SG_ 2566907943 ElFanSts 5000;
BA_ "SigType" SG_ 2566907943 ElFanSts 4;
BA_ "CI_ParId" SG_ 2566907943 PtcCabPumpSpeedPcSts "ID1469";
BA_ "CI_SigId" SG_ 2566907943 PtcCabPumpSpeedPcSts 8916;
BA_ "CI_SigName" SG_ 2566907943 PtcCabPumpSpeedPcSts "Ptc Cabin Pump Speed Percent Status";
BA_ "GenSigTimeoutTime_PCM" SG_ 2566907943 PtcCabPumpSpeedPcSts 5000;
BA_ "SigType" SG_ 2566907943 PtcCabPumpSpeedPcSts 1;
BA_ "CI_ParId" SG_ 2566907943 HvacPtcCabPcSts "ID1466";
BA_ "CI_SigId" SG_ 2566907943 HvacPtcCabPcSts 8915;
BA_ "CI_SigName" SG_ 2566907943 HvacPtcCabPcSts "HVAC Ptc Cabin Percent Status";
BA_ "GenSigTimeoutTime_PCM" SG_ 2566907943 HvacPtcCabPcSts 5000;
BA_ "SigType" SG_ 2566907943 HvacPtcCabPcSts 1;
BA_ "CI_ParId" SG_ 2566907943 ElFanSpeedSts "ID1464";
BA_ "CI_SigId" SG_ 2566907943 ElFanSpeedSts 8914;
BA_ "CI_SigName" SG_ 2566907943 ElFanSpeedSts "Electric Fan Speed Status";
BA_ "GenSigTimeoutTime_PCM" SG_ 2566907943 ElFanSpeedSts 5000;
BA_ "SigType" SG_ 2566907943 ElFanSpeedSts 1;
BA_ "CI_ParId" SG_ 2566895127 DdawAcousticWarnCfg "ID2445";
BA_ "CI_SigId" SG_ 2566895127 DdawAcousticWarnCfg 44477;
BA_ "CI_SigName" SG_ 2566895127 DdawAcousticWarnCfg "DDAW Acoustic Warning Configuration";
BA_ "GenSigSendType" SG_ 2566895127 DdawAcousticWarnCfg 3;
BA_ "GenSigTimeoutTime_PCM" SG_ 2566895127 DdawAcousticWarnCfg 5000;
BA_ "SigType" SG_ 2566895127 DdawAcousticWarnCfg 4;
BA_ "CI_ParId" SG_ 2566895127 DdawSens "ID2337";
BA_ "CI_SigId" SG_ 2566895127 DdawSens 42339;
BA_ "CI_SigName" SG_ 2566895127 DdawSens "DDAW Sensitivity ";
BA_ "GenSigSendType" SG_ 2566895127 DdawSens 3;
BA_ "GenSigTimeoutTime_PCM" SG_ 2566895127 DdawSens 5000;
BA_ "SigType" SG_ 2566895127 DdawSens 4;
BA_ "CI_ParId" SG_ 2566895127 DdawWarnCfg "ID2336";
BA_ "CI_SigId" SG_ 2566895127 DdawWarnCfg 42338;
BA_ "CI_SigName" SG_ 2566895127 DdawWarnCfg "DDAW Warning Configuration";
BA_ "GenSigSendType" SG_ 2566895127 DdawWarnCfg 3;
BA_ "GenSigTimeoutTime_PCM" SG_ 2566895127 DdawWarnCfg 5000;
BA_ "SigType" SG_ 2566895127 DdawWarnCfg 4;
BA_ "CI_ParId" SG_ 2566895127 LaneChgAssCfg "ID2330";
BA_ "CI_SigId" SG_ 2566895127 LaneChgAssCfg 42822;
BA_ "CI_SigName" SG_ 2566895127 LaneChgAssCfg "Lane Change Assist Configuration";
BA_ "GenSigSendType" SG_ 2566895127 LaneChgAssCfg 3;
BA_ "GenSigTimeoutTime_PCM" SG_ 2566895127 LaneChgAssCfg 5000;
BA_ "SigType" SG_ 2566895127 LaneChgAssCfg 4;
BA_ "CI_ParId" SG_ 2566895127 DoorOpenWarnFunctCfg "ID2247";
BA_ "CI_SigId" SG_ 2566895127 DoorOpenWarnFunctCfg 42821;
BA_ "CI_SigName" SG_ 2566895127 DoorOpenWarnFunctCfg "Door Open Warning Function Configuration";
BA_ "GenSigSendType" SG_ 2566895127 DoorOpenWarnFunctCfg 3;
BA_ "GenSigTimeoutTime_PCM" SG_ 2566895127 DoorOpenWarnFunctCfg 5000;
BA_ "SigType" SG_ 2566895127 DoorOpenWarnFunctCfg 4;
BA_ "CI_ParId" SG_ 2566895137 AlcoholIntLckCrkEnaSts "ID2244";
BA_ "CI_SigId" SG_ 2566895137 AlcoholIntLckCrkEnaSts 42343;
BA_ "CI_SigName" SG_ 2566895137 AlcoholIntLckCrkEnaSts "Alcohol Interlock Cranking Enable Status";
BA_ "GenSigTimeoutTime_PCM" SG_ 2566895137 AlcoholIntLckCrkEnaSts 1000;
BA_ "CI_ParId" SG_ 2566895146 DdawAcousticWarn "ID2389";
BA_ "CI_SigId" SG_ 2566895146 DdawAcousticWarn 43780;
BA_ "CI_SigName" SG_ 2566895146 DdawAcousticWarn "DDAW Acoustic Warning";
BA_ "GenSigTimeoutTime_PCM" SG_ 2566895146 DdawAcousticWarn 1000;
BA_ "SigType" SG_ 2566895146 DdawAcousticWarn 4;
BA_ "CI_ParId" SG_ 2566895146 DdawVisualWarn "ID2388";
BA_ "CI_SigId" SG_ 2566895146 DdawVisualWarn 43779;
BA_ "CI_SigName" SG_ 2566895146 DdawVisualWarn "DDAW Visual Warning";
BA_ "GenSigTimeoutTime_PCM" SG_ 2566895146 DdawVisualWarn 1000;
BA_ "SigType" SG_ 2566895146 DdawVisualWarn 4;
BA_ "CI_ParId" SG_ 2566895146 DdawRunMode "ID2246";
BA_ "CI_SigId" SG_ 2566895146 DdawRunMode 42348;
BA_ "CI_SigName" SG_ 2566895146 DdawRunMode "DDAW Running Mode";
BA_ "GenSigTimeoutTime_PCM" SG_ 2566895146 DdawRunMode 1000;
BA_ "SigType" SG_ 2566895146 DdawRunMode 4;
BA_ "CI_ParId" SG_ 2566895146 DrowsinessDrivLev "ID2245";
BA_ "CI_SigId" SG_ 2566895146 DrowsinessDrivLev 42347;
BA_ "CI_SigName" SG_ 2566895146 DrowsinessDrivLev "Drowsiness Driver Level";
BA_ "GenSigTimeoutTime_PCM" SG_ 2566895146 DrowsinessDrivLev 1000;
BA_ "CI_ParId" SG_ 2566895178 DoorOpenWarnFunctCfg_FFB64A "ID2247";
BA_ "CI_SigId" SG_ 2566895178 DoorOpenWarnFunctCfg_FFB64A 44489;
BA_ "CI_SigName" SG_ 2566895178 DoorOpenWarnFunctCfg_FFB64A "Door Open Warning Function Configuration";
BA_ "SigType" SG_ 2566895178 DoorOpenWarnFunctCfg_FFB64A 4;
BA_ "CI_ParId" SG_ 2566895260 DoorOpenWarnFunctStsLeft "ID2250";
BA_ "CI_SigId" SG_ 2566895260 DoorOpenWarnFunctStsLeft 42817;
BA_ "CI_SigName" SG_ 2566895260 DoorOpenWarnFunctStsLeft "Door Open Warning Function Status Left";
BA_ "GenSigTimeoutTime_PCM" SG_ 2566895260 DoorOpenWarnFunctStsLeft 1000;
BA_ "SigType" SG_ 2566895260 DoorOpenWarnFunctStsLeft 4;
BA_ "CI_ParId" SG_ 2566895260 DoorOpenWarnFunctStsRight "ID2249";
BA_ "CI_SigId" SG_ 2566895260 DoorOpenWarnFunctStsRight 42816;
BA_ "CI_SigName" SG_ 2566895260 DoorOpenWarnFunctStsRight "Door Open Warning Function Status Right";
BA_ "GenSigTimeoutTime_PCM" SG_ 2566895260 DoorOpenWarnFunctStsRight 1000;
BA_ "SigType" SG_ 2566895260 DoorOpenWarnFunctStsRight 4;
BA_ "CI_ParId" SG_ 2566895260 DoorOpenWarnAlertLeft "ID2248";
BA_ "CI_SigId" SG_ 2566895260 DoorOpenWarnAlertLeft 42815;
BA_ "CI_SigName" SG_ 2566895260 DoorOpenWarnAlertLeft "Door Open Warning Alert Left";
BA_ "GenSigTimeoutTime_PCM" SG_ 2566895260 DoorOpenWarnAlertLeft 1000;
BA_ "SigType" SG_ 2566895260 DoorOpenWarnAlertLeft 4;
BA_ "CI_ParId" SG_ 2566895260 DoorOpenWarnAlertRight "ID2248";
BA_ "CI_SigId" SG_ 2566895260 DoorOpenWarnAlertRight 42352;
BA_ "CI_SigName" SG_ 2566895260 DoorOpenWarnAlertRight "Door Open Warning Alert Right";
BA_ "GenSigTimeoutTime_PCM" SG_ 2566895260 DoorOpenWarnAlertRight 1000;
BA_ "SigType" SG_ 2566895260 DoorOpenWarnAlertRight 4;
BA_ "CI_ParId" SG_ 2583654703 MsgCks_FF712F "4207";
BA_ "CI_SigId" SG_ 2583654703 MsgCks_FF712F 37796;
BA_ "CI_SigName" SG_ 2583654703 MsgCks_FF712F "Message Checksum";
BA_ "GenSigSendType" SG_ 2583654703 MsgCks_FF712F 3;
BA_ "GenSigTimeoutTime_PCM" SG_ 2583654703 MsgCks_FF712F 50000;
BA_ "SPN" SG_ 2583654703 MsgCks_FF712F 4207;
BA_ "CI_ParId" SG_ 2583654703 MsgCnt_FF712F "4206";
BA_ "CI_SigId" SG_ 2583654703 MsgCnt_FF712F 37795;
BA_ "CI_SigName" SG_ 2583654703 MsgCnt_FF712F "Message Counter";
BA_ "GenSigSendType" SG_ 2583654703 MsgCnt_FF712F 3;
BA_ "GenSigTimeoutTime_PCM" SG_ 2583654703 MsgCnt_FF712F 50000;
BA_ "SPN" SG_ 2583654703 MsgCnt_FF712F 4206;
BA_ "CI_ParId" SG_ 2583654703 EcasCustomInds "ID2558";
BA_ "CI_SigId" SG_ 2583654703 EcasCustomInds 45125;
BA_ "CI_SigName" SG_ 2583654703 EcasCustomInds "ECAS Custom Indications";
BA_ "GenSigSendType" SG_ 2583654703 EcasCustomInds 3;
BA_ "GenSigTimeoutTime_PCM" SG_ 2583654703 EcasCustomInds 50000;
BA_ "CI_ParId" SG_ 2583654703 RsvAv "ID2557";
BA_ "CI_SigId" SG_ 2583654703 RsvAv 45124;
BA_ "CI_SigName" SG_ 2583654703 RsvAv "Reservoir Availability";
BA_ "GenSigSendType" SG_ 2583654703 RsvAv 3;
BA_ "GenSigTimeoutTime_PCM" SG_ 2583654703 RsvAv 50000;
BA_ "SigType" SG_ 2583654703 RsvAv 4;
BA_ "CI_ParId" SG_ 2583654703 FusyLamps "ID2556";
BA_ "CI_SigId" SG_ 2583654703 FusyLamps 45123;
BA_ "CI_SigName" SG_ 2583654703 FusyLamps "Fusy Lamps";
BA_ "GenSigSendType" SG_ 2583654703 FusyLamps 3;
BA_ "GenSigTimeoutTime_PCM" SG_ 2583654703 FusyLamps 50000;
BA_ "CI_ParId" SG_ 2583654703 SamReq "ID2136";
BA_ "CI_SigId" SG_ 2583654703 SamReq 41805;
BA_ "CI_SigName" SG_ 2583654703 SamReq "SAM Request";
BA_ "GenSigSendType" SG_ 2583654703 SamReq 3;
BA_ "GenSigTimeoutTime_PCM" SG_ 2583654703 SamReq 50000;
BA_ "CI_ParId" SG_ 2583654703 MemRearEnd "ID1559";
BA_ "CI_SigId" SG_ 2583654703 MemRearEnd 37794;
BA_ "CI_SigName" SG_ 2583654703 MemRearEnd "Memory Rear End";
BA_ "GenSigSendType" SG_ 2583654703 MemRearEnd 3;
BA_ "GenSigTimeoutTime_PCM" SG_ 2583654703 MemRearEnd 50000;
BA_ "SigType" SG_ 2583654703 MemRearEnd 4;
BA_ "CI_ParId" SG_ 2583654703 DwRearEnd "ID1558";
BA_ "CI_SigId" SG_ 2583654703 DwRearEnd 37793;
BA_ "CI_SigName" SG_ 2583654703 DwRearEnd "Down Rear End";
BA_ "GenSigSendType" SG_ 2583654703 DwRearEnd 3;
BA_ "GenSigTimeoutTime_PCM" SG_ 2583654703 DwRearEnd 50000;
BA_ "SigType" SG_ 2583654703 DwRearEnd 4;
BA_ "CI_ParId" SG_ 2583654703 UpRearEnd "ID1557";
BA_ "CI_SigId" SG_ 2583654703 UpRearEnd 37792;
BA_ "CI_SigName" SG_ 2583654703 UpRearEnd "Up Rear End";
BA_ "GenSigSendType" SG_ 2583654703 UpRearEnd 3;
BA_ "GenSigTimeoutTime_PCM" SG_ 2583654703 UpRearEnd 50000;
BA_ "SigType" SG_ 2583654703 UpRearEnd 4;
BA_ "CI_ParId" SG_ 2583654703 MemDashboard "ID1556";
BA_ "CI_SigId" SG_ 2583654703 MemDashboard 37791;
BA_ "CI_SigName" SG_ 2583654703 MemDashboard "Memory Dashboard";
BA_ "GenSigSendType" SG_ 2583654703 MemDashboard 3;
BA_ "GenSigTimeoutTime_PCM" SG_ 2583654703 MemDashboard 50000;
BA_ "SigType" SG_ 2583654703 MemDashboard 4;
BA_ "CI_ParId" SG_ 2583654703 StoredVehHtVal "ID1552";
BA_ "CI_SigId" SG_ 2583654703 StoredVehHtVal 37787;
BA_ "CI_SigName" SG_ 2583654703 StoredVehHtVal "Stored Vehicle Height Value";
BA_ "GenSigSendType" SG_ 2583654703 StoredVehHtVal 3;
BA_ "GenSigTimeoutTime_PCM" SG_ 2583654703 StoredVehHtVal 50000;
BA_ "SigType" SG_ 2583654703 StoredVehHtVal 1;
BA_ "CI_ParId" SG_ 2583654703 CurVehHtVal "ID1551";
BA_ "CI_SigId" SG_ 2583654703 CurVehHtVal 37786;
BA_ "CI_SigName" SG_ 2583654703 CurVehHtVal "Current Vehicle Height Value";
BA_ "GenSigSendType" SG_ 2583654703 CurVehHtVal 3;
BA_ "GenSigTimeoutTime_PCM" SG_ 2583654703 CurVehHtVal 50000;
BA_ "SigType" SG_ 2583654703 CurVehHtVal 1;
BA_ "CI_ParId" SG_ 2583654703 DrivDashboard "ID1555";
BA_ "CI_SigId" SG_ 2583654703 DrivDashboard 37790;
BA_ "CI_SigName" SG_ 2583654703 DrivDashboard "Drive Dashboard";
BA_ "GenSigSendType" SG_ 2583654703 DrivDashboard 3;
BA_ "GenSigTimeoutTime_PCM" SG_ 2583654703 DrivDashboard 50000;
BA_ "SigType" SG_ 2583654703 DrivDashboard 4;
BA_ "CI_ParId" SG_ 2583654703 DwDashboard "ID1554";
BA_ "CI_SigId" SG_ 2583654703 DwDashboard 37789;
BA_ "CI_SigName" SG_ 2583654703 DwDashboard "Down Dashboard";
BA_ "GenSigSendType" SG_ 2583654703 DwDashboard 3;
BA_ "GenSigTimeoutTime_PCM" SG_ 2583654703 DwDashboard 50000;
BA_ "SigType" SG_ 2583654703 DwDashboard 4;
BA_ "CI_ParId" SG_ 2583654703 UpDashboard "ID1553";
BA_ "CI_SigId" SG_ 2583654703 UpDashboard 37788;
BA_ "CI_SigName" SG_ 2583654703 UpDashboard "Up Dashboard";
BA_ "GenSigSendType" SG_ 2583654703 UpDashboard 3;
BA_ "GenSigTimeoutTime_PCM" SG_ 2583654703 UpDashboard 50000;
BA_ "SigType" SG_ 2583654703 UpDashboard 4;
BA_ "CI_ParId" SG_ 2583654703 TurnLightCmd "ID0977";
BA_ "CI_SigId" SG_ 2583654703 TurnLightCmd 35140;
BA_ "CI_SigName" SG_ 2583654703 TurnLightCmd "Turn Lights Command";
BA_ "GenSigSendType" SG_ 2583654703 TurnLightCmd 3;
BA_ "GenSigTimeoutTime_PCM" SG_ 2583654703 TurnLightCmd 50000;
BA_ "SigType" SG_ 2583654703 TurnLightCmd 4;
BA_ "CI_ParId" SG_ 2566902551 WindshWiperAutoSens "I356";
BA_ "CI_SigId" SG_ 2566902551 WindshWiperAutoSens 6277;
BA_ "CI_SigName" SG_ 2566902551 WindshWiperAutoSens "Windshield Wiper Auto Sensitivity";
BA_ "GenSigSendType" SG_ 2566902551 WindshWiperAutoSens 3;
BA_ "GenSigTimeoutTime_PCM" SG_ 2566902551 WindshWiperAutoSens 5000;
BA_ "CI_ParId" SG_ 2566902551 LowBeamLightAutoSens "I261";
BA_ "CI_SigId" SG_ 2566902551 LowBeamLightAutoSens 6276;
BA_ "CI_SigName" SG_ 2566902551 LowBeamLightAutoSens "Low Beam Lights Auto Sensitivity";
BA_ "GenSigSendType" SG_ 2566902551 LowBeamLightAutoSens 3;
BA_ "GenSigTimeoutTime_PCM" SG_ 2566902551 LowBeamLightAutoSens 5000;
BA_ "CI_ParId" SG_ 2566902551 FogLightCornEna "I281";
BA_ "CI_SigId" SG_ 2566902551 FogLightCornEna 6275;
BA_ "CI_SigName" SG_ 2566902551 FogLightCornEna "Fog Lights Cornering Enable";
BA_ "GenSigSendType" SG_ 2566902551 FogLightCornEna 3;
BA_ "GenSigTimeoutTime_PCM" SG_ 2566902551 FogLightCornEna 5000;
BA_ "SigType" SG_ 2566902551 FogLightCornEna 4;
BA_ "CI_ParId" SG_ 2566902551 DrlEna "I262";
BA_ "CI_SigId" SG_ 2566902551 DrlEna 6274;
BA_ "CI_SigName" SG_ 2566902551 DrlEna "Daylight Running Lights Enable";
BA_ "GenSigSendType" SG_ 2566902551 DrlEna 3;
BA_ "GenSigTimeoutTime_PCM" SG_ 2566902551 DrlEna 5000;
BA_ "SigType" SG_ 2566902551 DrlEna 4;
BA_ "CI_ParId" SG_ 2566902551 AhbcEna "I397";
BA_ "CI_SigId" SG_ 2566902551 AhbcEna 6271;
BA_ "CI_SigName" SG_ 2566902551 AhbcEna "Automatic High Beam Control Enable";
BA_ "GenSigSendType" SG_ 2566902551 AhbcEna 3;
BA_ "GenSigTimeoutTime_PCM" SG_ 2566902551 AhbcEna 5000;
BA_ "SigType" SG_ 2566902551 AhbcEna 4;
BA_ "CI_ParId" SG_ 2566902602 AhbcEna_FFD34A "I397";
BA_ "CI_SigId" SG_ 2566902602 AhbcEna_FFD34A 44496;
BA_ "CI_SigName" SG_ 2566902602 AhbcEna_FFD34A "Automatic High Beam Control Enable";
BA_ "SigType" SG_ 2566902602 AhbcEna_FFD34A 4;
BA_ "CI_ParId" SG_ 2583642355 Pbmu1Stbat "ID2009";
BA_ "CI_SigId" SG_ 2583642355 Pbmu1Stbat 39738;
BA_ "CI_SigName" SG_ 2583642355 Pbmu1Stbat "PBMU1StBat";
BA_ "GenSigTimeoutTime_PCM" SG_ 2583642355 Pbmu1Stbat 5000;
BA_ "CI_ParId" SG_ 2583642355 Pbmu1Ucellmaxnr "ID2012";
BA_ "CI_SigId" SG_ 2583642355 Pbmu1Ucellmaxnr 39737;
BA_ "CI_SigName" SG_ 2583642355 Pbmu1Ucellmaxnr "PBMU1UCellMaxNr";
BA_ "GenSigTimeoutTime_PCM" SG_ 2583642355 Pbmu1Ucellmaxnr 5000;
BA_ "CI_ParId" SG_ 2583642355 Pbmu1Ucellminnr "ID2011";
BA_ "CI_SigId" SG_ 2583642355 Pbmu1Ucellminnr 39736;
BA_ "CI_SigName" SG_ 2583642355 Pbmu1Ucellminnr "PBMU1UCellMinNr";
BA_ "GenSigTimeoutTime_PCM" SG_ 2583642355 Pbmu1Ucellminnr 5000;
BA_ "CI_ParId" SG_ 2583642355 Pbmu1Hvp "ID2010";
BA_ "CI_SigId" SG_ 2583642355 Pbmu1Hvp 39735;
BA_ "CI_SigName" SG_ 2583642355 Pbmu1Hvp "PBMU1HVP";
BA_ "GenSigTimeoutTime_PCM" SG_ 2583642355 Pbmu1Hvp 5000;
BA_ "SigType" SG_ 2583642355 Pbmu1Hvp 1;
BA_ "CI_ParId" SG_ 2583642355 Pbmu1I "ID2008";
BA_ "CI_SigId" SG_ 2583642355 Pbmu1I 39734;
BA_ "CI_SigName" SG_ 2583642355 Pbmu1I "PBMU1I";
BA_ "GenSigTimeoutTime_PCM" SG_ 2583642355 Pbmu1I 5000;
BA_ "SigType" SG_ 2583642355 Pbmu1I 1;
BA_ "CI_ParId" SG_ 2583642611 Pbmu2Stbat "ID2014";
BA_ "CI_SigId" SG_ 2583642611 Pbmu2Stbat 39744;
BA_ "CI_SigName" SG_ 2583642611 Pbmu2Stbat "PBMU2StBat";
BA_ "GenSigTimeoutTime_PCM" SG_ 2583642611 Pbmu2Stbat 5000;
BA_ "CI_ParId" SG_ 2583642611 Pbmu2Ucellmaxnr "ID2017";
BA_ "CI_SigId" SG_ 2583642611 Pbmu2Ucellmaxnr 39743;
BA_ "CI_SigName" SG_ 2583642611 Pbmu2Ucellmaxnr "PBMU2UCellMaxNr";
BA_ "GenSigTimeoutTime_PCM" SG_ 2583642611 Pbmu2Ucellmaxnr 5000;
BA_ "CI_ParId" SG_ 2583642611 Pbmu2Ucellminnr "ID2016";
BA_ "CI_SigId" SG_ 2583642611 Pbmu2Ucellminnr 39742;
BA_ "CI_SigName" SG_ 2583642611 Pbmu2Ucellminnr "PBMU2UCellMinNr";
BA_ "GenSigTimeoutTime_PCM" SG_ 2583642611 Pbmu2Ucellminnr 5000;
BA_ "CI_ParId" SG_ 2583642611 Pbmu2Hvp "ID2015";
BA_ "CI_SigId" SG_ 2583642611 Pbmu2Hvp 39741;
BA_ "CI_SigName" SG_ 2583642611 Pbmu2Hvp "PBMU2HVP";
BA_ "GenSigTimeoutTime_PCM" SG_ 2583642611 Pbmu2Hvp 5000;
BA_ "SigType" SG_ 2583642611 Pbmu2Hvp 1;
BA_ "CI_ParId" SG_ 2583642611 Pbmu2I "ID2013";
BA_ "CI_SigId" SG_ 2583642611 Pbmu2I 39740;
BA_ "CI_SigName" SG_ 2583642611 Pbmu2I "PBMU2I";
BA_ "GenSigTimeoutTime_PCM" SG_ 2583642611 Pbmu2I 5000;
BA_ "SigType" SG_ 2583642611 Pbmu2I 1;
BA_ "CI_ParId" SG_ 2583642867 Pbmu3Stbat "ID2019";
BA_ "CI_SigId" SG_ 2583642867 Pbmu3Stbat 39750;
BA_ "CI_SigName" SG_ 2583642867 Pbmu3Stbat "PBMU3StBat";
BA_ "GenSigTimeoutTime_PCM" SG_ 2583642867 Pbmu3Stbat 5000;
BA_ "CI_ParId" SG_ 2583642867 Pbmu3Ucellmaxnr "ID2022";
BA_ "CI_SigId" SG_ 2583642867 Pbmu3Ucellmaxnr 39749;
BA_ "CI_SigName" SG_ 2583642867 Pbmu3Ucellmaxnr "PBMU3UCellMaxNr";
BA_ "GenSigTimeoutTime_PCM" SG_ 2583642867 Pbmu3Ucellmaxnr 5000;
BA_ "CI_ParId" SG_ 2583642867 Pbmu3Ucellminnr "ID2021";
BA_ "CI_SigId" SG_ 2583642867 Pbmu3Ucellminnr 39748;
BA_ "CI_SigName" SG_ 2583642867 Pbmu3Ucellminnr "PBMU3UCellMinNr";
BA_ "GenSigTimeoutTime_PCM" SG_ 2583642867 Pbmu3Ucellminnr 5000;
BA_ "CI_ParId" SG_ 2583642867 Pbmu3Hvp "ID2020";
BA_ "CI_SigId" SG_ 2583642867 Pbmu3Hvp 39747;
BA_ "CI_SigName" SG_ 2583642867 Pbmu3Hvp "PBMU3HVP";
BA_ "GenSigTimeoutTime_PCM" SG_ 2583642867 Pbmu3Hvp 5000;
BA_ "SigType" SG_ 2583642867 Pbmu3Hvp 1;
BA_ "CI_ParId" SG_ 2583642867 Pbmu3I "ID2018";
BA_ "CI_SigId" SG_ 2583642867 Pbmu3I 39746;
BA_ "CI_SigName" SG_ 2583642867 Pbmu3I "PBMU3I";
BA_ "GenSigTimeoutTime_PCM" SG_ 2583642867 Pbmu3I 5000;
BA_ "SigType" SG_ 2583642867 Pbmu3I 1;
BA_ "CI_ParId" SG_ 2583640051 Pbmu4Stbat "ID2096";
BA_ "CI_SigId" SG_ 2583640051 Pbmu4Stbat 40682;
BA_ "CI_SigName" SG_ 2583640051 Pbmu4Stbat "PBMU4StBat";
BA_ "GenSigTimeoutTime_PCM" SG_ 2583640051 Pbmu4Stbat 5000;
BA_ "CI_ParId" SG_ 2583640051 Pbmu4Ucellmaxnr "ID2099";
BA_ "CI_SigId" SG_ 2583640051 Pbmu4Ucellmaxnr 40681;
BA_ "CI_SigName" SG_ 2583640051 Pbmu4Ucellmaxnr "PBMU4UCellMaxNr";
BA_ "GenSigTimeoutTime_PCM" SG_ 2583640051 Pbmu4Ucellmaxnr 5000;
BA_ "CI_ParId" SG_ 2583640051 Pbmu4Ucellminnr "ID2098";
BA_ "CI_SigId" SG_ 2583640051 Pbmu4Ucellminnr 40680;
BA_ "CI_SigName" SG_ 2583640051 Pbmu4Ucellminnr "PBMU4UCellMinNr";
BA_ "GenSigTimeoutTime_PCM" SG_ 2583640051 Pbmu4Ucellminnr 5000;
BA_ "CI_ParId" SG_ 2583640051 Pbmu4Hvp "ID2097";
BA_ "CI_SigId" SG_ 2583640051 Pbmu4Hvp 40679;
BA_ "CI_SigName" SG_ 2583640051 Pbmu4Hvp "PBMU4HVP";
BA_ "GenSigTimeoutTime_PCM" SG_ 2583640051 Pbmu4Hvp 5000;
BA_ "SigType" SG_ 2583640051 Pbmu4Hvp 1;
BA_ "CI_ParId" SG_ 2583640051 Pbmu4I "ID2095";
BA_ "CI_SigId" SG_ 2583640051 Pbmu4I 40678;
BA_ "CI_SigName" SG_ 2583640051 Pbmu4I "PBMU4I";
BA_ "GenSigTimeoutTime_PCM" SG_ 2583640051 Pbmu4I 5000;
BA_ "SigType" SG_ 2583640051 Pbmu4I 1;
BA_ "CI_ParId" SG_ 2583640307 Pbmu5Stbat "ID2101";
BA_ "CI_SigId" SG_ 2583640307 Pbmu5Stbat 40688;
BA_ "CI_SigName" SG_ 2583640307 Pbmu5Stbat "PBMU5StBat";
BA_ "GenSigTimeoutTime_PCM" SG_ 2583640307 Pbmu5Stbat 5000;
BA_ "CI_ParId" SG_ 2583640307 Pbmu5Ucellmaxnr "ID2104";
BA_ "CI_SigId" SG_ 2583640307 Pbmu5Ucellmaxnr 40687;
BA_ "CI_SigName" SG_ 2583640307 Pbmu5Ucellmaxnr "PBMU5UCellMaxNr";
BA_ "GenSigTimeoutTime_PCM" SG_ 2583640307 Pbmu5Ucellmaxnr 5000;
BA_ "CI_ParId" SG_ 2583640307 Pbmu5Ucellminnr "ID2103";
BA_ "CI_SigId" SG_ 2583640307 Pbmu5Ucellminnr 40686;
BA_ "CI_SigName" SG_ 2583640307 Pbmu5Ucellminnr "PBMU5UCellMinNr";
BA_ "GenSigTimeoutTime_PCM" SG_ 2583640307 Pbmu5Ucellminnr 5000;
BA_ "CI_ParId" SG_ 2583640307 Pbmu5Hvp "ID2102";
BA_ "CI_SigId" SG_ 2583640307 Pbmu5Hvp 40685;
BA_ "CI_SigName" SG_ 2583640307 Pbmu5Hvp "PBMU5HVP";
BA_ "GenSigTimeoutTime_PCM" SG_ 2583640307 Pbmu5Hvp 5000;
BA_ "SigType" SG_ 2583640307 Pbmu5Hvp 1;
BA_ "CI_ParId" SG_ 2583640307 Pbmu5I "ID2100";
BA_ "CI_SigId" SG_ 2583640307 Pbmu5I 40684;
BA_ "CI_SigName" SG_ 2583640307 Pbmu5I "PBMU5I";
BA_ "GenSigTimeoutTime_PCM" SG_ 2583640307 Pbmu5I 5000;
BA_ "SigType" SG_ 2583640307 Pbmu5I 1;
BA_ "CI_ParId" SG_ 2583639312 Crc8 "ID2118";
BA_ "CI_SigId" SG_ 2583639312 Crc8 41974;
BA_ "CI_SigName" SG_ 2583639312 Crc8 "CRC-8 ";
BA_ "GenSigTimeoutTime_PCM" SG_ 2583639312 Crc8 500;
BA_ "CI_ParId" SG_ 2583639312 MsgCnt_FF3510 "4206";
BA_ "CI_SigId" SG_ 2583639312 MsgCnt_FF3510 41973;
BA_ "CI_SigName" SG_ 2583639312 MsgCnt_FF3510 "Message Counter";
BA_ "GenSigTimeoutTime_PCM" SG_ 2583639312 MsgCnt_FF3510 500;
BA_ "SPN" SG_ 2583639312 MsgCnt_FF3510 4206;
BA_ "CI_ParId" SG_ 2583639312 DirCtrlSig "ID2386";
BA_ "CI_SigId" SG_ 2583639312 DirCtrlSig 43777;
BA_ "CI_SigName" SG_ 2583639312 DirCtrlSig "Direction Control Signal";
BA_ "GenSigTimeoutTime_PCM" SG_ 2583639312 DirCtrlSig 500;
BA_ "SigType" SG_ 2583639312 DirCtrlSig 4;
BA_ "CI_ParId" SG_ 2583639312 InternHvIntLckSts "ID2158";
BA_ "CI_SigId" SG_ 2583639312 InternHvIntLckSts 41972;
BA_ "CI_SigName" SG_ 2583639312 InternHvIntLckSts "Internal HV Interlock Status";
BA_ "GenSigTimeoutTime_PCM" SG_ 2583639312 InternHvIntLckSts 500;
BA_ "SigType" SG_ 2583639312 InternHvIntLckSts 4;
BA_ "CI_ParId" SG_ 2583639312 ExtdeviceEPtoSwOff "ID2116";
BA_ "CI_SigId" SG_ 2583639312 ExtdeviceEPtoSwOff 41094;
BA_ "CI_SigName" SG_ 2583639312 ExtdeviceEPtoSwOff "ExtDevice E-PTO switch off";
BA_ "GenSigTimeoutTime_PCM" SG_ 2583639312 ExtdeviceEPtoSwOff 500;
BA_ "SigType" SG_ 2583639312 ExtdeviceEPtoSwOff 4;
BA_ "CI_ParId" SG_ 2583639312 ConnEngReq "ID2087";
BA_ "CI_SigId" SG_ 2583639312 ConnEngReq 41093;
BA_ "CI_SigName" SG_ 2583639312 ConnEngReq "Connection engagement Request";
BA_ "GenSigTimeoutTime_PCM" SG_ 2583639312 ConnEngReq 500;
BA_ "SigType" SG_ 2583639312 ConnEngReq 4;
BA_ "CI_ParId" SG_ 2583639312 SpeedSetpReq "ID2088";
BA_ "CI_SigId" SG_ 2583639312 SpeedSetpReq 41092;
BA_ "CI_SigName" SG_ 2583639312 SpeedSetpReq "Speed Setpoint Request";
BA_ "GenSigTimeoutTime_PCM" SG_ 2583639312 SpeedSetpReq 500;
BA_ "CI_ParId" SG_ 2583639370 ExtdeviceEPtoSwOff_FF354A "ID2116";
BA_ "CI_SigId" SG_ 2583639370 ExtdeviceEPtoSwOff_FF354A 41107;
BA_ "CI_SigName" SG_ 2583639370 ExtdeviceEPtoSwOff_FF354A "ExtDevice E-PTO switch off";
BA_ "GenSigTimeoutTime_SGW" SG_ 2583639370 ExtdeviceEPtoSwOff_FF354A 500;
BA_ "SigType" SG_ 2583639370 ExtdeviceEPtoSwOff_FF354A 4;
BA_ "CI_ParId" SG_ 2583636594 BbPwrReq "ID2531";
BA_ "CI_SigId" SG_ 2583636594 BbPwrReq 44770;
BA_ "CI_SigName" SG_ 2583636594 BbPwrReq "Body Builder Power Request";
BA_ "GenSigTimeoutTime_PCM" SG_ 2583636594 BbPwrReq 5000;
BA_ "SigType" SG_ 2583636594 BbPwrReq 4;
BA_ "CI_ParId" SG_ 2583636594 BsisBbInhReq "ID2515";
BA_ "CI_SigId" SG_ 2583636594 BsisBbInhReq 44748;
BA_ "CI_SigName" SG_ 2583636594 BsisBbInhReq "BSIS BB Inhibition Request";
BA_ "GenSigTimeoutTime_PCM" SG_ 2583636594 BsisBbInhReq 5000;
BA_ "SigType" SG_ 2583636594 BsisBbInhReq 4;
BA_ "CI_ParId" SG_ 2583636594 MoisBbInhReq "ID2514";
BA_ "CI_SigId" SG_ 2583636594 MoisBbInhReq 44747;
BA_ "CI_SigName" SG_ 2583636594 MoisBbInhReq "MOIS BB Inhibition Request";
BA_ "GenSigTimeoutTime_PCM" SG_ 2583636594 MoisBbInhReq 5000;
BA_ "SigType" SG_ 2583636594 MoisBbInhReq 4;
BA_ "CI_ParId" SG_ 2583636594 AebsBbInhReq "ID2513";
BA_ "CI_SigId" SG_ 2583636594 AebsBbInhReq 44746;
BA_ "CI_SigName" SG_ 2583636594 AebsBbInhReq "AEBS BB Inhibition Request";
BA_ "GenSigTimeoutTime_PCM" SG_ 2583636594 AebsBbInhReq 5000;
BA_ "SigType" SG_ 2583636594 AebsBbInhReq 4;
BA_ "CI_ParId" SG_ 2566894625 RearCeilLight "ID2507";
BA_ "CI_SigId" SG_ 2566894625 RearCeilLight 44688;
BA_ "CI_SigName" SG_ 2566894625 RearCeilLight "Rear Ceiling Light";
BA_ "GenSigTimeoutTime_PCM" SG_ 2566894625 RearCeilLight 500;
BA_ "SigType" SG_ 2566894625 RearCeilLight 4;
BA_ "CI_ParId" SG_ 2566894625 CentCeilLight "ID2506";
BA_ "CI_SigId" SG_ 2566894625 CentCeilLight 44687;
BA_ "CI_SigName" SG_ 2566894625 CentCeilLight "Central Ceiling Light";
BA_ "GenSigTimeoutTime_PCM" SG_ 2566894625 CentCeilLight 500;
BA_ "SigType" SG_ 2566894625 CentCeilLight 4;
BA_ "CI_ParId" SG_ 2566894625 LatRightCeilLight "ID2505";
BA_ "CI_SigId" SG_ 2566894625 LatRightCeilLight 44686;
BA_ "CI_SigName" SG_ 2566894625 LatRightCeilLight "Lateral Right Ceiling Light";
BA_ "GenSigTimeoutTime_PCM" SG_ 2566894625 LatRightCeilLight 500;
BA_ "SigType" SG_ 2566894625 LatRightCeilLight 4;
BA_ "CI_ParId" SG_ 2566894625 LatLeftCeilLight "ID2504";
BA_ "CI_SigId" SG_ 2566894625 LatLeftCeilLight 44685;
BA_ "CI_SigName" SG_ 2566894625 LatLeftCeilLight "Lateral Left Ceiling Light";
BA_ "GenSigTimeoutTime_PCM" SG_ 2566894625 LatLeftCeilLight 500;
BA_ "SigType" SG_ 2566894625 LatLeftCeilLight 4;
BA_ "CI_ParId" SG_ 2566894625 BcmDowFail "ID2435";
BA_ "CI_SigId" SG_ 2566894625 BcmDowFail 44430;
BA_ "CI_SigName" SG_ 2566894625 BcmDowFail "BCM DOW Failure Status";
BA_ "GenSigTimeoutTime_PCM" SG_ 2566894625 BcmDowFail 500;
BA_ "SigType" SG_ 2566894625 BcmDowFail 4;
BA_ "CI_ParId" SG_ 2566894625 BcmRctFail "ID2434";
BA_ "CI_SigId" SG_ 2566894625 BcmRctFail 44429;
BA_ "CI_SigName" SG_ 2566894625 BcmRctFail "BCM RCT Failure Status";
BA_ "GenSigTimeoutTime_PCM" SG_ 2566894625 BcmRctFail 500;
BA_ "SigType" SG_ 2566894625 BcmRctFail 4;
BA_ "CI_ParId" SG_ 2566894625 BcmBsisFail "ID2433";
BA_ "CI_SigId" SG_ 2566894625 BcmBsisFail 44428;
BA_ "CI_SigName" SG_ 2566894625 BcmBsisFail "BCM BSIS Failure Status";
BA_ "GenSigTimeoutTime_PCM" SG_ 2566894625 BcmBsisFail 500;
BA_ "SigType" SG_ 2566894625 BcmBsisFail 4;
BA_ "CI_ParId" SG_ 2566894625 BcmBsFail "ID2432";
BA_ "CI_SigId" SG_ 2566894625 BcmBsFail 44427;
BA_ "CI_SigName" SG_ 2566894625 BcmBsFail "BCM BS Failure Status";
BA_ "GenSigTimeoutTime_PCM" SG_ 2566894625 BcmBsFail 500;
BA_ "SigType" SG_ 2566894625 BcmBsFail 4;
BA_ "CI_ParId" SG_ 2566894625 FrontCeilLight "ID2503";
BA_ "CI_SigId" SG_ 2566894625 FrontCeilLight 44684;
BA_ "CI_SigName" SG_ 2566894625 FrontCeilLight "Front Ceiling Light";
BA_ "GenSigTimeoutTime_PCM" SG_ 2566894625 FrontCeilLight 500;
BA_ "SigType" SG_ 2566894625 FrontCeilLight 4;
BA_ "CI_ParId" SG_ 2566894625 RearDiffLckCtrlFail "ID2440";
BA_ "CI_SigId" SG_ 2566894625 RearDiffLckCtrlFail 44461;
BA_ "CI_SigName" SG_ 2566894625 RearDiffLckCtrlFail "Rear Differential Lock Control Fail";
BA_ "GenSigTimeoutTime_PCM" SG_ 2566894625 RearDiffLckCtrlFail 500;
BA_ "SigType" SG_ 2566894625 RearDiffLckCtrlFail 4;
BA_ "CI_ParId" SG_ 2566894625 VehBatVLowLampSts "ID2429";
BA_ "CI_SigId" SG_ 2566894625 VehBatVLowLampSts 44224;
BA_ "CI_SigName" SG_ 2566894625 VehBatVLowLampSts "Vehicle Battery Voltage Low Lamp Status";
BA_ "GenSigTimeoutTime_PCM" SG_ 2566894625 VehBatVLowLampSts 500;
BA_ "SigType" SG_ 2566894625 VehBatVLowLampSts 4;
BA_ "CI_ParId" SG_ 2566894625 BrkSw_FFB421 "597";
BA_ "CI_SigId" SG_ 2566894625 BrkSw_FFB421 44223;
BA_ "CI_SigName" SG_ 2566894625 BrkSw_FFB421 "Brake Switch";
BA_ "GenSigTimeoutTime_PCM" SG_ 2566894625 BrkSw_FFB421 500;
BA_ "SPN" SG_ 2566894625 BrkSw_FFB421 597;
BA_ "SigType" SG_ 2566894625 BrkSw_FFB421 4;
BA_ "CI_ParId" SG_ 2566894625 RearDiffLckSts "ID2439";
BA_ "CI_SigId" SG_ 2566894625 RearDiffLckSts 43788;
BA_ "CI_SigName" SG_ 2566894625 RearDiffLckSts "Rear Differential Lock Status";
BA_ "GenSigTimeoutTime_PCM" SG_ 2566894625 RearDiffLckSts 500;
BA_ "SigType" SG_ 2566894625 RearDiffLckSts 4;
BA_ "CI_ParId" SG_ 2566894625 EngWaterLev_FFB421 "ID0250";
BA_ "CI_SigId" SG_ 2566894625 EngWaterLev_FFB421 43074;
BA_ "CI_SigName" SG_ 2566894625 EngWaterLev_FFB421 "Engine Water Level";
BA_ "GenSigTimeoutTime_PCM" SG_ 2566894625 EngWaterLev_FFB421 500;
BA_ "SigType" SG_ 2566894625 EngWaterLev_FFB421 4;
BA_ "CI_ParId" SG_ 2566894625 HeadbeamAdjPos "ID2327";
BA_ "CI_SigId" SG_ 2566894625 HeadbeamAdjPos 42799;
BA_ "CI_SigName" SG_ 2566894625 HeadbeamAdjPos "Headbeam Adjustment Position";
BA_ "GenSigTimeoutTime_PCM" SG_ 2566894625 HeadbeamAdjPos 500;
BA_ "CI_ParId" SG_ 2566894625 DieselFiltBlk "IS144";
BA_ "CI_SigId" SG_ 2566894625 DieselFiltBlk 42610;
BA_ "CI_SigName" SG_ 2566894625 DieselFiltBlk "Diesel Filter Blocked";
BA_ "GenSigTimeoutTime_PCM" SG_ 2566894625 DieselFiltBlk 500;
BA_ "CI_ParId" SG_ 2566894625 AirFiltBlk "IS191";
BA_ "CI_SigId" SG_ 2566894625 AirFiltBlk 42609;
BA_ "CI_SigName" SG_ 2566894625 AirFiltBlk "Air Filter Blocked";
BA_ "GenSigTimeoutTime_PCM" SG_ 2566894625 AirFiltBlk 500;
BA_ "CI_ParId" SG_ 2566894625 PtcFail "ID2260";
BA_ "CI_SigId" SG_ 2566894625 PtcFail 42608;
BA_ "CI_SigName" SG_ 2566894625 PtcFail "PTC Fail Status";
BA_ "GenSigTimeoutTime_PCM" SG_ 2566894625 PtcFail 500;
BA_ "CI_ParId" SG_ 2566894625 PtcSts "ID2261";
BA_ "CI_SigId" SG_ 2566894625 PtcSts 42607;
BA_ "CI_SigName" SG_ 2566894625 PtcSts "PTC Status";
BA_ "GenSigTimeoutTime_PCM" SG_ 2566894625 PtcSts 500;
BA_ "SigType" SG_ 2566894625 PtcSts 4;
BA_ "CI_ParId" SG_ 2566894625 CondNeededForEnaAutoStop "ID2257";
BA_ "CI_SigId" SG_ 2566894625 CondNeededForEnaAutoStop 42606;
BA_ "CI_SigName" SG_ 2566894625 CondNeededForEnaAutoStop "Conditions Needed for Enabling Automatic Stop";
BA_ "GenSigTimeoutTime_PCM" SG_ 2566894625 CondNeededForEnaAutoStop 500;
BA_ "CI_ParId" SG_ 2566894625 CrkPossInAutoStop "ID2256";
BA_ "CI_SigId" SG_ 2566894625 CrkPossInAutoStop 42605;
BA_ "CI_SigName" SG_ 2566894625 CrkPossInAutoStop "Crank Possible in Automatic Stop";
BA_ "GenSigTimeoutTime_PCM" SG_ 2566894625 CrkPossInAutoStop 500;
BA_ "CI_ParId" SG_ 2566894625 CrkModeAllwInAutoStop "ID2255";
BA_ "CI_SigId" SG_ 2566894625 CrkModeAllwInAutoStop 42604;
BA_ "CI_SigName" SG_ 2566894625 CrkModeAllwInAutoStop "Cranking Mode Allowed in Automatic Stop";
BA_ "GenSigTimeoutTime_PCM" SG_ 2566894625 CrkModeAllwInAutoStop 500;
BA_ "CI_ParId" SG_ 2566894625 EassMngReq "ID2258";
BA_ "CI_SigId" SG_ 2566894625 EassMngReq 42603;
BA_ "CI_SigName" SG_ 2566894625 EassMngReq "Stop and Start Management Request";
BA_ "GenSigTimeoutTime_PCM" SG_ 2566894625 EassMngReq 500;
BA_ "CI_ParId" SG_ 2566894625 EassSafeModeIndSts "ID2259";
BA_ "CI_SigId" SG_ 2566894625 EassSafeModeIndSts 42400;
BA_ "CI_SigName" SG_ 2566894625 EassSafeModeIndSts "Stop and Start Safe Mode Indication Status";
BA_ "GenSigTimeoutTime_PCM" SG_ 2566894625 EassSafeModeIndSts 500;
BA_ "SigType" SG_ 2566894625 EassSafeModeIndSts 4;
BA_ "CI_ParId" SG_ 2566894625 RearHeatWndSts "ID2254";
BA_ "CI_SigId" SG_ 2566894625 RearHeatWndSts 42399;
BA_ "CI_SigName" SG_ 2566894625 RearHeatWndSts "Rear Heated Window Status";
BA_ "GenSigTimeoutTime_PCM" SG_ 2566894625 RearHeatWndSts 500;
BA_ "CI_ParId" SG_ 2566894625 DrivStyleSts "ID2253";
BA_ "CI_SigId" SG_ 2566894625 DrivStyleSts 42398;
BA_ "CI_SigName" SG_ 2566894625 DrivStyleSts "Drive Style Status";
BA_ "GenSigTimeoutTime_PCM" SG_ 2566894625 DrivStyleSts 500;
BA_ "CI_ParId" SG_ 2566894625 ComprAcReqSts "ID2252";
BA_ "CI_SigId" SG_ 2566894625 ComprAcReqSts 42397;
BA_ "CI_SigName" SG_ 2566894625 ComprAcReqSts "Compressor AC Request Status";
BA_ "GenSigTimeoutTime_PCM" SG_ 2566894625 ComprAcReqSts 500;
BA_ "SigType" SG_ 2566894625 ComprAcReqSts 4;
BA_ "CI_ParId" SG_ 2566894625 GearModesReq "ID2529";
BA_ "CI_SigId" SG_ 2566894625 GearModesReq 44768;
BA_ "CI_SigName" SG_ 2566894625 GearModesReq "Gear Modes Request";
BA_ "GenSigTimeoutTime_PCM" SG_ 2566894625 GearModesReq 500;
BA_ "SigType" SG_ 2566894625 GearModesReq 4;
BA_ "CI_ParId" SG_ 2566894625 EcoLckEng "ID2528";
BA_ "CI_SigId" SG_ 2566894625 EcoLckEng 44767;
BA_ "CI_SigName" SG_ 2566894625 EcoLckEng "Eco Lock Engine";
BA_ "GenSigTimeoutTime_PCM" SG_ 2566894625 EcoLckEng 500;
BA_ "SigType" SG_ 2566894625 EcoLckEng 4;
BA_ "CI_ParId" SG_ 2566888481 AmbBrt "ID2560";
BA_ "CI_SigId" SG_ 2566888481 AmbBrt 45669;
BA_ "CI_SigName" SG_ 2566888481 AmbBrt "Ambient Brightness";
BA_ "GenSigTimeoutTime_PCM" SG_ 2566888481 AmbBrt 5000;
BA_ "SigType" SG_ 2566888481 AmbBrt 1;
BA_ "CI_ParId" SG_ 2566888481 AirFilt "ID2549";
BA_ "CI_SigId" SG_ 2566888481 AirFilt 44890;
BA_ "CI_SigName" SG_ 2566888481 AirFilt "Air Filter ";
BA_ "GenSigTimeoutTime_PCM" SG_ 2566888481 AirFilt 5000;
BA_ "SigType" SG_ 2566888481 AirFilt 1;
BA_ "CI_ParId" SG_ 2566888481 FuelFilt "ID2548";
BA_ "CI_SigId" SG_ 2566888481 FuelFilt 44889;
BA_ "CI_SigName" SG_ 2566888481 FuelFilt "Fuel Filter ";
BA_ "GenSigTimeoutTime_PCM" SG_ 2566888481 FuelFilt 5000;
BA_ "SigType" SG_ 2566888481 FuelFilt 1;
BA_ "CI_ParId" SG_ 2566888481 LightSwReq "ID2559";
BA_ "CI_SigId" SG_ 2566888481 LightSwReq 45668;
BA_ "CI_SigName" SG_ 2566888481 LightSwReq "Light Switch Request";
BA_ "GenSigTimeoutTime_PCM" SG_ 2566888481 LightSwReq 5000;
BA_ "SigType" SG_ 2566888481 LightSwReq 4;
BA_ "CI_ParId" SG_ 2583650855 HighVBatNomChgV "B071";
BA_ "CI_SigId" SG_ 2583650855 HighVBatNomChgV 39644;
BA_ "CI_SigName" SG_ 2583650855 HighVBatNomChgV "High Voltage Battery Nominal Charging Voltage";
BA_ "GenSigTimeoutTime_PCM" SG_ 2583650855 HighVBatNomChgV 500;
BA_ "SigType" SG_ 2583650855 HighVBatNomChgV 2;
BA_ "CI_ParId" SG_ 2583650855 HighVBatVmax "B070";
BA_ "CI_SigId" SG_ 2583650855 HighVBatVmax 39643;
BA_ "CI_SigName" SG_ 2583650855 HighVBatVmax "High Voltage Battery Maximum Voltage";
BA_ "GenSigTimeoutTime_PCM" SG_ 2583650855 HighVBatVmax 500;
BA_ "SigType" SG_ 2583650855 HighVBatVmax 2;
BA_ "CI_ParId" SG_ 2583650855 HighVBatSoc "B069";
BA_ "CI_SigId" SG_ 2583650855 HighVBatSoc 39642;
BA_ "CI_SigName" SG_ 2583650855 HighVBatSoc "High Voltage Battery State of Charge";
BA_ "GenSigTimeoutTime_PCM" SG_ 2583650855 HighVBatSoc 500;
BA_ "SigType" SG_ 2583650855 HighVBatSoc 2;
BA_ "CI_ParId" SG_ 2583650855 HighVBatTotCap "B068";
BA_ "CI_SigId" SG_ 2583650855 HighVBatTotCap 39641;
BA_ "CI_SigName" SG_ 2583650855 HighVBatTotCap "High Voltage Battery Total Capacity";
BA_ "GenSigTimeoutTime_PCM" SG_ 2583650855 HighVBatTotCap 500;
BA_ "SigType" SG_ 2583650855 HighVBatTotCap 2;
BA_ "CI_ParId" SG_ 2583651111 HighVBatCurReqToChg "B074";
BA_ "CI_SigId" SG_ 2583651111 HighVBatCurReqToChg 39648;
BA_ "CI_SigName" SG_ 2583651111 HighVBatCurReqToChg "High Voltage Battery Current Request to Charger";
BA_ "GenSigTimeoutTime_PCM" SG_ 2583651111 HighVBatCurReqToChg 500;
BA_ "SigType" SG_ 2583651111 HighVBatCurReqToChg 2;
BA_ "CI_ParId" SG_ 2583651111 HighVBatNomExtChgCur "B073";
BA_ "CI_SigId" SG_ 2583651111 HighVBatNomExtChgCur 39647;
BA_ "CI_SigName" SG_ 2583651111 HighVBatNomExtChgCur "High Voltage Battery Nominal External Charging Current";
BA_ "GenSigTimeoutTime_PCM" SG_ 2583651111 HighVBatNomExtChgCur 500;
BA_ "SigType" SG_ 2583651111 HighVBatNomExtChgCur 2;
BA_ "CI_ParId" SG_ 2583651111 HighVBatActCur "B072";
BA_ "CI_SigId" SG_ 2583651111 HighVBatActCur 39646;
BA_ "CI_SigName" SG_ 2583651111 HighVBatActCur "High Voltage Battery Actual Current";
BA_ "GenSigTimeoutTime_PCM" SG_ 2583651111 HighVBatActCur 500;
BA_ "SigType" SG_ 2583651111 HighVBatActCur 2;
BA_ "CI_ParId" SG_ 2583651367 HighVBatActVMeas "B079";
BA_ "CI_SigId" SG_ 2583651367 HighVBatActVMeas 39654;
BA_ "CI_SigName" SG_ 2583651367 HighVBatActVMeas "High Voltage Battery Actual Voltage Measured";
BA_ "GenSigTimeoutTime_PCM" SG_ 2583651367 HighVBatActVMeas 500;
BA_ "SigType" SG_ 2583651367 HighVBatActVMeas 2;
BA_ "CI_ParId" SG_ 2583651367 IsolMeasActvSts "B078";
BA_ "CI_SigId" SG_ 2583651367 IsolMeasActvSts 39653;
BA_ "CI_SigName" SG_ 2583651367 IsolMeasActvSts "Isolation Measurement Active Status";
BA_ "GenSigTimeoutTime_PCM" SG_ 2583651367 IsolMeasActvSts 500;
BA_ "CI_ParId" SG_ 2583651367 HighVBatErrSts "B077";
BA_ "CI_SigId" SG_ 2583651367 HighVBatErrSts 39652;
BA_ "CI_SigName" SG_ 2583651367 HighVBatErrSts "High Voltage Battery Error State";
BA_ "GenSigTimeoutTime_PCM" SG_ 2583651367 HighVBatErrSts 500;
BA_ "CI_ParId" SG_ 2583651367 HighVBatChgTargetReachedInd "B076";
BA_ "CI_SigId" SG_ 2583651367 HighVBatChgTargetReachedInd 39651;
BA_ "CI_SigName" SG_ 2583651367 HighVBatChgTargetReachedInd "High Voltage Battery Charge Target Reached Indication";
BA_ "GenSigTimeoutTime_PCM" SG_ 2583651367 HighVBatChgTargetReachedInd 500;
BA_ "CI_ParId" SG_ 2583637747 MaxNumOfFaultySensPerModInPack5 "ID2348";
BA_ "CI_SigId" SG_ 2583637747 MaxNumOfFaultySensPerModInPack5 43015;
BA_ "CI_SigName" SG_ 2583637747 MaxNumOfFaultySensPerModInPack5 "Max number of faulty sensors per module in pack 5";
BA_ "GenSigTimeoutTime_PCM" SG_ 2583637747 MaxNumOfFaultySensPerModInPack5 5000;
BA_ "CI_ParId" SG_ 2583637747 TotNumOfFaultySensInPack5 "ID2343";
BA_ "CI_SigId" SG_ 2583637747 TotNumOfFaultySensInPack5 43014;
BA_ "CI_SigName" SG_ 2583637747 TotNumOfFaultySensInPack5 "Total number of faulty sensors in pack 5";
BA_ "GenSigTimeoutTime_PCM" SG_ 2583637747 TotNumOfFaultySensInPack5 5000;
BA_ "CI_ParId" SG_ 2583637747 MaxNumOfFaultySensPerModInPack4 "ID2347";
BA_ "CI_SigId" SG_ 2583637747 MaxNumOfFaultySensPerModInPack4 43013;
BA_ "CI_SigName" SG_ 2583637747 MaxNumOfFaultySensPerModInPack4 "Max number of faulty sensors per module in pack 4";
BA_ "GenSigTimeoutTime_PCM" SG_ 2583637747 MaxNumOfFaultySensPerModInPack4 5000;
BA_ "CI_ParId" SG_ 2583637747 TotNumOfFaultySensInPack4 "ID2342";
BA_ "CI_SigId" SG_ 2583637747 TotNumOfFaultySensInPack4 43012;
BA_ "CI_SigName" SG_ 2583637747 TotNumOfFaultySensInPack4 "Total number of faulty sensors in pack 4";
BA_ "GenSigTimeoutTime_PCM" SG_ 2583637747 TotNumOfFaultySensInPack4 5000;
BA_ "CI_ParId" SG_ 2583637747 MaxNumOfFaultySensPerModInPack3 "ID2346";
BA_ "CI_SigId" SG_ 2583637747 MaxNumOfFaultySensPerModInPack3 43011;
BA_ "CI_SigName" SG_ 2583637747 MaxNumOfFaultySensPerModInPack3 "Max number of faulty sensors per module in pack 3";
BA_ "GenSigTimeoutTime_PCM" SG_ 2583637747 MaxNumOfFaultySensPerModInPack3 5000;
BA_ "CI_ParId" SG_ 2583637747 TotNumOfFaultySensInPack3 "ID2341";
BA_ "CI_SigId" SG_ 2583637747 TotNumOfFaultySensInPack3 43010;
BA_ "CI_SigName" SG_ 2583637747 TotNumOfFaultySensInPack3 "Total number of faulty sensors in pack 3";
BA_ "GenSigTimeoutTime_PCM" SG_ 2583637747 TotNumOfFaultySensInPack3 5000;
BA_ "CI_ParId" SG_ 2583637747 MaxNumOfFaultySensPerModInPack2 "ID2345";
BA_ "CI_SigId" SG_ 2583637747 MaxNumOfFaultySensPerModInPack2 43009;
BA_ "CI_SigName" SG_ 2583637747 MaxNumOfFaultySensPerModInPack2 "Max number of faulty sensors per module in pack 2";
BA_ "GenSigTimeoutTime_PCM" SG_ 2583637747 MaxNumOfFaultySensPerModInPack2 5000;
BA_ "CI_ParId" SG_ 2583637747 TotNumOfFaultySensInPack2 "ID2340";
BA_ "CI_SigId" SG_ 2583637747 TotNumOfFaultySensInPack2 43008;
BA_ "CI_SigName" SG_ 2583637747 TotNumOfFaultySensInPack2 "Total number of faulty sensors in pack 2";
BA_ "GenSigTimeoutTime_PCM" SG_ 2583637747 TotNumOfFaultySensInPack2 5000;
BA_ "CI_ParId" SG_ 2583637747 MaxNumOfFaultySensPerModInPack1 "ID2344";
BA_ "CI_SigId" SG_ 2583637747 MaxNumOfFaultySensPerModInPack1 43007;
BA_ "CI_SigName" SG_ 2583637747 MaxNumOfFaultySensPerModInPack1 "Max number of faulty sensors per module in pack 1";
BA_ "GenSigTimeoutTime_PCM" SG_ 2583637747 MaxNumOfFaultySensPerModInPack1 5000;
BA_ "CI_ParId" SG_ 2583637747 TotNumOfFaultySensInPack1 "ID2339";
BA_ "CI_SigId" SG_ 2583637747 TotNumOfFaultySensInPack1 43006;
BA_ "CI_SigName" SG_ 2583637747 TotNumOfFaultySensInPack1 "Total number of faulty sensors in pack 1";
BA_ "GenSigTimeoutTime_PCM" SG_ 2583637747 TotNumOfFaultySensInPack1 5000;
BA_ "CI_ParId" SG_ 2650776454 SBMS_AppLyr_BldNr "F364";
BA_ "CI_SigId" SG_ 2650776454 SBMS_AppLyr_BldNr 45435;
BA_ "CI_SigName" SG_ 2650776454 SBMS_AppLyr_BldNr "SBMS_AppLyr_BldNr";
BA_ "GenSigTimeoutTime_PCM" SG_ 2650776454 SBMS_AppLyr_BldNr 3000000;
BA_ "CI_ParId" SG_ 2650776454 SBMS_AppLyr_MinRel "F363";
BA_ "CI_SigId" SG_ 2650776454 SBMS_AppLyr_MinRel 45434;
BA_ "CI_SigName" SG_ 2650776454 SBMS_AppLyr_MinRel "SBMS_AppLyr_MinRel";
BA_ "GenSigTimeoutTime_PCM" SG_ 2650776454 SBMS_AppLyr_MinRel 3000000;
BA_ "CI_ParId" SG_ 2650776454 SBMS_AppLyr_MajRel "F362";
BA_ "CI_SigId" SG_ 2650776454 SBMS_AppLyr_MajRel 45433;
BA_ "CI_SigName" SG_ 2650776454 SBMS_AppLyr_MajRel "SBMS_AppLyr_MajRel";
BA_ "GenSigTimeoutTime_PCM" SG_ 2650776454 SBMS_AppLyr_MajRel 3000000;
BA_ "CI_ParId" SG_ 2650776454 SBMS_SftyLyr_BldNr "F361";
BA_ "CI_SigId" SG_ 2650776454 SBMS_SftyLyr_BldNr 45432;
BA_ "CI_SigName" SG_ 2650776454 SBMS_SftyLyr_BldNr "SBMS_SftyLyr_BldNr";
BA_ "GenSigTimeoutTime_PCM" SG_ 2650776454 SBMS_SftyLyr_BldNr 3000000;
BA_ "CI_ParId" SG_ 2650776454 SBMS_SftyLyr_MinRel "F360";
BA_ "CI_SigId" SG_ 2650776454 SBMS_SftyLyr_MinRel 45431;
BA_ "CI_SigName" SG_ 2650776454 SBMS_SftyLyr_MinRel "SBMS_SftyLyr_MinRel";
BA_ "GenSigTimeoutTime_PCM" SG_ 2650776454 SBMS_SftyLyr_MinRel 3000000;
BA_ "CI_ParId" SG_ 2650776454 SBMS_SftyLyr_MajRel "F359";
BA_ "CI_SigId" SG_ 2650776454 SBMS_SftyLyr_MajRel 45430;
BA_ "CI_SigName" SG_ 2650776454 SBMS_SftyLyr_MajRel "SBMS_SftyLyr_MajRel";
BA_ "GenSigTimeoutTime_PCM" SG_ 2650776454 SBMS_SftyLyr_MajRel 3000000;
BA_ "CI_ParId" SG_ 2650776455 SBMS_AppLyr_BldNr_FFA387 "F364";
BA_ "CI_SigId" SG_ 2650776455 SBMS_AppLyr_BldNr_FFA387 45441;
BA_ "CI_SigName" SG_ 2650776455 SBMS_AppLyr_BldNr_FFA387 "SBMS_AppLyr_BldNr";
BA_ "GenSigTimeoutTime_PCM" SG_ 2650776455 SBMS_AppLyr_BldNr_FFA387 3000000;
BA_ "CI_ParId" SG_ 2650776455 SBMS_AppLyr_MinRel_FFA387 "F363";
BA_ "CI_SigId" SG_ 2650776455 SBMS_AppLyr_MinRel_FFA387 45440;
BA_ "CI_SigName" SG_ 2650776455 SBMS_AppLyr_MinRel_FFA387 "SBMS_AppLyr_MinRel";
BA_ "GenSigTimeoutTime_PCM" SG_ 2650776455 SBMS_AppLyr_MinRel_FFA387 3000000;
BA_ "CI_ParId" SG_ 2650776455 SBMS_AppLyr_MajRel_FFA387 "F362";
BA_ "CI_SigId" SG_ 2650776455 SBMS_AppLyr_MajRel_FFA387 45439;
BA_ "CI_SigName" SG_ 2650776455 SBMS_AppLyr_MajRel_FFA387 "SBMS_AppLyr_MajRel";
BA_ "GenSigTimeoutTime_PCM" SG_ 2650776455 SBMS_AppLyr_MajRel_FFA387 3000000;
BA_ "CI_ParId" SG_ 2650776455 SBMS_SftyLyr_BldNr_FFA387 "F361";
BA_ "CI_SigId" SG_ 2650776455 SBMS_SftyLyr_BldNr_FFA387 45438;
BA_ "CI_SigName" SG_ 2650776455 SBMS_SftyLyr_BldNr_FFA387 "SBMS_SftyLyr_BldNr";
BA_ "GenSigTimeoutTime_PCM" SG_ 2650776455 SBMS_SftyLyr_BldNr_FFA387 3000000;
BA_ "CI_ParId" SG_ 2650776455 SBMS_SftyLyr_MinRel_FFA387 "F360";
BA_ "CI_SigId" SG_ 2650776455 SBMS_SftyLyr_MinRel_FFA387 45437;
BA_ "CI_SigName" SG_ 2650776455 SBMS_SftyLyr_MinRel_FFA387 "SBMS_SftyLyr_MinRel";
BA_ "GenSigTimeoutTime_PCM" SG_ 2650776455 SBMS_SftyLyr_MinRel_FFA387 3000000;
BA_ "CI_ParId" SG_ 2650776455 SBMS_SftyLyr_MajRel_FFA387 "F359";
BA_ "CI_SigId" SG_ 2650776455 SBMS_SftyLyr_MajRel_FFA387 45436;
BA_ "CI_SigName" SG_ 2650776455 SBMS_SftyLyr_MajRel_FFA387 "SBMS_SftyLyr_MajRel";
BA_ "GenSigTimeoutTime_PCM" SG_ 2650776455 SBMS_SftyLyr_MajRel_FFA387 3000000;
BA_ "CI_ParId" SG_ 2650776564 SBMS_AppLyr_BldNr_FFA3F4 "F364";
BA_ "CI_SigId" SG_ 2650776564 SBMS_AppLyr_BldNr_FFA3F4 45417;
BA_ "CI_SigName" SG_ 2650776564 SBMS_AppLyr_BldNr_FFA3F4 "SBMS_AppLyr_BldNr";
BA_ "GenSigTimeoutTime_PCM" SG_ 2650776564 SBMS_AppLyr_BldNr_FFA3F4 3000000;
BA_ "CI_ParId" SG_ 2650776564 SBMS_AppLyr_MinRel_FFA3F4 "F363";
BA_ "CI_SigId" SG_ 2650776564 SBMS_AppLyr_MinRel_FFA3F4 45416;
BA_ "CI_SigName" SG_ 2650776564 SBMS_AppLyr_MinRel_FFA3F4 "SBMS_AppLyr_MinRel";
BA_ "GenSigTimeoutTime_PCM" SG_ 2650776564 SBMS_AppLyr_MinRel_FFA3F4 3000000;
BA_ "CI_ParId" SG_ 2650776564 SBMS_AppLyr_MajRel_FFA3F4 "F362";
BA_ "CI_SigId" SG_ 2650776564 SBMS_AppLyr_MajRel_FFA3F4 45415;
BA_ "CI_SigName" SG_ 2650776564 SBMS_AppLyr_MajRel_FFA3F4 "SBMS_AppLyr_MajRel";
BA_ "GenSigTimeoutTime_PCM" SG_ 2650776564 SBMS_AppLyr_MajRel_FFA3F4 3000000;
BA_ "CI_ParId" SG_ 2650776564 SBMS_SftyLyr_BldNr_FFA3F4 "F361";
BA_ "CI_SigId" SG_ 2650776564 SBMS_SftyLyr_BldNr_FFA3F4 45414;
BA_ "CI_SigName" SG_ 2650776564 SBMS_SftyLyr_BldNr_FFA3F4 "SBMS_SftyLyr_BldNr";
BA_ "GenSigTimeoutTime_PCM" SG_ 2650776564 SBMS_SftyLyr_BldNr_FFA3F4 3000000;
BA_ "CI_ParId" SG_ 2650776564 SBMS_SftyLyr_MinRel_FFA3F4 "F360";
BA_ "CI_SigId" SG_ 2650776564 SBMS_SftyLyr_MinRel_FFA3F4 45413;
BA_ "CI_SigName" SG_ 2650776564 SBMS_SftyLyr_MinRel_FFA3F4 "SBMS_SftyLyr_MinRel";
BA_ "GenSigTimeoutTime_PCM" SG_ 2650776564 SBMS_SftyLyr_MinRel_FFA3F4 3000000;
BA_ "CI_ParId" SG_ 2650776564 SBMS_SftyLyr_MajRel_FFA3F4 "F359";
BA_ "CI_SigId" SG_ 2650776564 SBMS_SftyLyr_MajRel_FFA3F4 45412;
BA_ "CI_SigName" SG_ 2650776564 SBMS_SftyLyr_MajRel_FFA3F4 "SBMS_SftyLyr_MajRel";
BA_ "GenSigTimeoutTime_PCM" SG_ 2650776564 SBMS_SftyLyr_MajRel_FFA3F4 3000000;
BA_ "CI_ParId" SG_ 2650776565 SBMS_AppLyr_BldNr_FFA3F5 "F364";
BA_ "CI_SigId" SG_ 2650776565 SBMS_AppLyr_BldNr_FFA3F5 45423;
BA_ "CI_SigName" SG_ 2650776565 SBMS_AppLyr_BldNr_FFA3F5 "SBMS_AppLyr_BldNr";
BA_ "GenSigTimeoutTime_PCM" SG_ 2650776565 SBMS_AppLyr_BldNr_FFA3F5 3000000;
BA_ "CI_ParId" SG_ 2650776565 SBMS_AppLyr_MinRel_FFA3F5 "F363";
BA_ "CI_SigId" SG_ 2650776565 SBMS_AppLyr_MinRel_FFA3F5 45422;
BA_ "CI_SigName" SG_ 2650776565 SBMS_AppLyr_MinRel_FFA3F5 "SBMS_AppLyr_MinRel";
BA_ "GenSigTimeoutTime_PCM" SG_ 2650776565 SBMS_AppLyr_MinRel_FFA3F5 3000000;
BA_ "CI_ParId" SG_ 2650776565 SBMS_AppLyr_MajRel_FFA3F5 "F362";
BA_ "CI_SigId" SG_ 2650776565 SBMS_AppLyr_MajRel_FFA3F5 45421;
BA_ "CI_SigName" SG_ 2650776565 SBMS_AppLyr_MajRel_FFA3F5 "SBMS_AppLyr_MajRel";
BA_ "GenSigTimeoutTime_PCM" SG_ 2650776565 SBMS_AppLyr_MajRel_FFA3F5 3000000;
BA_ "CI_ParId" SG_ 2650776565 SBMS_SftyLyr_BldNr_FFA3F5 "F361";
BA_ "CI_SigId" SG_ 2650776565 SBMS_SftyLyr_BldNr_FFA3F5 45420;
BA_ "CI_SigName" SG_ 2650776565 SBMS_SftyLyr_BldNr_FFA3F5 "SBMS_SftyLyr_BldNr";
BA_ "GenSigTimeoutTime_PCM" SG_ 2650776565 SBMS_SftyLyr_BldNr_FFA3F5 3000000;
BA_ "CI_ParId" SG_ 2650776565 SBMS_SftyLyr_MinRel_FFA3F5 "F360";
BA_ "CI_SigId" SG_ 2650776565 SBMS_SftyLyr_MinRel_FFA3F5 45419;
BA_ "CI_SigName" SG_ 2650776565 SBMS_SftyLyr_MinRel_FFA3F5 "SBMS_SftyLyr_MinRel";
BA_ "GenSigTimeoutTime_PCM" SG_ 2650776565 SBMS_SftyLyr_MinRel_FFA3F5 3000000;
BA_ "CI_ParId" SG_ 2650776565 SBMS_SftyLyr_MajRel_FFA3F5 "F359";
BA_ "CI_SigId" SG_ 2650776565 SBMS_SftyLyr_MajRel_FFA3F5 45418;
BA_ "CI_SigName" SG_ 2650776565 SBMS_SftyLyr_MajRel_FFA3F5 "SBMS_SftyLyr_MajRel";
BA_ "GenSigTimeoutTime_PCM" SG_ 2650776565 SBMS_SftyLyr_MajRel_FFA3F5 3000000;
BA_ "CI_ParId" SG_ 2650776566 SBMS_AppLyr_BldNr_FFA3F6 "F364";
BA_ "CI_SigId" SG_ 2650776566 SBMS_AppLyr_BldNr_FFA3F6 45429;
BA_ "CI_SigName" SG_ 2650776566 SBMS_AppLyr_BldNr_FFA3F6 "SBMS_AppLyr_BldNr";
BA_ "GenSigTimeoutTime_PCM" SG_ 2650776566 SBMS_AppLyr_BldNr_FFA3F6 3000000;
BA_ "CI_ParId" SG_ 2650776566 SBMS_AppLyr_MinRel_FFA3F6 "F363";
BA_ "CI_SigId" SG_ 2650776566 SBMS_AppLyr_MinRel_FFA3F6 45428;
BA_ "CI_SigName" SG_ 2650776566 SBMS_AppLyr_MinRel_FFA3F6 "SBMS_AppLyr_MinRel";
BA_ "GenSigTimeoutTime_PCM" SG_ 2650776566 SBMS_AppLyr_MinRel_FFA3F6 3000000;
BA_ "CI_ParId" SG_ 2650776566 SBMS_AppLyr_MajRel_FFA3F6 "F362";
BA_ "CI_SigId" SG_ 2650776566 SBMS_AppLyr_MajRel_FFA3F6 45427;
BA_ "CI_SigName" SG_ 2650776566 SBMS_AppLyr_MajRel_FFA3F6 "SBMS_AppLyr_MajRel";
BA_ "GenSigTimeoutTime_PCM" SG_ 2650776566 SBMS_AppLyr_MajRel_FFA3F6 3000000;
BA_ "CI_ParId" SG_ 2650776566 SBMS_SftyLyr_BldNr_FFA3F6 "F361";
BA_ "CI_SigId" SG_ 2650776566 SBMS_SftyLyr_BldNr_FFA3F6 45426;
BA_ "CI_SigName" SG_ 2650776566 SBMS_SftyLyr_BldNr_FFA3F6 "SBMS_SftyLyr_BldNr";
BA_ "GenSigTimeoutTime_PCM" SG_ 2650776566 SBMS_SftyLyr_BldNr_FFA3F6 3000000;
BA_ "CI_ParId" SG_ 2650776566 SBMS_SftyLyr_MinRel_FFA3F6 "F360";
BA_ "CI_SigId" SG_ 2650776566 SBMS_SftyLyr_MinRel_FFA3F6 45425;
BA_ "CI_SigName" SG_ 2650776566 SBMS_SftyLyr_MinRel_FFA3F6 "SBMS_SftyLyr_MinRel";
BA_ "GenSigTimeoutTime_PCM" SG_ 2650776566 SBMS_SftyLyr_MinRel_FFA3F6 3000000;
BA_ "CI_ParId" SG_ 2650776566 SBMS_SftyLyr_MajRel_FFA3F6 "F359";
BA_ "CI_SigId" SG_ 2650776566 SBMS_SftyLyr_MajRel_FFA3F6 45424;
BA_ "CI_SigName" SG_ 2650776566 SBMS_SftyLyr_MajRel_FFA3F6 "SBMS_SftyLyr_MajRel";
BA_ "GenSigTimeoutTime_PCM" SG_ 2650776566 SBMS_SftyLyr_MajRel_FFA3F6 3000000;
VAL_ 2350641959 HvessHighVBusPasIsolTestCmd 0 "Pass Isol Test Not requested" 1 "Pass Isol Test Request" 2 "Inhibit Pass Isolation Test" 3 "Don�t Care / Take no action" ;
VAL_ 2350641959 HvessPwrDwCmd 0 "Not requested" 1 "Normal power-down" 2 "Emergency power-down" 3 "Don�t Care / Take no action" ;
VAL_ 2350641959 HvessHighVBusConnCmd 0 "Open Contactor" 1 "Close Contactor" 2 "Emergency closure request" 3 "Don�t Care / Take no action" ;
VAL_ 2350589939 HvessCellBalCmd 0 "Not requested" 1 "Requested" 2 "Reserved" 3 "Don�t Care / Take no action" ;
VAL_ 2364576243 HvessCellVDiffSts 0 "Within acceptable limits" 1 "Out limits, corr. via auto-bal." 2 "Out limits, ext. bal. required" 3 "Out limits, no ext. bal. restore" 4 "Out limits" 5 "Reserved" 6 "Reserved" 12 "Reserved" 13 "Reserved" 14 "Error" 15 "Not Available" ;
VAL_ 2364576499 HvessCellTempDiffSts 0 "Within acceptable limits" 1 "Exceeds acceptable limits" 2 "Error" 3 "Not Available" ;
VAL_ 2364577523 HvessHighVBusConnSts 0 "Disconnected" 1 "Connected" 2 "Connection in Process" 3 "Disconnection in Process" 4 "Disconnected, Precharge Failed" 5 "Reserved" 6 "Reserved" 7 "Reserved" 8 "Reserved" 9 "Reserved" 10 "Reserved" 11 "Reserved" 12 "Reserved" 13 "Reserved" 14 "Error" 15 "Not Available" ;
VAL_ 2364577523 HvessInternChgSts 0 "Charging off" 1 "Charging on" 2 "Error" 3 "Not Available" ;
VAL_ 2364577523 HvessSocSts 0 "Acceptable." 1 "Approaching recomm. lower limit" 2 "At recomm. lower limit" 3 "Below recomm. lower limit" 4 "Approaching recomm. upper limit" 5 "At recomm. upper limit" 6 "Above recomm. upper limit" 7 "Reserved" 8 "Reserved" 9 "Reserved" 10 "Reserved" 11 "Reserved" 12 "Reserved" 13 "Reserved" 14 "Error" 15 "Not Available" ;
VAL_ 2364577523 HvessHvilSts 0 "Closed" 1 "Open" 2 "Error" 3 "Not Available" ;
VAL_ 2364577523 HvessHighVBusPasIsolTestSts 0 "Not requested / Not in process" 1 "Requested but not yet in process" 2 "In process" 3 "Complete, isolation acceptable" 4 "Complete, isolation marginal" 5 "Complete, isolation fault" 6 "Reserved" 7 "Reserved" 8 "Reserved" 9 "Reserved" 10 "Reserved" 11 "Reserved" 12 "Reserved" 13 "Reserved" 14 "Error" 15 "Not Available" ;
VAL_ 2364552947 HvessChgPwrLimDueToAnUndefCause 0 "No power limit for this reason" 1 "Power limited for this reason" 2 "Error" 3 "Not Available" ;
VAL_ 2364552947 HvessChgPwrLimDueToBatCur 0 "No power limit for this reason" 1 "Power limited for this reason" 2 "Error" 3 "Not Available" ;
VAL_ 2364552947 HvessChgPwrLimDueToBatOrCellV 0 "No power limit for this reason" 1 "Power limited for this reason" 2 "Error" 3 "Not Available" ;
VAL_ 2364552947 HvessChgPwrLimDueToBatDiagCond 0 "No power limit for this reason" 1 "Power limited for this reason" 2 "Error" 3 "Not Available" ;
VAL_ 2364552947 HvessChgPwrLimDueToBatTemp 0 "No power limit for this reason" 1 "Power limited for this reason" 2 "Error" 3 "Not Available" ;
VAL_ 2364552947 HvessChgPwrLimDueToSoc 0 "No power limit for this reason" 1 "Power limited for this reason" 2 "Error" 3 "Not Available" ;
VAL_ 2364552947 HvessDischPwrLimDueToAnUndefCaus 0 "No power limit for this reason" 1 "Power limited for this reason" 2 "Error" 3 "Not Available" ;
VAL_ 2364552947 HvessDischPwrLimDueToBatCur 0 "No power limit for this reason" 1 "Power limited for this reason" 2 "Error" 3 "Not Available" ;
VAL_ 2364552947 HvessDischPwrLimDueToBatOrCellV 0 "No power limit for this reason" 1 "Power limited for this reason" 2 "Error" 3 "Not Available" ;
VAL_ 2364552947 HvessDischPwrLimDueToBatDiagCond 0 "No power limit for this reason" 1 "Power limited for this reason" 2 "Error" 3 "Not Available" ;
VAL_ 2364552947 HvessDischPwrLimDueToBatTemp 0 "No power limit for this reason" 1 "Power limited for this reason" 2 "Error" 3 "Not Available" ;
VAL_ 2364552947 HvessDischPwrLimDueToSoc 0 "No power limit for this reason" 1 "Power limited for this reason" 2 "Error" 3 "Not Available" ;
VAL_ 2566901834 PopupIx 0 "Default Popup" 4095 "No Action, No Popup" ;
VAL_ 2566901834 IndIx 0 "Default Indicator" 4095 "No Action, No Indicator" ;
VAL_ 2566901834 BuzLevEx 0 "Level 0" 1 "Level 1" 2 "Level 2" 3 "Level 3" 4 "Level 4" 5 "Level 5" 6 "Level 6" 7 "Level 7" 8 "Level 8" 9 "Level 9" 10 "Level 10" 11 "Level 11" 12 "Level 12" 13 "Level 13" 14 "Level 14" 15 "Not Available, Default Level" ;
VAL_ 2566901834 BuzToneEx 0 "Off" 1 "Preset Tone 1" 2 "Preset Tone 2" 3 "Preset Tone 3" 4 "Preset Tone 4" 5 "Preset Tone 5" 6 "Preset Tone 6" 7 "Preset Tone 7" 8 "Preset Tone 8" 9 "Preset Tone 9" 10 "Preset Tone 10" 11 "Preset Tone 11" 12 "Preset Tone 12" 13 "Preset Tone 13" 14 "Preset Tone 14" 15 "No Available, Default Tone" ;
VAL_ 2566901834 BuzActvModeNew 0 "Off" 1 "On at first occurr. and Start-up" 2 "On" 3 "No Action" ;
VAL_ 2566901834 InfoSev 0 "Lowest severity, No Lamp" 1 "Medium severity, Yellow colour" 2 "Highest severity, Red colour" 3 "No Action" ;
VAL_ 2566901834 InfoActvModeNew 0 "Off" 1 "On at first occurr. and Start-up" 2 "On" 3 "No Action" ;
VAL_ 2566769185 EngOpPriInterSpeedSel 0 "Not requested" 1 "Setting 1 selected" 2 "Setting 2 selected" 3 "Setting 3 selected" 4 "Setting 4 selected" 5 "Setting 5 selected" 6 "Setting 6 selected" 7 "Setting 7 selected" 8 "Setting 8 selected" 9 "Setting 9 selected" 10 "Setting 10 selected" 11 "Setting 11 selected" 12 "Setting 12 selected" 13 "Setting 13 selected" 14 "Error condition" 15 "Not Available" ;
VAL_ 2566786839 TempUnits 0 ": Metric (�C, K, ...)" 1 ": Imperial (�F, ...)" 2 ": Reserved" 3 ": No Action" ;
VAL_ 2566786839 PrsUnits 0 ": Metric (kPa/Pa)" 1 ": Imperial (PSI/...)" 2 ": Reserved" 3 ": No Action" ;
VAL_ 2566786839 UnitsSys 0 ": Metric (km/h)" 1 ": Imperial (Mph)" 2 ": US" 3 ": No Action" ;
VAL_ 2566786839 DistUnitCmd 0 "Metric (km, m, ...)" 1 "Imperial (miles, feet, ..)" 2 "Reserved" 3 "No Action" ;
VAL_ 2566786839 VolUnitCmd 0 "Metric (litre)" 1 "Imperial (gallon)" 2 "US (gallon)" 3 "No Action" ;
VAL_ 2566786839 MassUnitCmd 0 "Metric" 1 "Imperial" 2 "Tons/pounds" 3 "No Action" ;
VAL_ 2566786839 DateCmd 0 "ddmmyyyy" 1 "ddyyyymm" 2 "mmyyyydd" 3 "mmddyyyy" 4 "yyyymmdd" 5 "yyyyddmm" 6 "Reserved" 255 "Reserved" ;
VAL_ 2566786839 DecSymCmd 0 "Comma is used" 1 "Point is used" 2 "Reserved" 3 "No Action" ;
VAL_ 2566786839 TimeCmd 0 "24 hour" 1 "12 hour (am/ pm)" 2 "Reserved" 3 "No Action" ;
VAL_ 2566786881 TempUnits_FE0F41 0 ": Metric (�C, K, ...)" 1 ": Imperial (�F, ...)" 2 ": Reserved" 3 ": No Action" ;
VAL_ 2566786881 PrsUnits_FE0F41 0 ": Metric (kPa/Pa)" 1 ": Imperial (PSI/...)" 2 ": Reserved" 3 ": No Action" ;
VAL_ 2566786881 DistUnitCmd_FE0F41 0 "Metric (km, m, ...)" 1 "Imperial (miles, feet, ..)" 2 "Reserved" 3 "No Action" ;
VAL_ 2566786881 VolUnitCmd_FE0F41 0 "Metric (litre)" 1 "Imperial (gallon)" 2 "US (gallon)" 3 "No Action" ;
VAL_ 2566786881 MassUnitCmd_FE0F41 0 "Metric" 1 "Imperial" 2 "Tons/pounds" 3 "No Action" ;
VAL_ 2566786881 DateCmd_FE0F41 0 "ddmmyyyy" 1 "ddyyyymm" 2 "mmyyyydd" 3 "mmddyyyy" 4 "yyyymmdd" 5 "yyyyddmm" 6 "Reserved" 255 "Reserved" ;
VAL_ 2566786881 TimeCmd_FE0F41 0 "24 hour" 1 "12 hour (am/ pm)" 2 "Reserved" 3 "No Action" ;
VAL_ 2365473057 TractRearHighMountWorkLightCmd 0 "De-activate" 1 "Activate" 2 "Reserved" 3 "Don�t Care" ;
VAL_ 2365473057 RearFogLightCmd 0 "De-activate" 1 "Activate" 2 "Reserved" 3 "Don�t Care" ;
VAL_ 2365473057 TractMarkerLightCmd 0 "De-activate" 1 "Activate" 2 "Reserved" 3 "Don�t Care" ;
VAL_ 2365473057 TractClearLightCmd 0 "De-activate" 1 "Activate" 2 "Reserved" 3 "Don�t Care" ;
VAL_ 2365473057 LeftStopLightCmd 0 "De-activate" 1 "Activate" 2 "Reserved" 3 "Don�t Care" ;
VAL_ 2365473057 RightStopLightCmd 0 "De-activate" 1 "Activate" 2 "Reserved" 3 "Don�t Care" ;
VAL_ 2365473057 CentStopLightCmd 0 "De-activate" 1 "Activate" 2 "Reserved" 3 "Don�t Care" ;
VAL_ 2365473057 BackUpLightAndAlarmHornCmd 0 "De-activate" 1 "Activate" 2 "Reserved" 3 "Don�t Care" ;
VAL_ 2365473057 LeftTurnSigLightCmd 0 "De-activate" 1 "Activate" 2 "Reserved" 3 "Don�t Care" ;
VAL_ 2365473057 RightTurnSigLightCmd 0 "De-activate" 1 "Activate" 2 "Reserved" 3 "Don�t Care" ;
VAL_ 2365473057 TractFrontFogLightCmd 0 "De-activate" 1 "Activate" 2 "Reserved" 3 "Don�t Care" ;
VAL_ 2365473057 HighBeamHeadLightCmd 0 "De-activate" 1 "Activate" 2 "Reserved" 3 "Don�t Care" ;
VAL_ 2365473057 LowBeamHeadLightCmd 0 "De-activate" 1 "Activate" 2 "Reserved" 3 "Don�t Care" ;
VAL_ 2365473057 RunLightCmd 0 "De-activate" 1 "Activate" 2 "Reserved" 3 "Don�t Care" ;
VAL_ 2365473066 HighBeamHeadLightCmd_E412A 0 "De-activate" 1 "Activate" 2 "Reserved" 3 "Don�t Care" ;
VAL_ 2566844928 EngInstFuelEcon_FEF200 64256 "Infinite" ;
VAL_ 2566670131 A4MonTireCnt 15 "Not Available" ;
VAL_ 2566670131 A3MonTireCnt 15 "Not Available" ;
VAL_ 2566670131 A2MonTireCnt 15 "Not Available" ;
VAL_ 2566670131 A1MonTireCnt 15 "Not Available" ;
VAL_ 2566898977 MsgCks_FFC521 15 "Not Available, request honored" ;
VAL_ 2566898977 MsgCnt_FFC521 8 "Reserved1" 9 "Reserved2" 10 "Reserved3" 11 "Reserved4" 12 "Reserved5" 13 "Reserved6" 14 "Reserved7" 15 "Not Available, request honored" ;
VAL_ 2566898977 EmerShutdnSwSts 0 "Off" 1 "On" 2 "Error" 3 "Not Available" ;
VAL_ 2566898977 WiperCtrlSts 0 "Off" 1 "On Low" 2 "On - Intermittent" 3 "On - High Speed" 6 "Error" 7 "Not available" ;
VAL_ 2566898977 EassVisCode 0 "No Visualization" 1 "Code 1" 2 "Code 2" 3 "Code 3" 4 "Code 4 (S&S)" 5 "Code 5 (S&S)" 6 "Code 6" 7 "Code 7" ;
VAL_ 2566898977 EassActvSts 0 "Activated" 1 "Deactivated" ;
VAL_ 2566898977 EmerHandKeyLckdSts 0 "Not Locked" 1 "Locked" 2 "Error" 3 "Not Available" ;
VAL_ 2566898977 BatLampSts 0 "Off" 1 "On Fixed" 2 "On Flashing" ;
VAL_ 2566898977 PwrModeSts 0 "Standard power" 1 "Logistic Mode On" 2 "Logistic Mode PR" 3 "LogisticModeOn + EngineOn" ;
VAL_ 2566898977 FpsSts 0 "Not active" 1 "Active" ;
VAL_ 2566898977 ImmoCodeWarnLightSts 1 "Protocol not started" 2 "Protocol KO" 3 "Marriage protocol OK" 4 "Verify protocol OK" 5 "Protocol Retry" 6 "Txp KO, BCM not programmed" 7 "Txp KO, Keys not valid" 8 "Txp OK" 9 "ECM not married, BCM not married" 10 "ECM not married, BCM married" 11 "ECM married, BCM not married" 12 "ECM married, BCM married" 13 "Not Used" 14 "Not Used" 15 "Not available" ;
VAL_ 2566898977 BrkPadWearSts 0 "Ok" 1 "Nok" 2 "Error" 3 "Not Available" ;
VAL_ 2566898977 BrkFluidLevLow 0 "Normal" 1 "Below operating range" 2 "Error" 3 "Not Available" ;
VAL_ 2566898977 CeilLightSts 0 "Off" 1 "On" 2 "Error" 3 "Not Available" ;
VAL_ 2566898977 SysEolSts 0 "EOL Ready" 1 "EOL Not Ready" ;
VAL_ 2566898977 BrkPedSts 0 "Off" 1 "On" ;
VAL_ 2566898977 CrashOutSts 0 "No crash" 1 "Front Pretensioner" 2 "Front First Level" 4 "Front Second Level" 8 "Right Hand Side" 16 "Left Hand Side" 32 "Rear" 64 "Rollover" 128 "Pedestrian" ;
VAL_ 2566898977 WiperCtrl 0 "Off" 1 "On" 2 "Error" 3 "Not Available" ;
VAL_ 2566898977 VehAtStStill 0 "Not at standstill" 1 "At standstill" 2 "Error" 3 "Not Available" ;
VAL_ 2566898977 PlugDoorBtn 0 "Off" 1 "On" 2 "Error" 3 "Not Available" ;
VAL_ 2566898977 EngWaterLev 0 "Normal level" 1 "Low level" 2 "Error" 3 "Not Available" ;
VAL_ 2566898977 SpotStsRear 0 "Off" 1 "On" 2 "Error" 3 "Not Available" ;
VAL_ 2566898977 PtoDrivResp 0 "Terminate PTO mission" 1 "Continue PTO mission" 2 "Not used" 3 "Response pending" ;
VAL_ 2566898977 SeatBeltRemindSts 0 "Fasten" 1 "Unfasten" 2 "Error" 3 "Not Available" ;
VAL_ 2566898977 InternLightSts 0 "Off" 1 "On" ;
VAL_ 2566898977 RechargeSts 0 "Charging" 1 "Not charging" ;
VAL_ 2499614241 DrivOccpClassSysSts 0 "Empty" 1 "Child" 2 "Small adult" 3 "Adult" 4 "Large adult" 5 "Reserved" 6 "Error, cannot be determined" 7 "Not Available" ;
VAL_ 2499614291 OccpClassSys3Sts 0 "Empty" 1 "Occupied" 2 "Error, cannot be determined" 3 "Not Available" ;
VAL_ 2499614291 PassOccpClassSysSts 0 "Empty" 1 "Child" 2 "Small adult" 3 "Adult" 4 "Large adult" 5 "Reserved" 6 "Error, cannot be determined" 7 "Not Available" ;
VAL_ 2499614291 DrivOccpClassSysSts_FD1653 0 "Empty" 1 "Child" 2 "Small adult" 3 "Adult" 4 "Large adult" 5 "Reserved" 6 "Error, cannot be determined" 7 "Not Available" ;
VAL_ 2365443105 HighLowBeamSw 0 "Low Beam Selected" 1 "High Beam Selected" 2 "Error" 3 "Not Available (do not change)" ;
VAL_ 2365443105 HazardLightSw 0 "Hazard Lamps to be Off" 1 "Hazard Lamps to be Flashing" 2 "Error" 3 "Not Available (do not change)" ;
VAL_ 2365443105 TurnSigSw 0 "No Turn being signaled" 1 "Left Turn to be Flashing" 2 "Right turn to be Flashing" 14 "Error, left + right sel. simult." 15 "Not Available (do not change)" ;
VAL_ 2365443105 MainLightSw 0 "Off" 1 "Park On" 2 "Headlight On" 3 "Headlight and Park On" 4 "Automatic Lights" 5 "Reserved1" 6 "Reserved2" 7 "Reserved3" 8 "Delayed Off" 9 "Reserved4" 10 "Reserved5" 11 "Reserved6" 12 "Reserved7" 13 "Reserved8" 14 "Error" 15 "Not Available (do not change)" ;
VAL_ 2566769953 FrontOpWiperSw 0 "Off" 1 "Low" 2 "Medium" 3 "High" 4 "Delayed 1" 5 "Delayed 2" 6 "Mist" 7 "Reserved (Panic)" 14 "Error" 15 "Not Available / Do not change" ;
VAL_ 2565865249 ImmoEmerProc 0 "Ready for Code" 1 "Waiting Time" 2 "Waiting Time" 3 "Waiting Time" 4 "Waiting Time" 5 "Waiting Time" 6 "Waiting Time" 7 "Waiting Time" 8 "Waiting Time" 9 "Waiting Time" 10 "Waiting Time" 11 "Waiting Time" 12 "Waiting Time" 13 "Waiting Time" 14 "Waiting Time" 15 "Waiting Time" 16 "Waiting Time" 17 "Waiting Time" 18 "Waiting Time" 19 "Waiting Time" 20 "Waiting Time" 21 "Waiting Time" 22 "Waiting Time" 23 "Waiting Time" 24 "Waiting Time" 25 "Waiting Time" 26 "Waiting Time" 27 "Waiting Time" 28 "Waiting Time" 29 "Waiting Time" 30 "Waiting Time" 31 "Waiting Time" 32 "Waiting Time" 33 "Waiting Time" 34 "Waiting Time" 35 "Waiting Time" 36 "Waiting Time" 37 "Waiting Time" 38 "Waiting Time" 39 "Waiting Time" 40 "Waiting Time" 41 "Waiting Time" 42 "Waiting Time" 43 "Waiting Time" 44 "Waiting Time" 45 "Waiting Time" 46 "Waiting Time" 47 "Waiting Time" 48 "Waiting Time" 49 "Waiting Time" 50 "Waiting Time" 51 "Waiting Time" 52 "Waiting Time" 53 "Waiting Time" 54 "Waiting Time" 55 "Waiting Time" 56 "Waiting Time" 57 "Waiting Time" 58 "Waiting Time" 59 "Waiting Time" 60 "Waiting Time" 61 "Waiting Time" 62 "Waiting Time" 63 "Waiting Time" 64 "Waiting Time" 65 "Waiting Time" 66 "Waiting Time" 67 "Waiting Time" 68 "Waiting Time" 69 "Waiting Time" 70 "Waiting Time" 71 "Waiting Time" 72 "Waiting Time" 73 "Waiting Time" 74 "Waiting Time" 75 "Waiting Time" 76 "Waiting Time" 77 "Waiting Time" 78 "Waiting Time" 79 "Waiting Time" 80 "Waiting Time" 81 "Waiting Time" 82 "Waiting Time" 83 "Waiting Time" 84 "Waiting Time" 85 "Waiting Time" 86 "Waiting Time" 87 "Waiting Time" 88 "Waiting Time" 89 "Waiting Time" 90 "Waiting Time" 91 "Waiting Time" 92 "Waiting Time" 93 "Waiting Time" 94 "Waiting Time" 95 "Waiting Time" 96 "Waiting Time" 97 "Waiting Time" 98 "Waiting Time" 99 "Waiting Time" 100 "Waiting Time" 101 "Waiting Time" 102 "Waiting Time" 103 "Waiting Time" 104 "Waiting Time" 105 "Waiting Time" 106 "Waiting Time" 107 "Waiting Time" 108 "Waiting Time" 109 "Waiting Time" 110 "Waiting Time" 111 "Waiting Time" 112 "Waiting Time" 113 "Waiting Time" 114 "Waiting Time" 115 "Waiting Time" 116 "Waiting Time" 117 "Waiting Time" 118 "Waiting Time" 119 "Waiting Time" 120 "Waiting Time" 121 "Waiting Time" 122 "Waiting Time" 123 "Waiting Time" 124 "Waiting Time" 125 "Waiting Time" 126 "Waiting Time" 127 "Waiting Time" 128 "Waiting Time" 129 "Waiting Time" 130 "Waiting Time" 131 "Waiting Time" 132 "Waiting Time" 133 "Waiting Time" 134 "Waiting Time" 135 "Waiting Time" 136 "Waiting Time" 137 "Waiting Time" 138 "Waiting Time" 139 "Waiting Time" 140 "Waiting Time" 141 "Waiting Time" 142 "Waiting Time" 143 "Waiting Time" 144 "Waiting Time" 145 "Waiting Time" 146 "Waiting Time" 147 "Waiting Time" 148 "Waiting Time" 149 "Waiting Time" 150 "Waiting Time" 151 "Waiting Time" 152 "Waiting Time" 153 "Waiting Time" 154 "Waiting Time" 155 "Waiting Time" 156 "Waiting Time" 157 "Waiting Time" 158 "Waiting Time" 159 "Waiting Time" 160 "Waiting Time" 161 "Waiting Time" 162 "Waiting Time" 163 "Waiting Time" 164 "Waiting Time" 165 "Waiting Time" 166 "Waiting Time" 167 "Waiting Time" 168 "Waiting Time" 169 "Waiting Time" 170 "Waiting Time" 171 "Waiting Time" 172 "Waiting Time" 173 "Waiting Time" 174 "Waiting Time" 175 "Waiting Time" 176 "Waiting Time" 177 "Waiting Time" 178 "Waiting Time" 179 "Waiting Time" 180 "Waiting Time" 181 "Waiting Time" 182 "Waiting Time" 183 "Waiting Time" 184 "Waiting Time" 185 "Waiting Time" 186 "Waiting Time" 187 "Waiting Time" 188 "Waiting Time" 189 "Waiting Time" 190 "Waiting Time" 191 "Waiting Time" 192 "Waiting Time" 193 "Waiting Time" 194 "Waiting Time" 195 "Waiting Time" 196 "Waiting Time" 197 "Waiting Time" 198 "Waiting Time" 199 "Waiting Time" 200 "Waiting Time" 201 "Waiting Time" 202 "Waiting Time" 203 "Waiting Time" 204 "Waiting Time" 205 "Waiting Time" 206 "Waiting Time" 207 "Waiting Time" 208 "Waiting Time" 209 "Waiting Time" 210 "Waiting Time" 211 "Waiting Time" 212 "Waiting Time" 213 "Waiting Time" 214 "Waiting Time" 215 "Waiting Time" 216 "Waiting Time" 217 "Waiting Time" 218 "Waiting Time" 219 "Waiting Time" 220 "Waiting Time" 221 "Waiting Time" 222 "Waiting Time" 223 "Waiting Time" 224 "Waiting Time" 225 "Waiting Time" 226 "Waiting Time" 227 "Waiting Time" 228 "Waiting Time" 229 "Waiting Time" 230 "Waiting Time" 231 "Waiting Time" 232 "Waiting Time" 233 "Waiting Time" 234 "Waiting Time" 235 "Waiting Time" 236 "Waiting Time" 237 "Waiting Time" 238 "Waiting Time" 239 "Waiting Time" 240 "Waiting Time" 241 "Waiting Time" 242 "Waiting Time" 243 "Waiting Time" 244 "Waiting Time" 245 "Waiting Time" 246 "Waiting Time" 247 "Waiting Time" 248 "Waiting Time" 249 "Waiting Time" 250 "Waiting Time" 251 "No Key found" 252 "Wrong key" 253 "No more retries / timeout" 254 "Error Indicator" 255 "Not Available / No Emerg. Proc." ;
VAL_ 2566907681 EvsCmd 0 "Position 0" 1 "Position 1" 2 "Position 2" 3 "Position 3" 4 "Position 4" 5 "Reserved" 6 "Error" 7 "Not Available" ;
VAL_ 2566907681 PtcCabPumpCmd 0 "Active" 1 "Not Active" 2 "Error" 3 "Not Available" ;
VAL_ 2566907681 HvacPtcCabCmd 0 "Active" 1 "Not Active" 2 "Error" 3 "Not Available" ;
VAL_ 2566907681 ElFanCmd 0 "Active" 1 "Not Active" 2 "Error" 3 "Not Available" ;
VAL_ 2566907943 ClimaWorkMode 0 "Normal Mode" 1 "Eco Mode" 2 "Error" 3 "Not Available/no action" ;
VAL_ 2566907943 EvsSts 0 "Position 0" 1 "Position 1" 2 "Position 2" 3 "Position 3" 4 "Position 4" 5 "Reserved" 6 "Error" 7 "Not Available" ;
VAL_ 2566907943 AewhSts 0 "Not Active" 1 "Active" 2 "Error" 3 "Not Available" ;
VAL_ 2566907943 PtcCabPumpSts 0 "Active" 1 "Not Active" 2 "Error" 3 "Not Available" ;
VAL_ 2566907943 HvacPtcCabSts 0 "Active" 1 "Not Active" 2 "Error" 3 "Not Available" ;
VAL_ 2566907943 ElFanSts 0 "Active" 1 "Not Active" 2 "Error" 3 "Not Available" ;
VAL_ 2566895127 DdawAcousticWarnCfg 0 "Not Enabled" 1 "Enabled" 2 "Error" 3 "Not available" ;
VAL_ 2566895127 DdawSens 0 "Low" 1 "Medium" 2 "High" 3 "Not Available" ;
VAL_ 2566895127 DdawWarnCfg 0 "On" 1 "Mute" 2 "Error" 3 "Not available" ;
VAL_ 2566895127 LaneChgAssCfg 0 "Not Enabled" 1 "Enabled" 2 "Error" 3 "Not available" ;
VAL_ 2566895127 DoorOpenWarnFunctCfg 0 "Not Enabled" 1 "Enabled" 2 "Error" 3 "Not available" ;
VAL_ 2566895137 AlcoholIntLckCrkEnaSts 0 "Enabled" 1 "Inhibited and not required" 2 "Inhibited and required" 6 "Error" 7 "Not Available" ;
VAL_ 2566895146 DdawAcousticWarn 0 "No Warning" 1 "Warning Active" 2 "Reserved" 3 "Not Available" ;
VAL_ 2566895146 DdawVisualWarn 0 "No Warning" 1 "Warning Active" 2 "Reserved" 3 "Not Available" ;
VAL_ 2566895146 DdawRunMode 0 "Inactive" 1 "Active" 2 "Error" 3 "Not Available - Init" ;
VAL_ 2566895146 DrowsinessDrivLev 0 "Not Used" 1 "Level 1" 2 "Level 2" 3 "Level 3" 4 "Level 4" 5 "Level 5" 6 "Level 6" 7 "Level 7" 8 "Level 8" 9 "Level 9" 10 "Level 10" 11 "Res" 12 "Res" 13 "Res" 14 "Error" 15 "Not Available" ;
VAL_ 2566895178 DoorOpenWarnFunctCfg_FFB64A 0 "Not Enabled" 1 "Enabled" 2 "Error" 3 "Not available" ;
VAL_ 2566895260 DoorOpenWarnFunctStsLeft 0 "Not Active" 1 "Active" 2 "Error" 3 "Not available / Invalid" ;
VAL_ 2566895260 DoorOpenWarnFunctStsRight 0 "Not Active" 1 "Active" 2 "Error" 3 "Not available / Invalid" ;
VAL_ 2566895260 DoorOpenWarnAlertLeft 0 "OFF/ No Warn" 1 "Warn Lev 1" 2 "Warn Lev 2" 3 "Not available/Invalid" ;
VAL_ 2566895260 DoorOpenWarnAlertRight 0 "OFF/ No Warn" 1 "Warn Lev 1" 2 "Warn Lev 2" 3 "Not available/Invalid" ;
VAL_ 2583654703 MsgCks_FF712F 15 "Not Available, request honored" ;
VAL_ 2583654703 MsgCnt_FF712F 8 "Reserved1" 9 "Reserved2" 10 "Reserved3" 11 "Reserved4" 12 "Reserved5" 13 "Reserved6" 14 "Reserved7" 15 "Not Available, request honored" ;
VAL_ 2583654703 EcasCustomInds 0 "No lamp" 1 "Level Not Available" 2 "Release Brake Pedal" 3 "Engage Handbrake" 4 "Level Reached" 5 "Level Stored" 6 "System maintenance" 8 "Not Used" 9 "Not Used" 10 "Not Used" 11 "Not Used" 12 "Not Used" 13 "Not Used" 14 "Error" 15 "Not Available" ;
VAL_ 2583654703 RsvAv 0 "Reservoir not available" 1 "Reservoir available" 2 "Error" 3 "Not Available/No Action" ;
VAL_ 2583654703 FusyLamps 0 "No Lamp" 1 "Yellow - Out of Trim" 2 "Red - Out of Trim" 3 "Red - Suspension Fault" 4 "Not Used" 5 "Not Used" 6 "Error" 7 "Not Available" ;
VAL_ 2583654703 SamReq 0 ": SAM Smart Logic ON Request" 1 ": SAM Smart Logic OFF Request" 2 ": SAM Fast Recharge Sts Request" 3 ": Not Used" 4 ": Not Used" 5 ": Not Used" 6 ": Error" 7 ": Not Available" ;
VAL_ 2583654703 MemRearEnd 0 ": Not pressed" 1 ": Pressed" 2 ": Error" 3 ": Not Available" ;
VAL_ 2583654703 DwRearEnd 0 ": Not pressed" 1 ": Pressed" 2 ": Error" 3 ": Not Available" ;
VAL_ 2583654703 UpRearEnd 0 ": Not pressed" 1 ": Pressed" 2 ": Error" 3 ": Not Available" ;
VAL_ 2583654703 MemDashboard 0 ": Not pressed" 1 ": Pressed" 2 ": Error" 3 ": Not Available" ;
VAL_ 2583654703 StoredVehHtVal 251 "Reserved" 252 "Reserved" 253 "Reserved" 254 "Error" 255 "Not Available" ;
VAL_ 2583654703 CurVehHtVal 251 "Reserved" 252 "Reserved" 253 "Reserved" 254 "Error" 255 "Not Available" ;
VAL_ 2583654703 DrivDashboard 0 ": Not pressed" 1 ": Pressed" 2 ": Error" 3 ": Not Available" ;
VAL_ 2583654703 DwDashboard 0 ": Not pressed" 1 ": Pressed" 2 ": Error" 3 ": Not Available" ;
VAL_ 2583654703 UpDashboard 0 ": Not pressed" 1 ": Pressed" 2 ": Error" 3 ": Not Available" ;
VAL_ 2583654703 TurnLightCmd 0 "OFF" 1 "ON" 2 "Error" 3 "Not Available" ;
VAL_ 2566902551 WindshWiperAutoSens 0 "Auto, Level 0" 1 "Auto, Level 1" 2 "Auto, Level 2" 3 "Not used" 4 "Not used" 5 "Manual Mode" 6 "Error Indicator" 7 "Not Available / No Action" ;
VAL_ 2566902551 LowBeamLightAutoSens 0 "Level 0 - Low" 1 "Level 1 - Mid" 2 "Level 2 - High" 3 "Not used" 4 "Not used" 5 "Not used" 6 "Error Indicator" 7 "Not Available / No Action" ;
VAL_ 2566902551 FogLightCornEna 0 "Disable" 1 "Enable" 2 "Reserved" 3 "Not Available / No Action" ;
VAL_ 2566902551 DrlEna 0 "Disable" 1 "Enable" 2 "DRL Extended" 3 "Not Available / No Action" ;
VAL_ 2566902551 AhbcEna 0 "Not enabled" 1 "Enabled" 2 "Error Indicator" 3 "Not Available / Take no action" ;
VAL_ 2566902602 AhbcEna_FFD34A 0 "Not enabled" 1 "Enabled" 2 "Error Indicator" 3 "Not Available / Take no action" ;
VAL_ 2583642355 Pbmu1Stbat 0 "Initialization" 1 "Standby" 2 "Pre-Charge" 3 "HV On" 4 "HV Off" 5 "Emergency stop" 6 "Sleep" 7 "Not available/no action" ;
VAL_ 2583642611 Pbmu2Stbat 0 "Initialization" 1 "Standby" 2 "Pre-Charge" 3 "HV On" 4 "HV Off" 5 "Emergency stop" 6 "Sleep" 7 "Not available/no action" ;
VAL_ 2583642867 Pbmu3Stbat 0 "Initialization" 1 "Standby" 2 "Pre-Charge" 3 "HV On" 4 "HV Off" 5 "Emergency stop" 6 "Sleep" 7 "Not available/no action" ;
VAL_ 2583640051 Pbmu4Stbat 0 "Initialization" 1 "Standby" 2 "Pre-Charge" 3 "HV On" 4 "HV Off" 5 "Emergency stop" 6 "Sleep" 7 "Not available/no action" ;
VAL_ 2583640307 Pbmu5Stbat 0 "Initialization" 1 "Standby" 2 "Pre-Charge" 3 "HV On" 4 "HV Off" 5 "Emergency stop" 6 "Sleep" 7 "Not available/no action" ;
VAL_ 2583639312 MsgCnt_FF3510 8 "Reserved1" 9 "Reserved2" 10 "Reserved3" 11 "Reserved4" 12 "Reserved5" 13 "Reserved6" 14 "Reserved7" 15 "Not Available, request honored" ;
VAL_ 2583639312 DirCtrlSig 0 "Anti Clockwise" 1 "Clockwise" 2 "Error" 3 "Not Available" ;
VAL_ 2583639312 InternHvIntLckSts 0 "Not active" 1 "Active" 2 "Error" 3 "Not available" ;
VAL_ 2583639312 ExtdeviceEPtoSwOff 0 "Not active" 1 "Active" 2 "Error" 3 "Not available" ;
VAL_ 2583639312 ConnEngReq 0 "Connection not requested" 1 "Connection requested" 2 "Error" 3 "Not available" ;
VAL_ 2583639370 ExtdeviceEPtoSwOff_FF354A 0 "Not active" 1 "Active" 2 "Error" 3 "Not available" ;
VAL_ 2583636594 BbPwrReq 0 "No Power Req" 1 "BB Power Req" 2 "Error" 3 "Not Available" ;
VAL_ 2583636594 BsisBbInhReq 0 "Not Inhibited" 1 "Inhibited" 2 "Error" 3 "Not Available" ;
VAL_ 2583636594 MoisBbInhReq 0 "Not Inhibited" 1 "Inhibited" 2 "Error" 3 "Not Available" ;
VAL_ 2583636594 AebsBbInhReq 0 "Not Inhibited" 1 "Inhibited" 2 "Error" 3 "Not Available" ;
VAL_ 2566894625 RearCeilLight 0 "Off" 1 "On" 2 "Error" 3 "Not Available" ;
VAL_ 2566894625 CentCeilLight 0 "Off" 1 "On" 2 "Error" 3 "Not Available" ;
VAL_ 2566894625 LatRightCeilLight 0 "Off" 1 "On" 2 "Error" 3 "Not Available" ;
VAL_ 2566894625 LatLeftCeilLight 0 "Off" 1 "On" 2 "Error" 3 "Not Available" ;
VAL_ 2566894625 BcmDowFail 0 "No Fail Present" 1 "Fail Present" 2 "Error" 3 "Not Available" ;
VAL_ 2566894625 BcmRctFail 0 "No Fail Present" 1 "Fail Present" 2 "Error" 3 "Not Available" ;
VAL_ 2566894625 BcmBsisFail 0 "No Fail Present" 1 "Fail Present" 2 "Error" 3 "Not Available" ;
VAL_ 2566894625 BcmBsFail 0 "No Fail Present" 1 "Fail Present" 2 "Error" 3 "Not Available" ;
VAL_ 2566894625 FrontCeilLight 0 "Off" 1 "On" 2 "Error" 3 "Not Available" ;
VAL_ 2566894625 RearDiffLckCtrlFail 0 "No Fault Present" 1 "Fault Present" 2 "Severe Fault Present" 3 "Not Available" ;
VAL_ 2566894625 VehBatVLowLampSts 0 "Off" 1 "On" 2 "Error" 3 "Not Available" ;
VAL_ 2566894625 BrkSw_FFB421 0 "Released" 1 "Depressed" 2 "Error" 3 "Not Available" ;
VAL_ 2566894625 RearDiffLckSts 0 "Not Engaged" 1 "Engaged" 2 "Error" 3 "Not Available" ;
VAL_ 2566894625 EngWaterLev_FFB421 0 "Normal level" 1 "Low level" 2 "Error" 3 "Not Available" ;
VAL_ 2566894625 HeadbeamAdjPos 0 "Position 0" 1 "Position 1" 2 "Position 2" 3 "Position 3" 4 "Reserved" 5 "Reserved" 6 "Error" 7 "Not Available" ;
VAL_ 2566894625 DieselFiltBlk 0 "Off" 1 "On" ;
VAL_ 2566894625 AirFiltBlk 0 "Off" 1 "On" ;
VAL_ 2566894625 PtcFail 0 "No fault present" 1 "Fault present" ;
VAL_ 2566894625 PtcSts 0 "0 0 %" 1 "33 %" 2 "66 %" 3 "100 %" ;
VAL_ 2566894625 CondNeededForEnaAutoStop 0 "False" 1 "True" ;
VAL_ 2566894625 CrkPossInAutoStop 0 "Remain in Stop" 1 "Recrank engine" ;
VAL_ 2566894625 CrkModeAllwInAutoStop 0 "AutoCrank disabled" 1 "AutoCrank enabled" ;
VAL_ 2566894625 EassMngReq 0 "Off" 1 "On" ;
VAL_ 2566894625 EassSafeModeIndSts 0 "Not Active" 1 "Door Check Safe Mode" 2 "Vehicle Left Safe Mode" 3 "Not used" ;
VAL_ 2566894625 RearHeatWndSts 0 "Off" 1 "On" ;
VAL_ 2566894625 DrivStyleSts 0 "Normal" 1 "City (Not used)" 2 "Sport (Not used)" 3 "Winter (Not used)" 4 "Eco" 7 "Not Available" ;
VAL_ 2566894625 ComprAcReqSts 0 "Not active" 1 "Active" 2 "Error" 3 "Not Available" ;
VAL_ 2566894625 GearModesReq 0 "Eco Lock" 1 "Power Lock" 2 "Error" 3 "Not Available" ;
VAL_ 2566894625 EcoLckEng 0 "No Eco Lock" 1 "Eco Lock" 2 "Error" 3 "Not Available" ;
VAL_ 2566888481 LightSwReq 0 "Light off" 1 "Light on" 2 "Reserved" 3 "not available" ;
